VERSION ""

NS_ :

BS_:

BU_: PowertrainControlModule AtmosphericSensor SafetyRestraintSystem2 Aftertreatment_2_GasOutlet Aftertreatment_2_GasIntake DieselParticulateFilterControl Turbocharger SafetyRestraintSystem1 CabDisplay2 Aftertreatment_1_GasOutlet Aftertreatment_1_GasIntake OnBoardDataLogger OffBoardDiagnosticTool2 OffBoardDiagnosticTool1 FileServer ParkingBrakeController SeatController2 FanDriveController SteeringColumnUnit CommunicationUnitRadio CommunicationUnitSatellite CommunicationUnitCellular PropulsionBatteryCharger ChassisController2 ChassisController1 EngineValveControl AuxiliaryHeater2 AuxiliaryHeater1 ClutchUnit RampControl InformationSystem1 SuspensionSystemController2 OilSensor VehicleDynamicStability ExhaustEmissionController TransmissionDisplay2 TransmissionDisplay1 ClimateControl2 WaterPumpController RearAxleSteeringController LightingOperatorControl SeatController1 IgnitionController2 IgnitionController1 TirePressureController CabController2 CabController1 PneumaticSystemController SuspensionSystemController1 HydraulicPumpController EnduranceBrakingSystem RetarderExhaustEngine2 OnBoardDiagnosticUnit HeadwayController RetarderExhaustEngine1 CabDisplay1 ManagementComputer VirtualTerminal OffVehicleGateway PowerTakeOffFront HitchControl AuxiliaryValveControl BodyController TractorTrailerBridge1 StarterSystem ElectricalSystem VehicleSecurity VehicleNavigation AerodynamicControl ElectricalChargingSystem ClimateControl1 TripRecorder InstrumentCluster SuspensionDriveAxle2 SuspensionDriveAxle1 SuspensionSteerAxle SteeringController FuelSystem CruiseControl RetarderDriveline RetarderEngine BrakesDriveAxle2 BrakesDriveAxle1 BrakesSystemController BrakesSteerAxle AxleDrive2 AxleDrive1 AxleSteering PowerTakeOff ShiftConsoleSecondary ShiftConsolePrimary Transmission2 Transmission1 Engine2 Engine1

BO_ 2566741758 DM42: 22 Vector__XXX
 SG_ FlashRedStopLamp : 12|2@1+ (1,0) [0|3] "" Vector__XXX
 SG_ FlashProtectLamp : 8|2@1+ (1,0) [0|3] "" Vector__XXX
 SG_ FlashMalfuncIndicatorLamp : 14|2@1+ (1,0) [0|3] "" Vector__XXX
 SG_ FlashAmberWarningLamp : 10|2@1+ (1,0) [0|3] "" Vector__XXX
 SG_ MalfunctionIndicatorLampStatus : 6|2@1+ (1,0) [0|3] "" Vector__XXX
 SG_ AmberWarningLampStatus : 2|2@1+ (1,0) [0|3] "" Vector__XXX
 SG_ RedStopLampState : 4|2@1+ (1,0) [0|3] "" Vector__XXX
 SG_ ProtectLampStatus : 0|2@1+ (1,0) [0|3] "" Vector__XXX
 SG_ DTC5 : 144|32@1+ (1,0) [0|4294967295] "" Vector__XXX
 SG_ DTC4 : 112|32@1+ (1,0) [0|4294967295] "" Vector__XXX
 SG_ DTC3 : 80|32@1+ (1,0) [0|4294967295] "" Vector__XXX
 SG_ DTC2 : 48|32@1+ (1,0) [0|4294967295] "" Vector__XXX
 SG_ DTC1 : 16|32@1+ (1,0) [0|4294967295] "" Vector__XXX

BO_ 2566742014 DM41: 22 Vector__XXX
 SG_ FlashRedStopLamp : 12|2@1+ (1,0) [0|3] "" Vector__XXX
 SG_ FlashProtectLamp : 8|2@1+ (1,0) [0|3] "" Vector__XXX
 SG_ FlashMalfuncIndicatorLamp : 14|2@1+ (1,0) [0|3] "" Vector__XXX
 SG_ FlashAmberWarningLamp : 10|2@1+ (1,0) [0|3] "" Vector__XXX
 SG_ MalfunctionIndicatorLampStatus : 6|2@1+ (1,0) [0|3] "" Vector__XXX
 SG_ AmberWarningLampStatus : 2|2@1+ (1,0) [0|3] "" Vector__XXX
 SG_ RedStopLampState : 4|2@1+ (1,0) [0|3] "" Vector__XXX
 SG_ ProtectLampStatus : 0|2@1+ (1,0) [0|3] "" Vector__XXX
 SG_ DTC5 : 144|32@1+ (1,0) [0|4294967295] "" Vector__XXX
 SG_ DTC4 : 112|32@1+ (1,0) [0|4294967295] "" Vector__XXX
 SG_ DTC3 : 80|32@1+ (1,0) [0|4294967295] "" Vector__XXX
 SG_ DTC2 : 48|32@1+ (1,0) [0|4294967295] "" Vector__XXX
 SG_ DTC1 : 16|32@1+ (1,0) [0|4294967295] "" Vector__XXX

BO_ 2560622334 DM35: 22 Vector__XXX
 SG_ FlashRedStopLamp : 12|2@1+ (1,0) [0|3] "" Vector__XXX
 SG_ FlashProtectLamp : 8|2@1+ (1,0) [0|3] "" Vector__XXX
 SG_ FlashMalfuncIndicatorLamp : 14|2@1+ (1,0) [0|3] "" Vector__XXX
 SG_ FlashAmberWarningLamp : 10|2@1+ (1,0) [0|3] "" Vector__XXX
 SG_ MalfunctionIndicatorLampStatus : 6|2@1+ (1,0) [0|3] "" Vector__XXX
 SG_ AmberWarningLampStatus : 2|2@1+ (1,0) [0|3] "" Vector__XXX
 SG_ RedStopLampState : 4|2@1+ (1,0) [0|3] "" Vector__XXX
 SG_ ProtectLampStatus : 0|2@1+ (1,0) [0|3] "" Vector__XXX
 SG_ DTC5 : 144|32@1+ (1,0) [0|4294967295] "" Vector__XXX
 SG_ DTC4 : 112|32@1+ (1,0) [0|4294967295] "" Vector__XXX
 SG_ DTC3 : 80|32@1+ (1,0) [0|4294967295] "" Vector__XXX
 SG_ DTC2 : 48|32@1+ (1,0) [0|4294967295] "" Vector__XXX
 SG_ DTC1 : 16|32@1+ (1,0) [0|4294967295] "" Vector__XXX

BO_ 2566744062 ZNVW: 8 Vector__XXX
 SG_ ZeroNetVehicleWeightChange : 0|2@1+ (1,0) [0|3] "" Vector__XXX

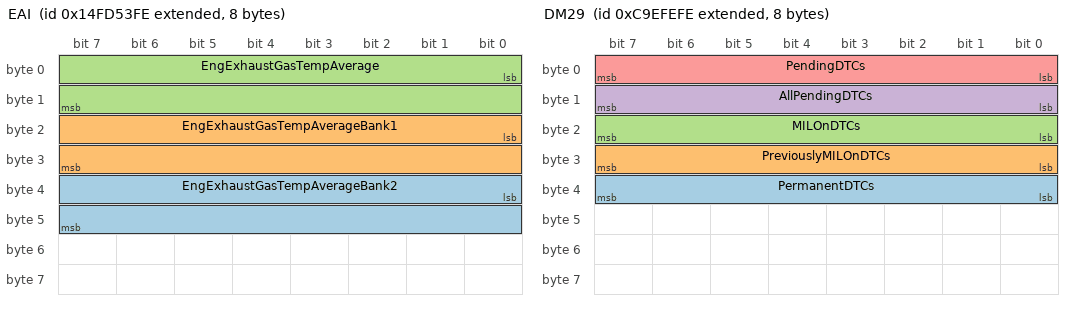
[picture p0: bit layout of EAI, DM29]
BO_ 2499630078 EAI: 8 Vector__XXX
 SG_ EngExhaustGasTempAverageBank2 : 32|16@1+ (0.03125,-273) [-273|1734.96875] "°C" Vector__XXX
 SG_ EngExhaustGasTempAverageBank1 : 16|16@1+ (0.03125,-273) [-273|1734.96875] "°C" Vector__XXX
 SG_ EngExhaustGasTempAverage : 0|16@1+ (0.03125,-273) [-273|1734.96875] "°C" Vector__XXX

BO_ 2359230206 DM29: 8 Vector__XXX
 SG_ PermanentDTCs : 32|8@1+ (1,0) [0|255] "" Vector__XXX
 SG_ PreviouslyMILOnDTCs : 24|8@1+ (1,0) [0|255] "" Vector__XXX
 SG_ MILOnDTCs : 16|8@1+ (1,0) [0|255] "" Vector__XXX
 SG_ AllPendingDTCs : 8|8@1+ (1,0) [0|255] "" Vector__XXX
 SG_ PendingDTCs : 0|8@1+ (1,0) [0|255] "" Vector__XXX

BO_ 2566750462 DM28: 22 Vector__XXX
 SG_ FlashRedStopLamp : 12|2@1+ (1,0) [0|3] "" Vector__XXX
 SG_ FlashProtectLamp : 8|2@1+ (1,0) [0|3] "" Vector__XXX
 SG_ FlashMalfuncIndicatorLamp : 14|2@1+ (1,0) [0|3] "" Vector__XXX
 SG_ FlashAmberWarningLamp : 10|2@1+ (1,0) [0|3] "" Vector__XXX
 SG_ MalfunctionIndicatorLampStatus : 6|2@1+ (1,0) [0|3] "" Vector__XXX
 SG_ AmberWarningLampStatus : 2|2@1+ (1,0) [0|3] "" Vector__XXX
 SG_ RedStopLampState : 4|2@1+ (1,0) [0|3] "" Vector__XXX
 SG_ ProtectLampStatus : 0|2@1+ (1,0) [0|3] "" Vector__XXX
 SG_ DTC5 : 144|32@1+ (1,0) [0|4294967295] "" Vector__XXX
 SG_ DTC4 : 112|32@1+ (1,0) [0|4294967295] "" Vector__XXX
 SG_ DTC3 : 80|32@1+ (1,0) [0|4294967295] "" Vector__XXX
 SG_ DTC2 : 48|32@1+ (1,0) [0|4294967295] "" Vector__XXX
 SG_ DTC1 : 16|32@1+ (1,0) [0|4294967295] "" Vector__XXX

BO_ 2566750974 DM27: 22 Vector__XXX
 SG_ FlashRedStopLamp : 12|2@1+ (1,0) [0|3] "" Vector__XXX
 SG_ FlashProtectLamp : 8|2@1+ (1,0) [0|3] "" Vector__XXX
 SG_ FlashMalfuncIndicatorLamp : 14|2@1+ (1,0) [0|3] "" Vector__XXX
 SG_ FlashAmberWarningLamp : 10|2@1+ (1,0) [0|3] "" Vector__XXX
 SG_ MalfunctionIndicatorLampStatus : 6|2@1+ (1,0) [0|3] "" Vector__XXX
 SG_ AmberWarningLampStatus : 2|2@1+ (1,0) [0|3] "" Vector__XXX
 SG_ RedStopLampState : 4|2@1+ (1,0) [0|3] "" Vector__XXX
 SG_ ProtectLampStatus : 0|2@1+ (1,0) [0|3] "" Vector__XXX
 SG_ DTC5 : 144|32@1+ (1,0) [0|4294967295] "" Vector__XXX
 SG_ DTC4 : 112|32@1+ (1,0) [0|4294967295] "" Vector__XXX
 SG_ DTC3 : 80|32@1+ (1,0) [0|4294967295] "" Vector__XXX
 SG_ DTC2 : 48|32@1+ (1,0) [0|4294967295] "" Vector__XXX
 SG_ DTC1 : 16|32@1+ (1,0) [0|4294967295] "" Vector__XXX

BO_ 2566754558 AETC: 61 Vector__XXX
 SG_ AETCTorqueValue14 : 472|16@1+ (1,0) [0|65535] "Nm" Vector__XXX
 SG_ AETCTorqueValue13 : 440|16@1+ (1,0) [0|65535] "Nm" Vector__XXX
 SG_ AETCTorqueValue12 : 408|16@1+ (1,0) [0|65535] "Nm" Vector__XXX
 SG_ AETCTorqueValue11 : 376|16@1+ (1,0) [0|65535] "Nm" Vector__XXX
 SG_ AETCTorqueValue10 : 344|16@1+ (1,0) [0|65535] "Nm" Vector__XXX
 SG_ AETCTorqueValue09 : 312|16@1+ (1,0) [0|65535] "Nm" Vector__XXX
 SG_ AETCTorqueValue08 : 280|16@1+ (1,0) [0|65535] "Nm" Vector__XXX
 SG_ AETCTorqueValue07 : 248|16@1+ (1,0) [0|65535] "Nm" Vector__XXX
 SG_ AETCTorqueValue06 : 216|16@1+ (1,0) [0|65535] "Nm" Vector__XXX
 SG_ AETCTorqueValue05 : 184|16@1+ (1,0) [0|65535] "Nm" Vector__XXX
 SG_ AETCTorqueValue04 : 152|16@1+ (1,0) [0|65535] "Nm" Vector__XXX
 SG_ AETCTorqueValue03 : 120|16@1+ (1,0) [0|65535] "Nm" Vector__XXX
 SG_ AETCTorqueValue02 : 88|16@1+ (1,0) [0|65535] "Nm" Vector__XXX
 SG_ AETCTorqueValue01 : 56|16@1+ (1,0) [0|65535] "Nm" Vector__XXX
 SG_ AETCSpeedValue14 : 456|16@1+ (0.125,0) [0|8191.875] "rpm" Vector__XXX
 SG_ AETCSpeedValue13 : 424|16@1+ (0.125,0) [0|8191.875] "rpm" Vector__XXX
 SG_ AETCSpeedValue12 : 392|16@1+ (0.125,0) [0|8191.875] "rpm" Vector__XXX
 SG_ AETCSpeedValue11 : 360|16@1+ (0.125,0) [0|8191.875] "rpm" Vector__XXX
 SG_ AETCSpeedValue10 : 328|16@1+ (0.125,0) [0|8191.875] "rpm" Vector__XXX
 SG_ AETCSpeedValue09 : 296|16@1+ (0.125,0) [0|8191.875] "rpm" Vector__XXX
 SG_ AETCSpeedValue08 : 264|16@1+ (0.125,0) [0|8191.875] "rpm" Vector__XXX
 SG_ AETCSpeedValue07 : 232|16@1+ (0.125,0) [0|8191.875] "rpm" Vector__XXX
 SG_ AETCSpeedValue06 : 200|16@1+ (0.125,0) [0|8191.875] "rpm" Vector__XXX
 SG_ AETCSpeedValue05 : 168|16@1+ (0.125,0) [0|8191.875] "rpm" Vector__XXX
 SG_ AETCSpeedValue04 : 136|16@1+ (0.125,0) [0|8191.875] "rpm" Vector__XXX
 SG_ AETCSpeedValue03 : 104|16@1+ (0.125,0) [0|8191.875] "rpm" Vector__XXX
 SG_ AETCSpeedValue02 : 72|16@1+ (0.125,0) [0|8191.875] "rpm" Vector__XXX
 SG_ AETCSpeedValue01 : 40|16@1+ (0.125,0) [0|8191.875] "rpm" Vector__XXX
 SG_ AETCTorqueValue00 : 24|16@1+ (1,0) [0|65535] "Nm" Vector__XXX
 SG_ AETCSpeedValue00 : 8|16@1+ (0.125,0) [0|8191.875] "rpm" Vector__XXX
 SG_ NumberOfAETCDataPoints : 4|4@1+ (1,0) [5|15] "" Vector__XXX
 SG_ AETCDataCollectionStandard : 0|4@1+ (1,0) [0|15] "" Vector__XXX

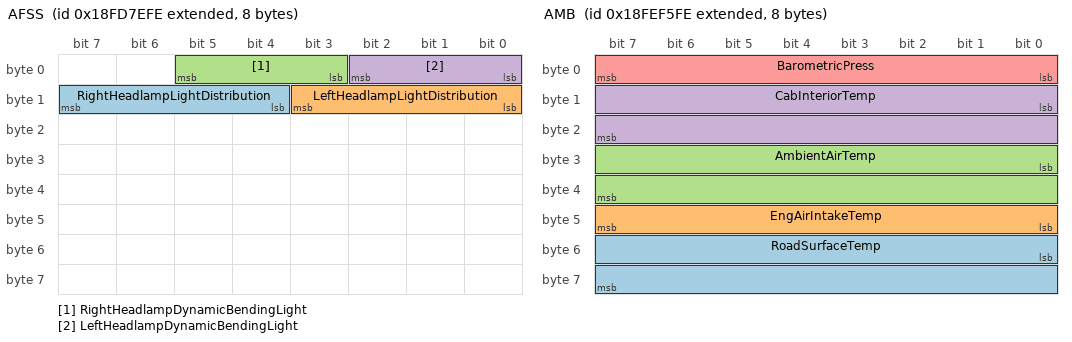
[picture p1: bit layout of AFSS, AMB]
BO_ 2566749950 AFSS: 8 Vector__XXX
 SG_ RightHeadlampLightDistribution : 12|4@1+ (1,0) [0|15] "" Vector__XXX
 SG_ LeftHeadlampLightDistribution : 8|4@1+ (1,0) [0|15] "" Vector__XXX
 SG_ RightHeadlampDynamicBendingLight : 3|3@1+ (1,0) [0|7] "" Vector__XXX
 SG_ LeftHeadlampDynamicBendingLight : 0|3@1+ (1,0) [0|7] "" Vector__XXX

BO_ 2566838782 AUXIO1: 8 Vector__XXX
 SG_ AuxI_OChannel2 : 48|16@1+ (1,0) [0|64255] "" Vector__XXX
 SG_ AuxI_OChannel1 : 32|16@1+ (1,0) [0|64255] "" Vector__XXX
 SG_ AuxI_O13 : 30|2@1+ (1,0) [0|3] "" Vector__XXX
 SG_ AuxI_O14 : 28|2@1+ (1,0) [0|3] "" Vector__XXX
 SG_ AuxI_O15 : 26|2@1+ (1,0) [0|3] "" Vector__XXX
 SG_ AuxI_O16 : 24|2@1+ (1,0) [0|3] "" Vector__XXX
 SG_ AuxI_O09 : 22|2@1+ (1,0) [0|3] "" Vector__XXX
 SG_ AuxI_O10 : 20|2@1+ (1,0) [0|3] "" Vector__XXX
 SG_ AuxI_O11 : 18|2@1+ (1,0) [0|3] "" Vector__XXX
 SG_ AuxI_O12 : 16|2@1+ (1,0) [0|3] "" Vector__XXX
 SG_ AuxI_O05 : 14|2@1+ (1,0) [0|3] "" Vector__XXX
 SG_ AuxI_O06 : 12|2@1+ (1,0) [0|3] "" Vector__XXX
 SG_ AuxI_O07 : 10|2@1+ (1,0) [0|3] "" Vector__XXX
 SG_ AuxI_O08 : 8|2@1+ (1,0) [0|3] "" Vector__XXX
 SG_ AuxI_O01 : 6|2@1+ (1,0) [0|3] "" Vector__XXX
 SG_ AuxI_O02 : 4|2@1+ (1,0) [0|3] "" Vector__XXX
 SG_ AuxI_O03 : 2|2@1+ (1,0) [0|3] "" Vector__XXX
 SG_ AuxI_O04 : 0|2@1+ (1,0) [0|3] "" Vector__XXX

BO_ 2561146622 AUXIO2: 8 Vector__XXX
 SG_ AuxI_O45 : 62|2@1+ (1,0) [0|3] "" Vector__XXX
 SG_ AuxI_O46 : 60|2@1+ (1,0) [0|3] "" Vector__XXX
 SG_ AuxI_O47 : 58|2@1+ (1,0) [0|3] "" Vector__XXX
 SG_ AuxI_O48 : 56|2@1+ (1,0) [0|3] "" Vector__XXX
 SG_ AuxI_O41 : 54|2@1+ (1,0) [0|3] "" Vector__XXX
 SG_ AuxI_O42 : 52|2@1+ (1,0) [0|3] "" Vector__XXX
 SG_ AuxI_O43 : 50|2@1+ (1,0) [0|3] "" Vector__XXX
 SG_ AuxI_O44 : 48|2@1+ (1,0) [0|3] "" Vector__XXX
 SG_ AuxI_O37 : 46|2@1+ (1,0) [0|3] "" Vector__XXX
 SG_ AuxI_O38 : 44|2@1+ (1,0) [0|3] "" Vector__XXX
 SG_ AuxI_O39 : 42|2@1+ (1,0) [0|3] "" Vector__XXX
 SG_ AuxI_O40 : 40|2@1+ (1,0) [0|3] "" Vector__XXX
 SG_ AuxI_O33 : 38|2@1+ (1,0) [0|3] "" Vector__XXX
 SG_ AuxI_O34 : 36|2@1+ (1,0) [0|3] "" Vector__XXX
 SG_ AuxI_O35 : 34|2@1+ (1,0) [0|3] "" Vector__XXX
 SG_ AuxI_O36 : 32|2@1+ (1,0) [0|3] "" Vector__XXX
 SG_ AuxI_O29 : 30|2@1+ (1,0) [0|3] "" Vector__XXX
 SG_ AuxI_O30 : 28|2@1+ (1,0) [0|3] "" Vector__XXX
 SG_ AuxI_O31 : 26|2@1+ (1,0) [0|3] "" Vector__XXX
 SG_ AuxI_O32 : 24|2@1+ (1,0) [0|3] "" Vector__XXX
 SG_ AuxI_O25 : 22|2@1+ (1,0) [0|3] "" Vector__XXX
 SG_ AuxI_O26 : 20|2@1+ (1,0) [0|3] "" Vector__XXX
 SG_ AuxI_O27 : 18|2@1+ (1,0) [0|3] "" Vector__XXX
 SG_ AuxI_O28 : 16|2@1+ (1,0) [0|3] "" Vector__XXX
 SG_ AuxI_O21 : 14|2@1+ (1,0) [0|3] "" Vector__XXX
 SG_ AuxI_O22 : 12|2@1+ (1,0) [0|3] "" Vector__XXX
 SG_ AuxI_O23 : 10|2@1+ (1,0) [0|3] "" Vector__XXX
 SG_ AuxI_O24 : 8|2@1+ (1,0) [0|3] "" Vector__XXX
 SG_ AuxI_O17 : 6|2@1+ (1,0) [0|3] "" Vector__XXX
 SG_ AuxI_O18 : 4|2@1+ (1,0) [0|3] "" Vector__XXX
 SG_ AuxI_O19 : 2|2@1+ (1,0) [0|3] "" Vector__XXX
 SG_ AuxI_O20 : 0|2@1+ (1,0) [0|3] "" Vector__XXX

BO_ 2561081086 AUXIO3: 8 Vector__XXX
 SG_ AuxI_O77 : 62|2@1+ (1,0) [0|3] "" Vector__XXX
 SG_ AuxI_O78 : 60|2@1+ (1,0) [0|3] "" Vector__XXX
 SG_ AuxI_O79 : 58|2@1+ (1,0) [0|3] "" Vector__XXX
 SG_ AuxI_O80 : 56|2@1+ (1,0) [0|3] "" Vector__XXX
 SG_ AuxI_O73 : 54|2@1+ (1,0) [0|3] "" Vector__XXX
 SG_ AuxI_O74 : 52|2@1+ (1,0) [0|3] "" Vector__XXX
 SG_ AuxI_O75 : 50|2@1+ (1,0) [0|3] "" Vector__XXX
 SG_ AuxI_O76 : 48|2@1+ (1,0) [0|3] "" Vector__XXX
 SG_ AuxI_O69 : 46|2@1+ (1,0) [0|3] "" Vector__XXX
 SG_ AuxI_O70 : 44|2@1+ (1,0) [0|3] "" Vector__XXX
 SG_ AuxI_O71 : 42|2@1+ (1,0) [0|3] "" Vector__XXX
 SG_ AuxI_O72 : 40|2@1+ (1,0) [0|3] "" Vector__XXX
 SG_ AuxI_O65 : 38|2@1+ (1,0) [0|3] "" Vector__XXX
 SG_ AuxI_O66 : 36|2@1+ (1,0) [0|3] "" Vector__XXX
 SG_ AuxI_O67 : 34|2@1+ (1,0) [0|3] "" Vector__XXX
 SG_ AuxI_O68 : 32|2@1+ (1,0) [0|3] "" Vector__XXX
 SG_ AuxI_O61 : 30|2@1+ (1,0) [0|3] "" Vector__XXX
 SG_ AuxI_O62 : 28|2@1+ (1,0) [0|3] "" Vector__XXX
 SG_ AuxI_O63 : 26|2@1+ (1,0) [0|3] "" Vector__XXX
 SG_ AuxI_O64 : 24|2@1+ (1,0) [0|3] "" Vector__XXX
 SG_ AuxI_O57 : 22|2@1+ (1,0) [0|3] "" Vector__XXX
 SG_ AuxI_O58 : 20|2@1+ (1,0) [0|3] "" Vector__XXX
 SG_ AuxI_O59 : 18|2@1+ (1,0) [0|3] "" Vector__XXX
 SG_ AuxI_O60 : 16|2@1+ (1,0) [0|3] "" Vector__XXX
 SG_ AuxI_O53 : 14|2@1+ (1,0) [0|3] "" Vector__XXX
 SG_ AuxI_O54 : 12|2@1+ (1,0) [0|3] "" Vector__XXX
 SG_ AuxI_O55 : 10|2@1+ (1,0) [0|3] "" Vector__XXX
 SG_ AuxI_O56 : 8|2@1+ (1,0) [0|3] "" Vector__XXX
 SG_ AuxI_O49 : 6|2@1+ (1,0) [0|3] "" Vector__XXX
 SG_ AuxI_O50 : 4|2@1+ (1,0) [0|3] "" Vector__XXX
 SG_ AuxI_O51 : 2|2@1+ (1,0) [0|3] "" Vector__XXX
 SG_ AuxI_O52 : 0|2@1+ (1,0) [0|3] "" Vector__XXX

BO_ 2561015550 AUXIO4: 8 Vector__XXX
 SG_ AuxI_O109 : 62|2@1+ (1,0) [0|3] "" Vector__XXX
 SG_ AuxI_O110 : 60|2@1+ (1,0) [0|3] "" Vector__XXX
 SG_ AuxI_O111 : 58|2@1+ (1,0) [0|3] "" Vector__XXX
 SG_ AuxI_O112 : 56|2@1+ (1,0) [0|3] "" Vector__XXX
 SG_ AuxI_O105 : 54|2@1+ (1,0) [0|3] "" Vector__XXX
 SG_ AuxI_O106 : 52|2@1+ (1,0) [0|3] "" Vector__XXX
 SG_ AuxI_O107 : 50|2@1+ (1,0) [0|3] "" Vector__XXX
 SG_ AuxI_O108 : 48|2@1+ (1,0) [0|3] "" Vector__XXX
 SG_ AuxI_O101 : 46|2@1+ (1,0) [0|3] "" Vector__XXX
 SG_ AuxI_O102 : 44|2@1+ (1,0) [0|3] "" Vector__XXX
 SG_ AuxI_O103 : 42|2@1+ (1,0) [0|3] "" Vector__XXX
 SG_ AuxI_O104 : 40|2@1+ (1,0) [0|3] "" Vector__XXX
 SG_ AuxI_O97 : 38|2@1+ (1,0) [0|3] "" Vector__XXX
 SG_ AuxI_O98 : 36|2@1+ (1,0) [0|3] "" Vector__XXX
 SG_ AuxI_O99 : 34|2@1+ (1,0) [0|3] "" Vector__XXX
 SG_ AuxI_O100 : 32|2@1+ (1,0) [0|3] "" Vector__XXX
 SG_ AuxI_O93 : 30|2@1+ (1,0) [0|3] "" Vector__XXX
 SG_ AuxI_O94 : 28|2@1+ (1,0) [0|3] "" Vector__XXX
 SG_ AuxI_O95 : 26|2@1+ (1,0) [0|3] "" Vector__XXX
 SG_ AuxI_O96 : 24|2@1+ (1,0) [0|3] "" Vector__XXX
 SG_ AuxI_O89 : 22|2@1+ (1,0) [0|3] "" Vector__XXX
 SG_ AuxI_O90 : 20|2@1+ (1,0) [0|3] "" Vector__XXX
 SG_ AuxI_O91 : 18|2@1+ (1,0) [0|3] "" Vector__XXX
 SG_ AuxI_O92 : 16|2@1+ (1,0) [0|3] "" Vector__XXX
 SG_ AuxI_O85 : 14|2@1+ (1,0) [0|3] "" Vector__XXX
 SG_ AuxI_O86 : 12|2@1+ (1,0) [0|3] "" Vector__XXX
 SG_ AuxI_O87 : 10|2@1+ (1,0) [0|3] "" Vector__XXX
 SG_ AuxI_O88 : 8|2@1+ (1,0) [0|3] "" Vector__XXX
 SG_ AuxI_O81 : 6|2@1+ (1,0) [0|3] "" Vector__XXX
 SG_ AuxI_O82 : 4|2@1+ (1,0) [0|3] "" Vector__XXX
 SG_ AuxI_O83 : 2|2@1+ (1,0) [0|3] "" Vector__XXX
 SG_ AuxI_O84 : 0|2@1+ (1,0) [0|3] "" Vector__XXX

BO_ 2566746622 BSA: 8 Vector__XXX
 SG_ TrailerBrakeStrokeAxle5Right : 57|3@1+ (1,0) [0|7] "" Vector__XXX
 SG_ TrailerBrakeStrokeAxle5Left : 54|3@1+ (1,0) [0|7] "" Vector__XXX
 SG_ TrailerBrakeStrokeAxle4Right : 51|3@1+ (1,0) [0|7] "" Vector__XXX
 SG_ TrailerBrakeStrokeAxle4Left : 48|3@1+ (1,0) [0|7] "" Vector__XXX
 SG_ TrailerBrakeStrokeAxle3Right : 45|3@1+ (1,0) [0|7] "" Vector__XXX
 SG_ TrailerBrakeStrokeAxle3Left : 42|3@1+ (1,0) [0|7] "" Vector__XXX
 SG_ TrailerBrakeStrokeAxle2Right : 39|3@1+ (1,0) [0|7] "" Vector__XXX
 SG_ TrailerBrakeStrokeAxle2Left : 36|3@1+ (1,0) [0|7] "" Vector__XXX
 SG_ TrailerBrakeStrokeAxle1Right : 33|3@1+ (1,0) [0|7] "" Vector__XXX
 SG_ TrailerBrakeStrokeAxle1Left : 30|3@1+ (1,0) [0|7] "" Vector__XXX
 SG_ TractorBrakeStrokeAxle5Right : 27|3@1+ (1,0) [0|7] "" Vector__XXX
 SG_ TractorBrakeStrokeAxle5Left : 24|3@1+ (1,0) [0|7] "" Vector__XXX
 SG_ TractorBrakeStrokeAxle4Right : 21|3@1+ (1,0) [0|7] "" Vector__XXX
 SG_ TractorBrakeStrokeAxle4Left : 18|3@1+ (1,0) [0|7] "" Vector__XXX
 SG_ TractorBrakeStrokeAxle3Right : 15|3@1+ (1,0) [0|7] "" Vector__XXX
 SG_ TractorBrakeStrokeAxle3Left : 12|3@1+ (1,0) [0|7] "" Vector__XXX
 SG_ TractorBrakeStrokeAxle2Right : 9|3@1+ (1,0) [0|7] "" Vector__XXX
 SG_ TractorBrakeStrokeAxle2Left : 6|3@1+ (1,0) [0|7] "" Vector__XXX
 SG_ TractorBrakeStrokeAxle1Right : 3|3@1+ (1,0) [0|7] "" Vector__XXX
 SG_ TractorBrakeStrokeAxle1Left : 0|3@1+ (1,0) [0|7] "" Vector__XXX

BO_ 2566845950 AMB: 8 Vector__XXX
 SG_ RoadSurfaceTemp : 48|16@1+ (0.03125,-273) [-273|1734.96875] "°C" Vector__XXX
 SG_ EngAirIntakeTemp : 40|8@1+ (1,-40) [-40|210] "°C" Vector__XXX
 SG_ AmbientAirTemp : 24|16@1+ (0.03125,-273) [-273|1734.96875] "°C" Vector__XXX
 SG_ CabInteriorTemp : 8|16@1+ (0.03125,-273) [-273|1734.96875] "°C" Vector__XXX
 SG_ BarometricPress : 0|8@1+ (0.5,0) [0|125] "kPa" Vector__XXX

BO_ 2566840062 AIR2: 8 Vector__XXX
 SG_ EngAirStartPress : 0|8@1+ (4,0) [0|1000] "kPa" Vector__XXX

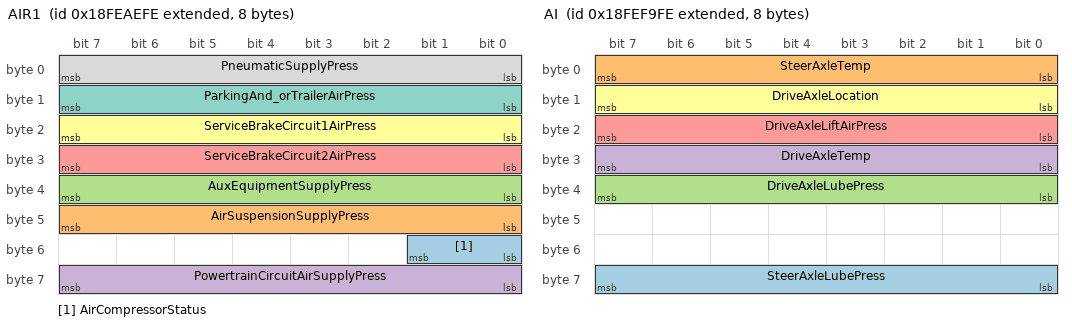
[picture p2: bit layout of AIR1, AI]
BO_ 2566827774 AIR1: 8 Vector__XXX
 SG_ AirCompressorStatus : 48|2@1+ (1,0) [0|3] "" Vector__XXX
 SG_ AirSuspensionSupplyPress : 40|8@1+ (8,0) [0|2000] "kPa" Vector__XXX
 SG_ AuxEquipmentSupplyPress : 32|8@1+ (8,0) [0|2000] "kPa" Vector__XXX
 SG_ PowertrainCircuitAirSupplyPress : 56|8@1+ (8,0) [0|2000] "kPa" Vector__XXX
 SG_ ServiceBrakeCircuit2AirPress : 24|8@1+ (8,0) [0|2000] "kPa" Vector__XXX
 SG_ ServiceBrakeCircuit1AirPress : 16|8@1+ (8,0) [0|2000] "kPa" Vector__XXX
 SG_ ParkingAnd_orTrailerAirPress : 8|8@1+ (8,0) [0|2000] "kPa" Vector__XXX
 SG_ PneumaticSupplyPress : 0|8@1+ (8,0) [0|2000] "kPa" Vector__XXX

BO_ 2566846974 AI: 8 Vector__XXX
 SG_ SteerAxleLubePress : 56|8@1+ (4,0) [0|1000] "kPa" Vector__XXX
 SG_ SteerAxleTemp : 0|8@1+ (1,-40) [-40|210] "°C" Vector__XXX
 SG_ DriveAxleLubePress : 32|8@1+ (4,0) [0|1000] "kPa" Vector__XXX
 SG_ DriveAxleTemp : 24|8@1+ (1,-40) [-40|210] "°C" Vector__XXX
 SG_ DriveAxleLiftAirPress : 16|8@1+ (4,0) [0|1000] "kPa" Vector__XXX
 SG_ DriveAxleLocation : 8|8@1+ (1,0) [0|255] "" Vector__XXX

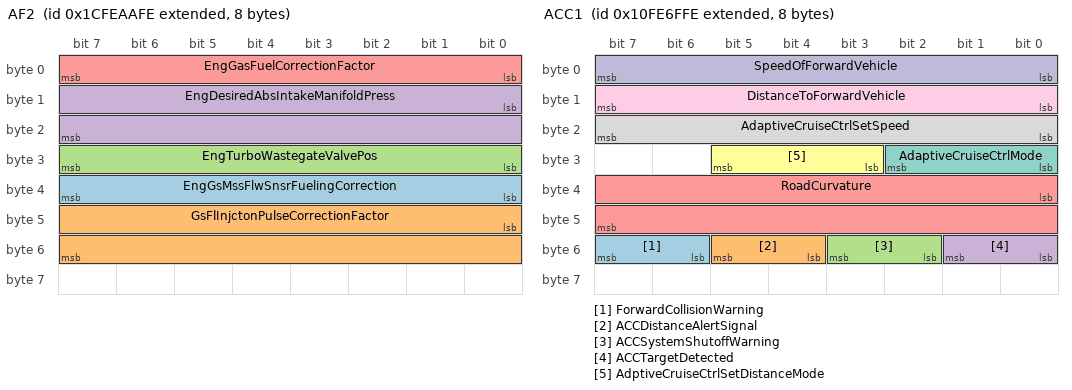
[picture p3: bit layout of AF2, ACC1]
BO_ 2633935614 AF2: 8 Vector__XXX
 SG_ EngGsMssFlwSnsrFuelingCorrection : 32|8@1+ (1,-125) [-125|125] "%" Vector__XXX
 SG_ GsFlInjctonPulseCorrectionFactor : 40|16@1+ (0.0078125,-251) [0|150] "%" Vector__XXX
 SG_ EngTurboWastegateValvePos : 24|8@1+ (0.4,0) [0|100] "%" Vector__XXX
 SG_ EngDesiredAbsIntakeManifoldPress : 8|16@1+ (0.1,0) [0|6425.5] "kPa" Vector__XXX
 SG_ EngGasFuelCorrectionFactor : 0|8@1+ (1,0) [0|250] "%" Vector__XXX

BO_ 2566803966 ACC2: 8 Vector__XXX
 SG_ RequestedACCDistanceMode : 5|3@1+ (1,0) [0|7] "" Vector__XXX
 SG_ ACCUsageDemand : 0|2@1+ (1,0) [0|3] "" Vector__XXX

BO_ 2432593918 ACC1: 8 Vector__XXX
 SG_ ForwardCollisionWarning : 54|2@1+ (1,0) [0|3] "" Vector__XXX
 SG_ ACCDistanceAlertSignal : 52|2@1+ (1,0) [0|3] "" Vector__XXX
 SG_ ACCSystemShutoffWarning : 50|2@1+ (1,0) [0|3] "" Vector__XXX
 SG_ ACCTargetDetected : 48|2@1+ (1,0) [0|3] "" Vector__XXX
 SG_ RoadCurvature : 32|16@1+ (0.0078125,-250) [-250|251.992] "1/km" Vector__XXX
 SG_ AdptiveCruiseCtrlSetDistanceMode : 27|3@1+ (1,0) [0|7] "" Vector__XXX
 SG_ AdaptiveCruiseCtrlMode : 24|3@1+ (1,0) [0|7] "" Vector__XXX
 SG_ AdaptiveCruiseCtrlSetSpeed : 16|8@1+ (1,0) [0|120] "km/h" Vector__XXX
 SG_ DistanceToForwardVehicle : 8|8@1+ (1,0) [0|250] "m" Vector__XXX
 SG_ SpeedOfForwardVehicle : 0|8@1+ (1,0) [0|250] "km/h" Vector__XXX

BO_ 2633935102 ACTL: 8 Vector__XXX
 SG_ ArticulationAngle : 0|8@1+ (1,-125) [-125|125] "deg" Vector__XXX

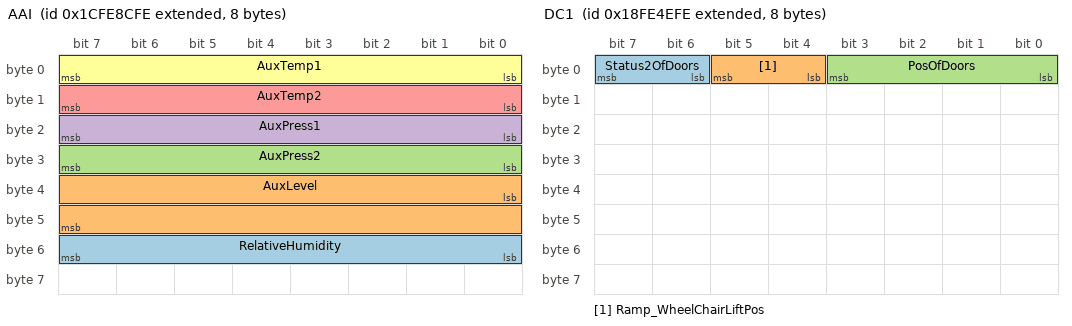
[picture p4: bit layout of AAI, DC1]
BO_ 2633927934 AAI: 8 Vector__XXX
 SG_ RelativeHumidity : 48|8@1+ (0.4,0) [0|100] "%" Vector__XXX
 SG_ AuxLevel : 32|16@1+ (0.1,0) [0|6425.5] "mm" Vector__XXX
 SG_ AuxPress2 : 24|8@1+ (16,0) [0|4000] "kPa" Vector__XXX
 SG_ AuxPress1 : 16|8@1+ (16,0) [0|4000] "kPa" Vector__XXX
 SG_ AuxTemp2 : 8|8@1+ (1,-40) [-40|210] "°C" Vector__XXX
 SG_ AuxTemp1 : 0|8@1+ (1,-40) [-40|210] "°C" Vector__XXX

BO_ 2566847998 A1: 8 Vector__XXX
 SG_ EngBlowerBypassValvePos : 0|8@1+ (0.4,0) [0|100] "%" Vector__XXX
 SG_ EngGasSupplyPress : 8|16@1+ (0.5,0) [0|32127.5] "kPa" Vector__XXX

BO_ 2364079870 ACKM: 8 Vector__XXX
 SG_ AddressBusy m3 : 32|8@1+ (1,0) [0|255] "" Vector__XXX
 SG_ ControlByte M : 0|8@1+ (1,0) [0|255] "" Vector__XXX
 SG_ ParameterGroupNumber : 40|24@1+ (1,0) [0|16777215] "" Vector__XXX
 SG_ GroupFunctionValue : 8|8@1+ (1,0) [0|255] "" Vector__XXX
 SG_ AddressAccessDenied m2 : 32|8@1+ (1,0) [0|255] "" Vector__XXX
 SG_ AddressNegativeAcknowledgement m1 : 32|8@1+ (1,0) [0|255] "" Vector__XXX
 SG_ AddressAcknowledged m0 : 32|8@1+ (1,0) [0|255] "" Vector__XXX

BO_ 2566803198 DC1: 8 Vector__XXX
 SG_ Status2OfDoors : 6|2@1+ (1,0) [0|3] "" Vector__XXX
 SG_ Ramp_WheelChairLiftPos : 4|2@1+ (1,0) [0|3] "" Vector__XXX
 SG_ PosOfDoors : 0|4@1+ (1,0) [0|15] "" Vector__XXX

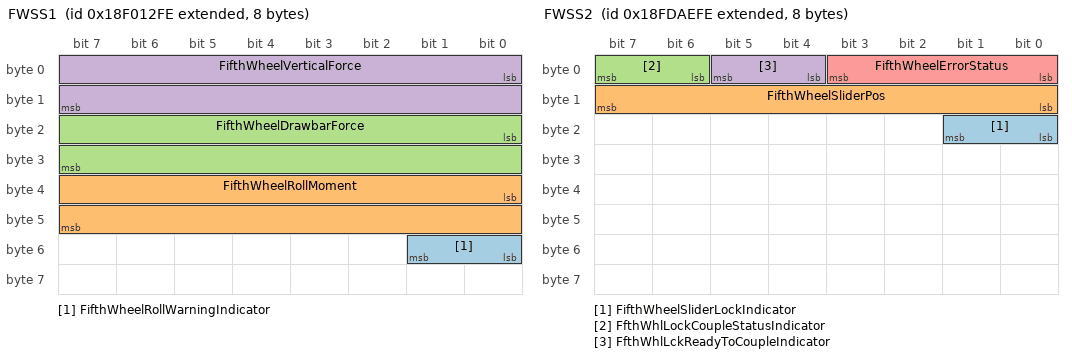
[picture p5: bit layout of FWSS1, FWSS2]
BO_ 2565870334 FWSS1: 8 Vector__XXX
 SG_ FifthWheelRollWarningIndicator : 48|2@1+ (1,0) [0|3] "" Vector__XXX
 SG_ FifthWheelRollMoment : 32|16@1+ (10,-320000) [-320000|322550] "N" Vector__XXX
 SG_ FifthWheelDrawbarForce : 16|16@1+ (10,-320000) [-320000|322550] "N" Vector__XXX
 SG_ FifthWheelVerticalForce : 0|16@1+ (5,0) [0|321275] "N" Vector__XXX

BO_ 2566762238 FWSS2: 8 Vector__XXX
 SG_ FifthWheelSliderLockIndicator : 16|2@1+ (1,0) [0|3] "" Vector__XXX
 SG_ FifthWheelSliderPos : 8|8@1+ (10,0) [0|2500] "mm" Vector__XXX
 SG_ FfthWhlLockCoupleStatusIndicator : 6|2@1+ (1,0) [0|3] "" Vector__XXX
 SG_ FfthWhlLckReadyToCoupleIndicator : 4|2@1+ (1,0) [0|3] "" Vector__XXX
 SG_ FifthWheelErrorStatus : 0|4@1+ (1,0) [0|15] "" Vector__XXX

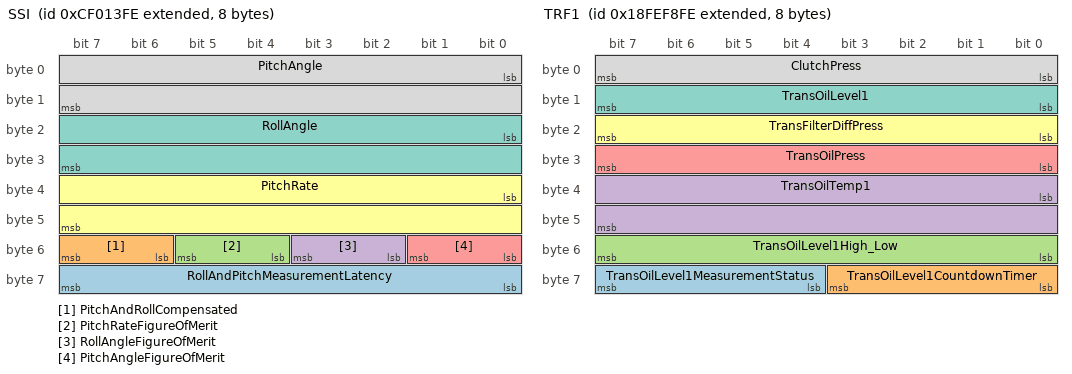
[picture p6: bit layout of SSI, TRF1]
BO_ 2364543998 SSI: 8 Vector__XXX
 SG_ RollAndPitchMeasurementLatency : 56|8@1+ (0.5,0) [0|125] "ms" Vector__XXX
 SG_ PitchAndRollCompensated : 54|2@1+ (1,0) [0|3] "" Vector__XXX
 SG_ PitchRateFigureOfMerit : 52|2@1+ (1,0) [0|3] "" Vector__XXX
 SG_ RollAngleFigureOfMerit : 50|2@1+ (1,0) [0|3] "" Vector__XXX
 SG_ PitchAngleFigureOfMerit : 48|2@1+ (1,0) [0|3] "" Vector__XXX
 SG_ PitchRate : 32|16@1+ (0.002,-64) [-64|64.51] "deg/sec" Vector__XXX
 SG_ RollAngle : 16|16@1+ (0.002,-64) [-64|64.51] "deg" Vector__XXX
 SG_ PitchAngle : 0|16@1+ (0.002,-64) [-64|64.51] "deg" Vector__XXX

BO_ 2566846718 TRF1: 8 Vector__XXX
 SG_ TransOilLevel1MeasurementStatus : 60|4@1+ (1,0) [0|15] "" Vector__XXX
 SG_ TransOilLevel1CountdownTimer : 56|4@1+ (1,0) [0|13] "" Vector__XXX
 SG_ TransOilLevel1High_Low : 48|8@1+ (0.5,-62.5) [-62.5|62.5] "L" Vector__XXX
 SG_ TransOilTemp1 : 32|16@1+ (0.03125,-273) [-273|1734.96875] "°C" Vector__XXX
 SG_ TransOilPress : 24|8@1+ (16,0) [0|4000] "kPa" Vector__XXX
 SG_ TransFilterDiffPress : 16|8@1+ (2,0) [0|500] "kPa" Vector__XXX
 SG_ TransOilLevel1 : 8|8@1+ (0.4,0) [0|100] "%" Vector__XXX
 SG_ ClutchPress : 0|8@1+ (16,0) [0|4000] "kPa" Vector__XXX

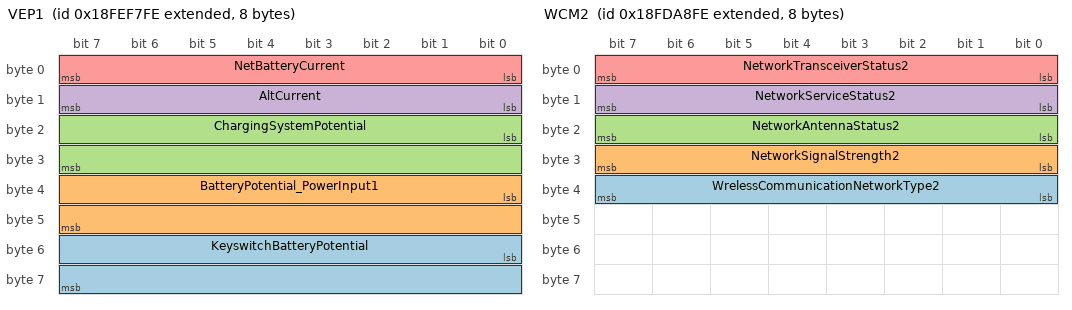
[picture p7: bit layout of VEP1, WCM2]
BO_ 2566846462 VEP1: 8 Vector__XXX
 SG_ KeyswitchBatteryPotential : 48|16@1+ (0.05,0) [0|3212.75] "V" Vector__XXX
 SG_ BatteryPotential_PowerInput1 : 32|16@1+ (0.05,0) [0|3212.75] "V" Vector__XXX
 SG_ ChargingSystemPotential : 16|16@1+ (0.05,0) [0|3212.75] "V" Vector__XXX
 SG_ AltCurrent : 8|8@1+ (1,0) [0|250] "A" Vector__XXX
 SG_ NetBatteryCurrent : 0|8@1+ (1,-125) [-125|125] "A" Vector__XXX

BO_ 2566760702 WCM2: 8 Vector__XXX
 SG_ WrelessCommunicationNetworkType2 : 32|8@1+ (1,0) [0|255] "" Vector__XXX
 SG_ NetworkSignalStrength2 : 24|8@1+ (0.4,0) [0|100] "%" Vector__XXX
 SG_ NetworkAntennaStatus2 : 16|8@1+ (1,0) [0|255] "" Vector__XXX
 SG_ NetworkServiceStatus2 : 8|8@1+ (1,0) [0|255] "" Vector__XXX
 SG_ NetworkTransceiverStatus2 : 0|8@1+ (1,0) [0|255] "" Vector__XXX

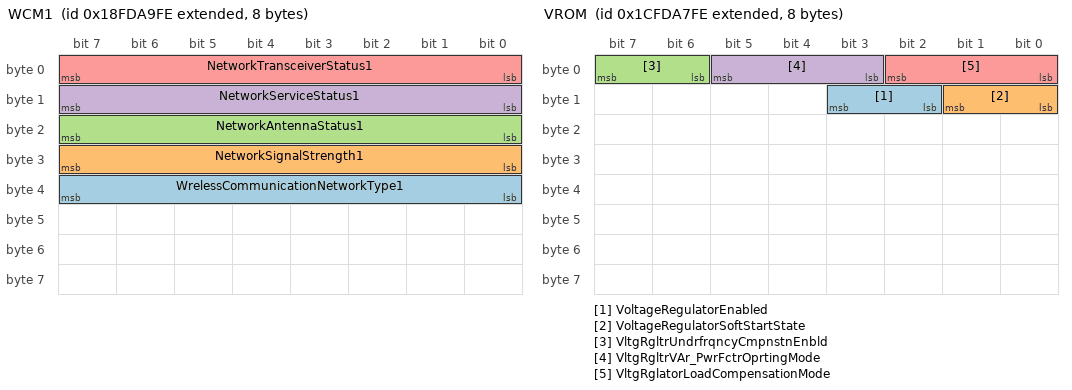
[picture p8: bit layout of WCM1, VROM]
BO_ 2566760958 WCM1: 8 Vector__XXX
 SG_ WrelessCommunicationNetworkType1 : 32|8@1+ (1,0) [0|255] "" Vector__XXX
 SG_ NetworkSignalStrength1 : 24|8@1+ (0.4,0) [0|100] "%" Vector__XXX
 SG_ NetworkAntennaStatus1 : 16|8@1+ (1,0) [0|255] "" Vector__XXX
 SG_ NetworkServiceStatus1 : 8|8@1+ (1,0) [0|255] "" Vector__XXX
 SG_ NetworkTransceiverStatus1 : 0|8@1+ (1,0) [0|255] "" Vector__XXX

BO_ 2633869310 VROM: 8 Vector__XXX
 SG_ VoltageRegulatorEnabled : 10|2@1+ (1,0) [0|3] "" Vector__XXX
 SG_ VoltageRegulatorSoftStartState : 8|2@1+ (1,0) [0|3] "" Vector__XXX
 SG_ VltgRgltrUndrfrqncyCmpnstnEnbld : 6|2@1+ (1,0) [0|3] "" Vector__XXX
 SG_ VltgRgltrVAr_PwrFctrOprtingMode : 3|3@1+ (1,0) [0|7] "" Vector__XXX
 SG_ VltgRglatorLoadCompensationMode : 0|3@1+ (1,0) [0|7] "" Vector__XXX

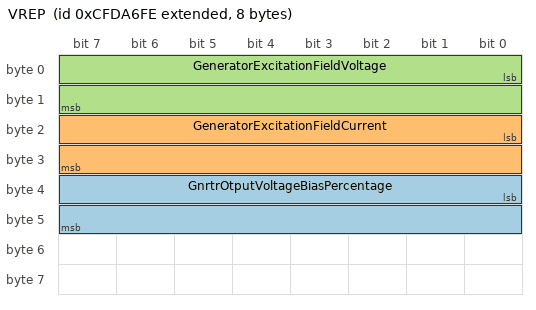
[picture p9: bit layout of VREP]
BO_ 2365433598 VREP: 8 Vector__XXX
 SG_ GnrtrOtputVoltageBiasPercentage : 32|16@1+ (0.1,-100) [-100|100] "%" Vector__XXX
 SG_ GeneratorExcitationFieldCurrent : 16|16@1+ (0.05,0) [0|3212.75] "A" Vector__XXX
 SG_ GeneratorExcitationFieldVoltage : 0|16@1+ (0.05,-1606) [-1606|1606.75] "V" Vector__XXX

CM_ BO_ 3221225472 "This is a message for not used signals, created by Vector CANdb++ DBC OLE DB Provider.";
CM_ SG_ 3221225472 NumberOfMembersInWorkingSet "The number of members in a particular Working Set.";
CM_ SG_ 3221225472 NncntnuslyMonitoredSystemsStatus "Identifies the non-continuously monitored systems status. Each bit identifies whether a particular test is complete for a given controller.
";
CM_ SG_ 3221225472 NncntnslyMonitoredSystemsSupport "Identifies the non-continuously monitored systems support.
";
CM_ SG_ 3221225472 CntnslyMntrdSystmsSupport_Status "Identifies the continuously monitored system support and status.
";
CM_ SG_ 3221225472 AETCTorqueValue "Engine torque value of the data points in PGN 64912 – Advertised Engine Torque Curve (AETC).";
CM_ SG_ 3221225472 TrailerWeight "Total mass of freight-carrying vehicle designed to be pulled by truck, including the weight of the contents.";
CM_ SG_ 3221225472 ReferenceTirePressSetting "Reference value of the tire pressure setting as basis for the tire pressure monitoring ...";
CM_ SG_ 3221225472 ReferenceTirePress "Reference value of the tire pressure as basis for the tire pressure monitoring ...";
CM_ SG_ 3221225472 TirePressThresholdDetection "Signal indicating the pressure level of the tire.  The levels defined represent different pressure conditions of the tire: 000 Extreme over pressure - The tire pressure is at a level where the safety of the vehicle may be jeopardised.";
CM_ SG_ 3221225472 TireAirLeakageRate "The pressure loss rate of a tire.";
CM_ SG_ 3221225472 CTIWheelEndElectricalFault "Indicates the status of electrical fault on CTI wheel interface.";
CM_ SG_ 3221225472 CTITireStatus "Indicates the status of the tire.";
CM_ SG_ 3221225472 CTIWheelSensorStatus "Indicates whether the wheel is being monitored by the CTI controller.";
CM_ SG_ 3221225472 TireTemp "Temperature at the surface of the tire sidewall.";
CM_ SG_ 3221225472 TirePress "Pressure at which air is contained in cavity formed by tire and rim.";
CM_ SG_ 3221225472 EngTurningGearEngaged "Status signal which indicates that the turning gear is engaged.  The turning gear is used to turn the flywheel/crankshaft, ...";
CM_ SG_ 3221225472 AETCSpeedValue "Engine speed value of the data points in PGN 64912 – Advertised Engine Torque Curve (AETC).";
CM_ BO_ 2566741758 "Confirmed and Active DTCs that are classified as class A severity.";
CM_ SG_ 2566741758 FlashRedStopLamp "This parameter provides the capability to flash the RSL";
CM_ SG_ 2566741758 FlashProtectLamp "This parameter provides the capability to flash the engine protect lamp";
CM_ SG_ 2566741758 FlashMalfuncIndicatorLamp "This parameter provides the capability to flash the MIL";
CM_ SG_ 2566741758 FlashAmberWarningLamp "This parameter provides the capability to flash the AWL";
CM_ SG_ 2566741758 MalfunctionIndicatorLampStatus "A lamp used to relay only emissions-related trouble code information. This lamp is only illuminated when there is an emission-related trouble code active.";
CM_ SG_ 2566741758 AmberWarningLampStatus "This lamp is used to relay trouble code information that is reporting a problem with the vehicle system but the vehicle need not be immediately stopped.";
CM_ SG_ 2566741758 RedStopLampState "This lamp is used to relay trouble code information that is of a severe enough condition that it warrants stopping the vehicle.";
CM_ SG_ 2566741758 ProtectLampStatus "This lamp is used to relay trouble code information that is reporting a problem with a vehicle system that is most probably not electronic subsystem related. For instance, engine coolant temperature is exceeding its prescribed temperature range.";
CM_ SG_ 2566741758 DTC5 "Diagnostic Trouble Code";
CM_ SG_ 2566741758 DTC4 "Diagnostic Trouble Code";
CM_ SG_ 2566741758 DTC3 "Diagnostic Trouble Code";
CM_ SG_ 2566741758 DTC2 "Diagnostic Trouble Code";
CM_ SG_ 2566741758 DTC1 "Diagnostic Trouble Code";
CM_ BO_ 2566742014 "Pending DTCs that are classified as class A severity.";
CM_ SG_ 2566742014 FlashRedStopLamp "This parameter provides the capability to flash the RSL";
CM_ SG_ 2566742014 FlashProtectLamp "This parameter provides the capability to flash the engine protect lamp";
CM_ SG_ 2566742014 FlashMalfuncIndicatorLamp "This parameter provides the capability to flash the MIL";
CM_ SG_ 2566742014 FlashAmberWarningLamp "This parameter provides the capability to flash the AWL";
CM_ SG_ 2566742014 MalfunctionIndicatorLampStatus "A lamp used to relay only emissions-related trouble code information. This lamp is only illuminated when there is an emission-related trouble code active.";
CM_ SG_ 2566742014 AmberWarningLampStatus "This lamp is used to relay trouble code information that is reporting a problem with the vehicle system but the vehicle need not be immediately stopped.";
CM_ SG_ 2566742014 RedStopLampState "This lamp is used to relay trouble code information that is of a severe enough condition that it warrants stopping the vehicle.";
CM_ SG_ 2566742014 ProtectLampStatus "This lamp is used to relay trouble code information that is reporting a problem with a vehicle system that is most probably not electronic subsystem related. For instance, engine coolant temperature is exceeding its prescribed temperature range.";
CM_ SG_ 2566742014 DTC5 "Diagnostic Trouble Code";
CM_ SG_ 2566742014 DTC4 "Diagnostic Trouble Code";
CM_ SG_ 2566742014 DTC3 "Diagnostic Trouble Code";
CM_ SG_ 2566742014 DTC2 "Diagnostic Trouble Code";
CM_ SG_ 2566742014 DTC1 "Diagnostic Trouble Code";
CM_ BO_ 2560622334 "The purpose of this DM is to enable the external test equipment to obtain the instantaneous status of diagnostic results";
CM_ SG_ 2560622334 FlashRedStopLamp "This parameter provides the capability to flash the RSL";
CM_ SG_ 2560622334 FlashProtectLamp "This parameter provides the capability to flash the engine protect lamp";
CM_ SG_ 2560622334 FlashMalfuncIndicatorLamp "This parameter provides the capability to flash the MIL";
CM_ SG_ 2560622334 FlashAmberWarningLamp "This parameter provides the capability to flash the AWL";
CM_ SG_ 2560622334 MalfunctionIndicatorLampStatus "A lamp used to relay only emissions-related trouble code information. This lamp is only illuminated when there is an emission-related trouble code active.";
CM_ SG_ 2560622334 AmberWarningLampStatus "This lamp is used to relay trouble code information that is reporting a problem with the vehicle system but the vehicle need not be immediately stopped.";
CM_ SG_ 2560622334 RedStopLampState "This lamp is used to relay trouble code information that is of a severe enough condition that it warrants stopping the vehicle.";
CM_ SG_ 2560622334 ProtectLampStatus "This lamp is used to relay trouble code information that is reporting a problem with a vehicle system that is most probably not electronic subsystem related. For instance, engine coolant temperature is exceeding its prescribed temperature range.";
CM_ SG_ 2560622334 DTC5 "Diagnostic Trouble Code";
CM_ SG_ 2560622334 DTC4 "Diagnostic Trouble Code";
CM_ SG_ 2560622334 DTC3 "Diagnostic Trouble Code";
CM_ SG_ 2560622334 DTC2 "Diagnostic Trouble Code";
CM_ SG_ 2560622334 DTC1 "Diagnostic Trouble Code";
CM_ BO_ 2566744062 "Zero Net Vehicle Weight Change";
CM_ SG_ 2566744062 ZeroNetVehicleWeightChange "Zero Net Vehicle Weight Change command.  A controller receiving this command will record the current Gross Combination Weight as the new Zero, and future requests for Net Vehicle Weight Change will be answered with the difference between the (then) ...";
CM_ BO_ 2499630078 "Reports averaged engine information";
CM_ SG_ 2499630078 EngExhaustGasTempAverageBank2 "The calculated average temperature based upon all of the Bank 2 (right bank) engine exhaust port temperatures.  This is the average temperature based upon the exhaust port temperature measurements of each of the engine cylinders on the right bank ...";
CM_ SG_ 2499630078 EngExhaustGasTempAverageBank1 "The calculated average temperature based upon all of the Bank 1 (left bank) engine exhaust port temperatures.  This is the average temperature based upon the exhaust port temperature measurements of each of the engine cylinders on the left bank ...";
CM_ SG_ 2499630078 EngExhaustGasTempAverage "The calculated average temperature based upon all of the engine exhaust port temperatures.  This is the average temperature based upon the exhaust port temperature measurements at each of the engine cylinders.
Notes:
Use SPN 173 - Engine Exhaust ...";
CM_ BO_ 2359230206 "The purpose of this DM is to identify the number of DTCs in each category. The categories are pending, all pending, MIL-on, previously MIL-on, and permanent DTCs.";
CM_ BO_ 2566750462 "The purpose of this DM is to provide the list of permanent DTCs that are currently present. Permanent DTCs are defined as a confirmed or active MIL-on fault code that is currently commanding the MIL on and is stored in non-volatile memory.";
CM_ SG_ 2566750462 FlashRedStopLamp "This parameter provides the capability to flash the RSL";
CM_ SG_ 2566750462 FlashProtectLamp "This parameter provides the capability to flash the engine protect lamp";
CM_ SG_ 2566750462 FlashMalfuncIndicatorLamp "This parameter provides the capability to flash the MIL";
CM_ SG_ 2566750462 FlashAmberWarningLamp "This parameter provides the capability to flash the AWL";
CM_ SG_ 2566750462 MalfunctionIndicatorLampStatus "A lamp used to relay only emissions-related trouble code information. This lamp is only illuminated when there is an emission-related trouble code active.";
CM_ SG_ 2566750462 AmberWarningLampStatus "This lamp is used to relay trouble code information that is reporting a problem with the vehicle system but the vehicle need not be immediately stopped.";
CM_ SG_ 2566750462 RedStopLampState "This lamp is used to relay trouble code information that is of a severe enough condition that it warrants stopping the vehicle.";
CM_ SG_ 2566750462 ProtectLampStatus "This lamp is used to relay trouble code information that is reporting a problem with a vehicle system that is most probably not electronic subsystem related. For instance, engine coolant temperature is exceeding its prescribed temperature range.";
CM_ SG_ 2566750462 DTC5 "Diagnostic Trouble Code";
CM_ SG_ 2566750462 DTC4 "Diagnostic Trouble Code";
CM_ SG_ 2566750462 DTC3 "Diagnostic Trouble Code";
CM_ SG_ 2566750462 DTC2 "Diagnostic Trouble Code";
CM_ SG_ 2566750462 DTC1 "Diagnostic Trouble Code";
CM_ BO_ 2566750974 "To transmit “pending” diagnostic trouble codes detected during current or last completed driving cycle for components/systems that are tested or continuously monitored during normal driving conditions.";
CM_ SG_ 2566750974 FlashRedStopLamp "This parameter provides the capability to flash the RSL";
CM_ SG_ 2566750974 FlashProtectLamp "This parameter provides the capability to flash the engine protect lamp";
CM_ SG_ 2566750974 FlashMalfuncIndicatorLamp "This parameter provides the capability to flash the MIL";
CM_ SG_ 2566750974 FlashAmberWarningLamp "This parameter provides the capability to flash the AWL";
CM_ SG_ 2566750974 MalfunctionIndicatorLampStatus "A lamp used to relay only emissions-related trouble code information. This lamp is only illuminated when there is an emission-related trouble code active.";
CM_ SG_ 2566750974 AmberWarningLampStatus "This lamp is used to relay trouble code information that is reporting a problem with the vehicle system but the vehicle need not be immediately stopped.";
CM_ SG_ 2566750974 RedStopLampState "This lamp is used to relay trouble code information that is of a severe enough condition that it warrants stopping the vehicle.";
CM_ SG_ 2566750974 ProtectLampStatus "This lamp is used to relay trouble code information that is reporting a problem with a vehicle system that is most probably not electronic subsystem related. For instance, engine coolant temperature is exceeding its prescribed temperature range.";
CM_ SG_ 2566750974 DTC5 "Diagnostic Trouble Code";
CM_ SG_ 2566750974 DTC4 "Diagnostic Trouble Code";
CM_ SG_ 2566750974 DTC3 "Diagnostic Trouble Code";
CM_ SG_ 2566750974 DTC2 "Diagnostic Trouble Code";
CM_ SG_ 2566750974 DTC1 "Diagnostic Trouble Code";
CM_ BO_ 2566754558 "This message conveys the advertised torque curve for the engine, as typically seen on specification sheets available from most engine manufacturers.  The collection conditions for the data conveyed are indicated by SPN 3558 – AETC Data Collection ...";
CM_ SG_ 2566754558 AETCTorqueValue14 "Engine torque value of the data points in PGN 64912 – Advertised Engine Torque Curve (AETC).";
CM_ SG_ 2566754558 AETCTorqueValue13 "Engine torque value of the data points in PGN 64912 – Advertised Engine Torque Curve (AETC).";
CM_ SG_ 2566754558 AETCTorqueValue12 "Engine torque value of the data points in PGN 64912 – Advertised Engine Torque Curve (AETC).";
CM_ SG_ 2566754558 AETCTorqueValue11 "Engine torque value of the data points in PGN 64912 – Advertised Engine Torque Curve (AETC).";
CM_ SG_ 2566754558 AETCTorqueValue10 "Engine torque value of the data points in PGN 64912 – Advertised Engine Torque Curve (AETC).";
CM_ SG_ 2566754558 AETCTorqueValue09 "Engine torque value of the data points in PGN 64912 – Advertised Engine Torque Curve (AETC).";
CM_ SG_ 2566754558 AETCTorqueValue08 "Engine torque value of the data points in PGN 64912 – Advertised Engine Torque Curve (AETC).";
CM_ SG_ 2566754558 AETCTorqueValue07 "Engine torque value of the data points in PGN 64912 – Advertised Engine Torque Curve (AETC).";
CM_ SG_ 2566754558 AETCTorqueValue06 "Engine torque value of the data points in PGN 64912 – Advertised Engine Torque Curve (AETC).";
CM_ SG_ 2566754558 AETCTorqueValue05 "Engine torque value of the data points in PGN 64912 – Advertised Engine Torque Curve (AETC).";
CM_ SG_ 2566754558 AETCTorqueValue04 "Engine torque value of the data points in PGN 64912 – Advertised Engine Torque Curve (AETC).";
CM_ SG_ 2566754558 AETCTorqueValue03 "Engine torque value of the data points in PGN 64912 – Advertised Engine Torque Curve (AETC).";
CM_ SG_ 2566754558 AETCTorqueValue02 "Engine torque value of the data points in PGN 64912 – Advertised Engine Torque Curve (AETC).";
CM_ SG_ 2566754558 AETCTorqueValue01 "Engine torque value of the data points in PGN 64912 – Advertised Engine Torque Curve (AETC).";
CM_ SG_ 2566754558 AETCSpeedValue14 "Engine speed value of the data points in PGN 64912 – Advertised Engine Torque Curve (AETC).";
CM_ SG_ 2566754558 AETCSpeedValue13 "Engine speed value of the data points in PGN 64912 – Advertised Engine Torque Curve (AETC).";
CM_ SG_ 2566754558 AETCSpeedValue12 "Engine speed value of the data points in PGN 64912 – Advertised Engine Torque Curve (AETC).";
CM_ SG_ 2566754558 AETCSpeedValue11 "Engine speed value of the data points in PGN 64912 – Advertised Engine Torque Curve (AETC).";
CM_ SG_ 2566754558 AETCSpeedValue10 "Engine speed value of the data points in PGN 64912 – Advertised Engine Torque Curve (AETC).";
CM_ SG_ 2566754558 AETCSpeedValue09 "Engine speed value of the data points in PGN 64912 – Advertised Engine Torque Curve (AETC).";
CM_ SG_ 2566754558 AETCSpeedValue08 "Engine speed value of the data points in PGN 64912 – Advertised Engine Torque Curve (AETC).";
CM_ SG_ 2566754558 AETCSpeedValue07 "Engine speed value of the data points in PGN 64912 – Advertised Engine Torque Curve (AETC).";
CM_ SG_ 2566754558 AETCSpeedValue06 "Engine speed value of the data points in PGN 64912 – Advertised Engine Torque Curve (AETC).";
CM_ SG_ 2566754558 AETCSpeedValue05 "Engine speed value of the data points in PGN 64912 – Advertised Engine Torque Curve (AETC).";
CM_ SG_ 2566754558 AETCSpeedValue04 "Engine speed value of the data points in PGN 64912 – Advertised Engine Torque Curve (AETC).";
CM_ SG_ 2566754558 AETCSpeedValue03 "Engine speed value of the data points in PGN 64912 – Advertised Engine Torque Curve (AETC).";
CM_ SG_ 2566754558 AETCSpeedValue02 "Engine speed value of the data points in PGN 64912 – Advertised Engine Torque Curve (AETC).";
CM_ SG_ 2566754558 AETCSpeedValue01 "Engine speed value of the data points in PGN 64912 – Advertised Engine Torque Curve (AETC).";
CM_ SG_ 2566754558 AETCTorqueValue00 "Engine torque value of the data points in PGN 64912 – Advertised Engine Torque Curve (AETC).";
CM_ SG_ 2566754558 AETCSpeedValue00 "Engine speed value of the data points in PGN 64912 – Advertised Engine Torque Curve (AETC).";
CM_ SG_ 2566754558 NumberOfAETCDataPoints "Indicates the number of speed / torque data points contained in the Advertised Engine Torque Curve broadcast (AETC).  A minimum of 5 points is required, with a maximum of 15 points available as needed to accurately convey the curve.";
CM_ SG_ 2566754558 AETCDataCollectionStandard "Indicates the standardized method by which torque data was obtained for the Advertised Engine Torque Curve (AETC).  For example, in North America, heavy duty diesel engine specifications are typically based on SAE J1995.  Other applicable SAE, ISO, ...";
CM_ BO_ 2566749950 "This message reports information about the current operation mode of the Adaptive Front-Lighting System (AFS). The Message may include information about dynamic bending light and light distribution. The message provides feedback to the light ...";
CM_ SG_ 2566749950 RightHeadlampLightDistribution "This parameter indicates what kind of light distribution is set by the AFS system for the right headlamp.
0000   Light distribution town - The basic light distribution for town light is generated with a symmetrical cut-off line (Class V)
0001 ...";
CM_ SG_ 2566749950 LeftHeadlampLightDistribution "This parameter indicates what kind of light distribution is set by the AFS system for the left headlamp.
0000   Light distribution town - The basic light distribution for town light is generated with a symmetrical cut-off line (Class V)
0001 ...";
CM_ SG_ 2566749950 RightHeadlampDynamicBendingLight "This parameter indicates whether the dynamic bending light of the left headlamp is working properly.
000   Dynamic bending light deactivated.  There is no problem but for some reasons (e.g. daylight present) the bending light is deactivated.
001 ...";
CM_ SG_ 2566749950 LeftHeadlampDynamicBendingLight "This parameter indicates whether the dynamic bending light of the left headlamp is working properly.
000   Dynamic bending light deactivated.  There is no problem but for some reasons (e.g. daylight present) the bending light is deactivated.
001 ...";
CM_ BO_ 2566838782 "Notes:
Implementers are encouraged to use specific functional SPNs whenever possible.
AUXIO PGNs are intended for two categories of use in which fixed mapping to functions is not possible:
1)  Generic I/O devices
2)  Applications lacking defined ...";
CM_ SG_ 2566838782 AuxI_OChannel2 "Auxiliary channel of data (16 bit) read by the ECU.  This data is in A/D counts and is manufacturer specific.  It may be configured uniquely per application.";
CM_ SG_ 2566838782 AuxI_OChannel1 "Auxiliary channel of data (16 bit) read by the ECU.  This data is in A/D counts and is manufacturer specific.  It may be configured uniquely per application.";
CM_ SG_ 2566838782 AuxI_O13 "Identifies the current status of auxiliary input/output functions that are configured uniquely per application.

00 - Auxiliary channel off
01 - Auxiliary channel on
10 - Error
11 - Not available";
CM_ SG_ 2566838782 AuxI_O14 "Identifies the current status of auxiliary input/output functions that are configured uniquely per application.

00 - Auxiliary channel off
01 - Auxiliary channel on
10 - Error
11 - Not available";
CM_ SG_ 2566838782 AuxI_O15 "Identifies the current status of auxiliary input/output functions that are configured uniquely per application.

00 - Auxiliary channel off
01 - Auxiliary channel on
10 - Error
11 - Not available";
CM_ SG_ 2566838782 AuxI_O16 "Identifies the current status of auxiliary input/output functions that are configured uniquely per application.

00 - Auxiliary channel off
01 - Auxiliary channel on
10 - Error
11 - Not available";
CM_ SG_ 2566838782 AuxI_O09 "Identifies the current status of auxiliary input/output functions that are configured uniquely per application.

00 - Auxiliary channel off
01 - Auxiliary channel on
10 - Error
11 - Not available";
CM_ SG_ 2566838782 AuxI_O10 "Identifies the current status of auxiliary input/output functions that are configured uniquely per application.

00 - Auxiliary channel off
01 - Auxiliary channel on
10 - Error
11 - Not available";
CM_ SG_ 2566838782 AuxI_O11 "Identifies the current status of auxiliary input/output functions that are configured uniquely per application.

00 - Auxiliary channel off
01 - Auxiliary channel on
10 - Error
11 - Not available";
CM_ SG_ 2566838782 AuxI_O12 "Identifies the current status of auxiliary input/output functions that are configured uniquely per application.

00 - Auxiliary channel off
01 - Auxiliary channel on
10 - Error
11 - Not available";
CM_ SG_ 2566838782 AuxI_O05 "Identifies the current status of auxiliary input/output functions that are configured uniquely per application.

00 - Auxiliary channel off
01 - Auxiliary channel on
10 - Error
11 - Not available";
CM_ SG_ 2566838782 AuxI_O06 "Identifies the current status of auxiliary input/output functions that are configured uniquely per application.

00 - Auxiliary channel off
01 - Auxiliary channel on
10 - Error
11 - Not available";
CM_ SG_ 2566838782 AuxI_O07 "Identifies the current status of auxiliary input/output functions that are configured uniquely per application.

00 - Auxiliary channel off
01 - Auxiliary channel on
10 - Error
11 - Not available";
CM_ SG_ 2566838782 AuxI_O08 "Identifies the current status of auxiliary input/output functions that are configured uniquely per application.

00 - Auxiliary channel off
01 - Auxiliary channel on
10 - Error
11 - Not available";
CM_ SG_ 2566838782 AuxI_O01 "Identifies the current status of auxiliary input/output functions that are configured uniquely per application.

00 - Auxiliary channel off
01 - Auxiliary channel on
10 - Error
11 - Not available";
CM_ SG_ 2566838782 AuxI_O02 "Identifies the current status of auxiliary input/output functions that are configured uniquely per application.

00 - Auxiliary channel off
01 - Auxiliary channel on
10 - Error
11 - Not available";
CM_ SG_ 2566838782 AuxI_O03 "Identifies the current status of auxiliary input/output functions that are configured uniquely per application.

00 - Auxiliary channel off
01 - Auxiliary channel on
10 - Error
11 - Not available";
CM_ SG_ 2566838782 AuxI_O04 "Identifies the current status of auxiliary input/output functions that are configured uniquely per application.

00 - Auxiliary channel off
01 - Auxiliary channel on
10 - Error
11 - Not available";
CM_ BO_ 2561146622 "Notes:
Implementers are encouraged to use specific functional SPNs whenever possible.
AUXIO PGNs are intended for two categories of use in which fixed mapping to functions is not possible:
1)  Generic I/O devices
2)  Applications lacking defined ...";
CM_ SG_ 2561146622 AuxI_O45 "Identifies the current status of auxiliary input/output functions that are configured uniquely per application.
00 - Auxiliary channel off
01 - Auxiliary channel on
10 - Error Indicator or Not Used , depending on application
11 - Not Available ...";
CM_ SG_ 2561146622 AuxI_O46 "Identifies the current status of auxiliary input/output functions that are configured uniquely per application.
00 - Auxiliary channel off
01 - Auxiliary channel on
10 - Error Indicator or Not Used , depending on application
11 - Not Available ...";
CM_ SG_ 2561146622 AuxI_O47 "Identifies the current status of auxiliary input/output functions that are configured uniquely per application.
00 - Auxiliary channel off
01 - Auxiliary channel on
10 - Error Indicator or Not Used , depending on application
11 - Not Available ...";
CM_ SG_ 2561146622 AuxI_O48 "Identifies the current status of auxiliary input/output functions that are configured uniquely per application.
00 - Auxiliary channel off
01 - Auxiliary channel on
10 - Error Indicator or Not Used , depending on application
11 - Not Available ...";
CM_ SG_ 2561146622 AuxI_O41 "Identifies the current status of auxiliary input/output functions that are configured uniquely per application.
00 - Auxiliary channel off
01 - Auxiliary channel on
10 - Error Indicator or Not Used , depending on application
11 - Not Available ...";
CM_ SG_ 2561146622 AuxI_O42 "Identifies the current status of auxiliary input/output functions that are configured uniquely per application.
00 - Auxiliary channel off
01 - Auxiliary channel on
10 - Error Indicator or Not Used , depending on application
11 - Not Available ...";
CM_ SG_ 2561146622 AuxI_O43 "Identifies the current status of auxiliary input/output functions that are configured uniquely per application.
00 - Auxiliary channel off
01 - Auxiliary channel on
10 - Error Indicator or Not Used , depending on application
11 - Not Available ...";
CM_ SG_ 2561146622 AuxI_O44 "Identifies the current status of auxiliary input/output functions that are configured uniquely per application.
00 - Auxiliary channel off
01 - Auxiliary channel on
10 - Error Indicator or Not Used , depending on application
11 - Not Available ...";
CM_ SG_ 2561146622 AuxI_O37 "Identifies the current status of auxiliary input/output functions that are configured uniquely per application.
00 - Auxiliary channel off
01 - Auxiliary channel on
10 - Error Indicator or Not Used , depending on application
11 - Not Available ...";
CM_ SG_ 2561146622 AuxI_O38 "Identifies the current status of auxiliary input/output functions that are configured uniquely per application.
00 - Auxiliary channel off
01 - Auxiliary channel on
10 - Error Indicator or Not Used , depending on application
11 - Not Available ...";
CM_ SG_ 2561146622 AuxI_O39 "Identifies the current status of auxiliary input/output functions that are configured uniquely per application.
00 - Auxiliary channel off
01 - Auxiliary channel on
10 - Error Indicator or Not Used , depending on application
11 - Not Available ...";
CM_ SG_ 2561146622 AuxI_O40 "Identifies the current status of auxiliary input/output functions that are configured uniquely per application.
00 - Auxiliary channel off
01 - Auxiliary channel on
10 - Error Indicator or Not Used , depending on application
11 - Not Available ...";
CM_ SG_ 2561146622 AuxI_O33 "Identifies the current status of auxiliary input/output functions that are configured uniquely per application.
00 - Auxiliary channel off
01 - Auxiliary channel on
10 - Error Indicator or Not Used , depending on application
11 - Not Available ...";
CM_ SG_ 2561146622 AuxI_O34 "Identifies the current status of auxiliary input/output functions that are configured uniquely per application.
00 - Auxiliary channel off
01 - Auxiliary channel on
10 - Error Indicator or Not Used , depending on application
11 - Not Available ...";
CM_ SG_ 2561146622 AuxI_O35 "Identifies the current status of auxiliary input/output functions that are configured uniquely per application.
00 - Auxiliary channel off
01 - Auxiliary channel on
10 - Error Indicator or Not Used , depending on application
11 - Not Available ...";
CM_ SG_ 2561146622 AuxI_O36 "Identifies the current status of auxiliary input/output functions that are configured uniquely per application.
00 - Auxiliary channel off
01 - Auxiliary channel on
10 - Error Indicator or Not Used , depending on application
11 - Not Available ...";
CM_ SG_ 2561146622 AuxI_O29 "Identifies the current status of auxiliary input/output functions that are configured uniquely per application.
00 - Auxiliary channel off
01 - Auxiliary channel on
10 - Error Indicator or Not Used , depending on application
11 - Not Available ...";
CM_ SG_ 2561146622 AuxI_O30 "Identifies the current status of auxiliary input/output functions that are configured uniquely per application.
00 - Auxiliary channel off
01 - Auxiliary channel on
10 - Error Indicator or Not Used , depending on application
11 - Not Available ...";
CM_ SG_ 2561146622 AuxI_O31 "Identifies the current status of auxiliary input/output functions that are configured uniquely per application.
00 - Auxiliary channel off
01 - Auxiliary channel on
10 - Error Indicator or Not Used , depending on application
11 - Not Available ...";
CM_ SG_ 2561146622 AuxI_O32 "Identifies the current status of auxiliary input/output functions that are configured uniquely per application.
00 - Auxiliary channel off
01 - Auxiliary channel on
10 - Error Indicator or Not Used , depending on application
11 - Not Available ...";
CM_ SG_ 2561146622 AuxI_O25 "Identifies the current status of auxiliary input/output functions that are configured uniquely per application.
00 - Auxiliary channel off
01 - Auxiliary channel on
10 - Error Indicator or Not Used , depending on application
11 - Not Available ...";
CM_ SG_ 2561146622 AuxI_O26 "Identifies the current status of auxiliary input/output functions that are configured uniquely per application.
00 - Auxiliary channel off
01 - Auxiliary channel on
10 - Error Indicator or Not Used , depending on application
11 - Not Available ...";
CM_ SG_ 2561146622 AuxI_O27 "Identifies the current status of auxiliary input/output functions that are configured uniquely per application.
00 - Auxiliary channel off
01 - Auxiliary channel on
10 - Error Indicator or Not Used , depending on application
11 - Not Available ...";
CM_ SG_ 2561146622 AuxI_O28 "Identifies the current status of auxiliary input/output functions that are configured uniquely per application.
00 - Auxiliary channel off
01 - Auxiliary channel on
10 - Error Indicator or Not Used , depending on application
11 - Not Available ...";
CM_ SG_ 2561146622 AuxI_O21 "Identifies the current status of auxiliary input/output functions that are configured uniquely per application.
00 - Auxiliary channel off
01 - Auxiliary channel on
10 - Error Indicator or Not Used , depending on application
11 - Not Available ...";
CM_ SG_ 2561146622 AuxI_O22 "Identifies the current status of auxiliary input/output functions that are configured uniquely per application.
00 - Auxiliary channel off
01 - Auxiliary channel on
10 - Error Indicator or Not Used , depending on application
11 - Not Available ...";
CM_ SG_ 2561146622 AuxI_O23 "Identifies the current status of auxiliary input/output functions that are configured uniquely per application.
00 - Auxiliary channel off
01 - Auxiliary channel on
10 - Error Indicator or Not Used , depending on application
11 - Not Available ...";
CM_ SG_ 2561146622 AuxI_O24 "Identifies the current status of auxiliary input/output functions that are configured uniquely per application.
00 - Auxiliary channel off
01 - Auxiliary channel on
10 - Error Indicator or Not Used , depending on application
11 - Not Available ...";
CM_ SG_ 2561146622 AuxI_O17 "Identifies the current status of auxiliary input/output functions that are configured uniquely per application.
00 - Auxiliary channel off
01 - Auxiliary channel on
10 - Error Indicator or Not Used , depending on application
11 - Not Available ...";
CM_ SG_ 2561146622 AuxI_O18 "Identifies the current status of auxiliary input/output functions that are configured uniquely per application.
00 - Auxiliary channel off
01 - Auxiliary channel on
10 - Error Indicator or Not Used , depending on application
11 - Not Available ...";
CM_ SG_ 2561146622 AuxI_O19 "Identifies the current status of auxiliary input/output functions that are configured uniquely per application.
00 - Auxiliary channel off
01 - Auxiliary channel on
10 - Error Indicator or Not Used , depending on application
11 - Not Available ...";
CM_ SG_ 2561146622 AuxI_O20 "Identifies the current status of auxiliary input/output functions that are configured uniquely per application.
00 - Auxiliary channel off
01 - Auxiliary channel on
10 - Error Indicator or Not Used , depending on application
11 - Not Available ...";
CM_ BO_ 2561081086 "Notes:
Implementers are encouraged to use specific functional SPNs whenever possible.
AUXIO PGNs are intended for two categories of use in which fixed mapping to functions is not possible:
1)  Generic I/O devices
2)  Applications lacking defined ...";
CM_ SG_ 2561081086 AuxI_O77 "Identifies the current status of auxiliary input/output functions that are configured uniquely per application.
00 - Auxiliary channel off
01 - Auxiliary channel on
10 - Error Indicator or Not Used , depending on application
11 - Not Available ...";
CM_ SG_ 2561081086 AuxI_O78 "Identifies the current status of auxiliary input/output functions that are configured uniquely per application.
00 - Auxiliary channel off
01 - Auxiliary channel on
10 - Error Indicator or Not Used , depending on application
11 - Not Available ...";
CM_ SG_ 2561081086 AuxI_O79 "Identifies the current status of auxiliary input/output functions that are configured uniquely per application.
00 - Auxiliary channel off
01 - Auxiliary channel on
10 - Error Indicator or Not Used , depending on application
11 - Not Available ...";
CM_ SG_ 2561081086 AuxI_O80 "Identifies the current status of auxiliary input/output functions that are configured uniquely per application.
00 - Auxiliary channel off
01 - Auxiliary channel on
10 - Error Indicator or Not Used , depending on application
11 - Not Available ...";
CM_ SG_ 2561081086 AuxI_O73 "Identifies the current status of auxiliary input/output functions that are configured uniquely per application.
00 - Auxiliary channel off
01 - Auxiliary channel on
10 - Error Indicator or Not Used , depending on application
11 - Not Available ...";
CM_ SG_ 2561081086 AuxI_O74 "Identifies the current status of auxiliary input/output functions that are configured uniquely per application.
00 - Auxiliary channel off
01 - Auxiliary channel on
10 - Error Indicator or Not Used , depending on application
11 - Not Available ...";
CM_ SG_ 2561081086 AuxI_O75 "Identifies the current status of auxiliary input/output functions that are configured uniquely per application.
00 - Auxiliary channel off
01 - Auxiliary channel on
10 - Error Indicator or Not Used , depending on application
11 - Not Available ...";
CM_ SG_ 2561081086 AuxI_O76 "Identifies the current status of auxiliary input/output functions that are configured uniquely per application.
00 - Auxiliary channel off
01 - Auxiliary channel on
10 - Error Indicator or Not Used , depending on application
11 - Not Available ...";
CM_ SG_ 2561081086 AuxI_O69 "Identifies the current status of auxiliary input/output functions that are configured uniquely per application.
00 - Auxiliary channel off
01 - Auxiliary channel on
10 - Error Indicator or Not Used , depending on application
11 - Not Available ...";
CM_ SG_ 2561081086 AuxI_O70 "Identifies the current status of auxiliary input/output functions that are configured uniquely per application.
00 - Auxiliary channel off
01 - Auxiliary channel on
10 - Error Indicator or Not Used , depending on application
11 - Not Available ...";
CM_ SG_ 2561081086 AuxI_O71 "Identifies the current status of auxiliary input/output functions that are configured uniquely per application.
00 - Auxiliary channel off
01 - Auxiliary channel on
10 - Error Indicator or Not Used , depending on application
11 - Not Available ...";
CM_ SG_ 2561081086 AuxI_O72 "Identifies the current status of auxiliary input/output functions that are configured uniquely per application.
00 - Auxiliary channel off
01 - Auxiliary channel on
10 - Error Indicator or Not Used , depending on application
11 - Not Available ...";
CM_ SG_ 2561081086 AuxI_O65 "Identifies the current status of auxiliary input/output functions that are configured uniquely per application.
00 - Auxiliary channel off
01 - Auxiliary channel on
10 - Error Indicator or Not Used , depending on application
11 - Not Available ...";
CM_ SG_ 2561081086 AuxI_O66 "Identifies the current status of auxiliary input/output functions that are configured uniquely per application.
00 - Auxiliary channel off
01 - Auxiliary channel on
10 - Error Indicator or Not Used , depending on application
11 - Not Available ...";
CM_ SG_ 2561081086 AuxI_O67 "Identifies the current status of auxiliary input/output functions that are configured uniquely per application.
00 - Auxiliary channel off
01 - Auxiliary channel on
10 - Error Indicator or Not Used , depending on application
11 - Not Available ...";
CM_ SG_ 2561081086 AuxI_O68 "Identifies the current status of auxiliary input/output functions that are configured uniquely per application.
00 - Auxiliary channel off
01 - Auxiliary channel on
10 - Error Indicator or Not Used , depending on application
11 - Not Available ...";
CM_ SG_ 2561081086 AuxI_O61 "Identifies the current status of auxiliary input/output functions that are configured uniquely per application.
00 - Auxiliary channel off
01 - Auxiliary channel on
10 - Error Indicator or Not Used , depending on application
11 - Not Available ...";
CM_ SG_ 2561081086 AuxI_O62 "Identifies the current status of auxiliary input/output functions that are configured uniquely per application.
00 - Auxiliary channel off
01 - Auxiliary channel on
10 - Error Indicator or Not Used , depending on application
11 - Not Available ...";
CM_ SG_ 2561081086 AuxI_O63 "Identifies the current status of auxiliary input/output functions that are configured uniquely per application.
00 - Auxiliary channel off
01 - Auxiliary channel on
10 - Error Indicator or Not Used , depending on application
11 - Not Available ...";
CM_ SG_ 2561081086 AuxI_O64 "Identifies the current status of auxiliary input/output functions that are configured uniquely per application.
00 - Auxiliary channel off
01 - Auxiliary channel on
10 - Error Indicator or Not Used , depending on application
11 - Not Available ...";
CM_ SG_ 2561081086 AuxI_O57 "Identifies the current status of auxiliary input/output functions that are configured uniquely per application.
00 - Auxiliary channel off
01 - Auxiliary channel on
10 - Error Indicator or Not Used , depending on application
11 - Not Available ...";
CM_ SG_ 2561081086 AuxI_O58 "Identifies the current status of auxiliary input/output functions that are configured uniquely per application.
00 - Auxiliary channel off
01 - Auxiliary channel on
10 - Error Indicator or Not Used , depending on application
11 - Not Available ...";
CM_ SG_ 2561081086 AuxI_O59 "Identifies the current status of auxiliary input/output functions that are configured uniquely per application.
00 - Auxiliary channel off
01 - Auxiliary channel on
10 - Error Indicator or Not Used , depending on application
11 - Not Available ...";
CM_ SG_ 2561081086 AuxI_O60 "Identifies the current status of auxiliary input/output functions that are configured uniquely per application.
00 - Auxiliary channel off
01 - Auxiliary channel on
10 - Error Indicator or Not Used , depending on application
11 - Not Available ...";
CM_ SG_ 2561081086 AuxI_O53 "Identifies the current status of auxiliary input/output functions that are configured uniquely per application.
00 - Auxiliary channel off
01 - Auxiliary channel on
10 - Error Indicator or Not Used , depending on application
11 - Not Available ...";
CM_ SG_ 2561081086 AuxI_O54 "Identifies the current status of auxiliary input/output functions that are configured uniquely per application.
00 - Auxiliary channel off
01 - Auxiliary channel on
10 - Error Indicator or Not Used , depending on application
11 - Not Available ...";
CM_ SG_ 2561081086 AuxI_O55 "Identifies the current status of auxiliary input/output functions that are configured uniquely per application.
00 - Auxiliary channel off
01 - Auxiliary channel on
10 - Error Indicator or Not Used , depending on application
11 - Not Available ...";
CM_ SG_ 2561081086 AuxI_O56 "Identifies the current status of auxiliary input/output functions that are configured uniquely per application.
00 - Auxiliary channel off
01 - Auxiliary channel on
10 - Error Indicator or Not Used , depending on application
11 - Not Available ...";
CM_ SG_ 2561081086 AuxI_O49 "Identifies the current status of auxiliary input/output functions that are configured uniquely per application.
00 - Auxiliary channel off
01 - Auxiliary channel on
10 - Error Indicator or Not Used , depending on application
11 - Not Available ...";
CM_ SG_ 2561081086 AuxI_O50 "Identifies the current status of auxiliary input/output functions that are configured uniquely per application.
00 - Auxiliary channel off
01 - Auxiliary channel on
10 - Error Indicator or Not Used , depending on application
11 - Not Available ...";
CM_ SG_ 2561081086 AuxI_O51 "Identifies the current status of auxiliary input/output functions that are configured uniquely per application.
00 - Auxiliary channel off
01 - Auxiliary channel on
10 - Error Indicator or Not Used , depending on application
11 - Not Available ...";
CM_ SG_ 2561081086 AuxI_O52 "Identifies the current status of auxiliary input/output functions that are configured uniquely per application.
00 - Auxiliary channel off
01 - Auxiliary channel on
10 - Error Indicator or Not Used , depending on application
11 - Not Available ...";
CM_ BO_ 2561015550 "Notes:
Implementers are encouraged to use specific functional SPNs whenever possible.
AUXIO PGNs are intended for two categories of use in which fixed mapping to functions is not possible:
1)  Generic I/O devices
2)  Applications lacking defined ...";
CM_ SG_ 2561015550 AuxI_O109 "Identifies the current status of auxiliary input/output functions that are configured uniquely per application.
00 - Auxiliary channel off
01 - Auxiliary channel on
10 - Error Indicator or Not Used , depending on application
11 - Not Available ...";
CM_ SG_ 2561015550 AuxI_O110 "Identifies the current status of auxiliary input/output functions that are configured uniquely per application.
00 - Auxiliary channel off
01 - Auxiliary channel on
10 - Error Indicator or Not Used , depending on application
11 - Not Available ...";
CM_ SG_ 2561015550 AuxI_O111 "Identifies the current status of auxiliary input/output functions that are configured uniquely per application.
00 - Auxiliary channel off
01 - Auxiliary channel on
10 - Error Indicator or Not Used , depending on application
11 - Not Available ...";
CM_ SG_ 2561015550 AuxI_O112 "Identifies the current status of auxiliary input/output functions that are configured uniquely per application.
00 - Auxiliary channel off
01 - Auxiliary channel on
10 - Error Indicator or Not Used , depending on application
11 - Not Available ...";
CM_ SG_ 2561015550 AuxI_O105 "Identifies the current status of auxiliary input/output functions that are configured uniquely per application.
00 - Auxiliary channel off
01 - Auxiliary channel on
10 - Error Indicator or Not Used , depending on application
11 - Not Available ...";
CM_ SG_ 2561015550 AuxI_O106 "Identifies the current status of auxiliary input/output functions that are configured uniquely per application.
00 - Auxiliary channel off
01 - Auxiliary channel on
10 - Error Indicator or Not Used , depending on application
11 - Not Available ...";
CM_ SG_ 2561015550 AuxI_O107 "Identifies the current status of auxiliary input/output functions that are configured uniquely per application.
00 - Auxiliary channel off
01 - Auxiliary channel on
10 - Error Indicator or Not Used , depending on application
11 - Not Available ...";
CM_ SG_ 2561015550 AuxI_O108 "Identifies the current status of auxiliary input/output functions that are configured uniquely per application.
00 - Auxiliary channel off
01 - Auxiliary channel on
10 - Error Indicator or Not Used , depending on application
11 - Not Available ...";
CM_ SG_ 2561015550 AuxI_O101 "Identifies the current status of auxiliary input/output functions that are configured uniquely per application.
00 - Auxiliary channel off
01 - Auxiliary channel on
10 - Error Indicator or Not Used , depending on application
11 - Not Available ...";
CM_ SG_ 2561015550 AuxI_O102 "Identifies the current status of auxiliary input/output functions that are configured uniquely per application.
00 - Auxiliary channel off
01 - Auxiliary channel on
10 - Error Indicator or Not Used , depending on application
11 - Not Available ...";
CM_ SG_ 2561015550 AuxI_O103 "Identifies the current status of auxiliary input/output functions that are configured uniquely per application.
00 - Auxiliary channel off
01 - Auxiliary channel on
10 - Error Indicator or Not Used , depending on application
11 - Not Available ...";
CM_ SG_ 2561015550 AuxI_O104 "Identifies the current status of auxiliary input/output functions that are configured uniquely per application.
00 - Auxiliary channel off
01 - Auxiliary channel on
10 - Error Indicator or Not Used , depending on application
11 - Not Available ...";
CM_ SG_ 2561015550 AuxI_O97 "Identifies the current status of auxiliary input/output functions that are configured uniquely per application.
00 - Auxiliary channel off
01 - Auxiliary channel on
10 - Error Indicator or Not Used , depending on application
11 - Not Available ...";
CM_ SG_ 2561015550 AuxI_O98 "Identifies the current status of auxiliary input/output functions that are configured uniquely per application.
00 - Auxiliary channel off
01 - Auxiliary channel on
10 - Error Indicator or Not Used , depending on application
11 - Not Available ...";
CM_ SG_ 2561015550 AuxI_O99 "Identifies the current status of auxiliary input/output functions that are configured uniquely per application.
00 - Auxiliary channel off
01 - Auxiliary channel on
10 - Error Indicator or Not Used , depending on application
11 - Not Available ...";
CM_ SG_ 2561015550 AuxI_O100 "Identifies the current status of auxiliary input/output functions that are configured uniquely per application.
00 - Auxiliary channel off
01 - Auxiliary channel on
10 - Error Indicator or Not Used , depending on application
11 - Not Available ...";
CM_ SG_ 2561015550 AuxI_O93 "Identifies the current status of auxiliary input/output functions that are configured uniquely per application.
00 - Auxiliary channel off
01 - Auxiliary channel on
10 - Error Indicator or Not Used , depending on application
11 - Not Available ...";
CM_ SG_ 2561015550 AuxI_O94 "Identifies the current status of auxiliary input/output functions that are configured uniquely per application.
00 - Auxiliary channel off
01 - Auxiliary channel on
10 - Error Indicator or Not Used , depending on application
11 - Not Available ...";
CM_ SG_ 2561015550 AuxI_O95 "Identifies the current status of auxiliary input/output functions that are configured uniquely per application.
00 - Auxiliary channel off
01 - Auxiliary channel on
10 - Error Indicator or Not Used , depending on application
11 - Not Available ...";
CM_ SG_ 2561015550 AuxI_O96 "Identifies the current status of auxiliary input/output functions that are configured uniquely per application.
00 - Auxiliary channel off
01 - Auxiliary channel on
10 - Error Indicator or Not Used , depending on application
11 - Not Available ...";
CM_ SG_ 2561015550 AuxI_O89 "Identifies the current status of auxiliary input/output functions that are configured uniquely per application.
00 - Auxiliary channel off
01 - Auxiliary channel on
10 - Error Indicator or Not Used , depending on application
11 - Not Available ...";
CM_ SG_ 2561015550 AuxI_O90 "Identifies the current status of auxiliary input/output functions that are configured uniquely per application.
00 - Auxiliary channel off
01 - Auxiliary channel on
10 - Error Indicator or Not Used , depending on application
11 - Not Available ...";
CM_ SG_ 2561015550 AuxI_O91 "Identifies the current status of auxiliary input/output functions that are configured uniquely per application.
00 - Auxiliary channel off
01 - Auxiliary channel on
10 - Error Indicator or Not Used , depending on application
11 - Not Available ...";
CM_ SG_ 2561015550 AuxI_O92 "Identifies the current status of auxiliary input/output functions that are configured uniquely per application.
00 - Auxiliary channel off
01 - Auxiliary channel on
10 - Error Indicator or Not Used , depending on application
11 - Not Available ...";
CM_ SG_ 2561015550 AuxI_O85 "Identifies the current status of auxiliary input/output functions that are configured uniquely per application.
00 - Auxiliary channel off
01 - Auxiliary channel on
10 - Error Indicator or Not Used , depending on application
11 - Not Available ...";
CM_ SG_ 2561015550 AuxI_O86 "Identifies the current status of auxiliary input/output functions that are configured uniquely per application.
00 - Auxiliary channel off
01 - Auxiliary channel on
10 - Error Indicator or Not Used , depending on application
11 - Not Available ...";
CM_ SG_ 2561015550 AuxI_O87 "Identifies the current status of auxiliary input/output functions that are configured uniquely per application.
00 - Auxiliary channel off
01 - Auxiliary channel on
10 - Error Indicator or Not Used , depending on application
11 - Not Available ...";
CM_ SG_ 2561015550 AuxI_O88 "Identifies the current status of auxiliary input/output functions that are configured uniquely per application.
00 - Auxiliary channel off
01 - Auxiliary channel on
10 - Error Indicator or Not Used , depending on application
11 - Not Available ...";
CM_ SG_ 2561015550 AuxI_O81 "Identifies the current status of auxiliary input/output functions that are configured uniquely per application.
00 - Auxiliary channel off
01 - Auxiliary channel on
10 - Error Indicator or Not Used , depending on application
11 - Not Available ...";
CM_ SG_ 2561015550 AuxI_O82 "Identifies the current status of auxiliary input/output functions that are configured uniquely per application.
00 - Auxiliary channel off
01 - Auxiliary channel on
10 - Error Indicator or Not Used , depending on application
11 - Not Available ...";
CM_ SG_ 2561015550 AuxI_O83 "Identifies the current status of auxiliary input/output functions that are configured uniquely per application.
00 - Auxiliary channel off
01 - Auxiliary channel on
10 - Error Indicator or Not Used , depending on application
11 - Not Available ...";
CM_ SG_ 2561015550 AuxI_O84 "Identifies the current status of auxiliary input/output functions that are configured uniquely per application.
00 - Auxiliary channel off
01 - Auxiliary channel on
10 - Error Indicator or Not Used , depending on application
11 - Not Available ...";
CM_ BO_ 2566746622 "The Brake Stroke Alert (BSA) message will provide the brake actuator stroke status for up to 20 wheel ends.";
CM_ SG_ 2566746622 TrailerBrakeStrokeAxle5Right "Brake stroke status for right brake actuator on trailer axle 5.

000 - OK (Normal operation)
001 - Non-functioning
010 - Overstroke
011 - Dragging brake
100 - Reserved
101 - Reserved
110 - Sensor error
111 - Not available";
CM_ SG_ 2566746622 TrailerBrakeStrokeAxle5Left "Brake stroke status for left brake actuator on trailer axle 5.

000 - OK (Normal operation)
001 - Non-functioning
010 - Overstroke
011 - Dragging brake
100 - Reserved
101 - Reserved
110 - Sensor error
111 - Not available";
CM_ SG_ 2566746622 TrailerBrakeStrokeAxle4Right "Brake stroke status for right brake actuator on trailer axle 4.

000 - OK (Normal operation)
001 - Non-functioning
010 - Overstroke
011 - Dragging brake
100 - Reserved
101 - Reserved
110 - Sensor error
111 - Not available";
CM_ SG_ 2566746622 TrailerBrakeStrokeAxle4Left "Brake stroke status for left brake actuator on trailer axle 4.

000 - OK (Normal operation)
001 - Non-functioning
010 - Overstroke
011 - Dragging brake
100 - Reserved
101 - Reserved
110 - Sensor error
111 - Not available";
CM_ SG_ 2566746622 TrailerBrakeStrokeAxle3Right "Brake stroke status for right brake actuator on trailer axle 3.

000 - OK (Normal operation)
001 - Non-functioning
010 - Overstroke
011 - Dragging brake
100 - Reserved
101 - Reserved
110 - Sensor error
111 - Not available";
CM_ SG_ 2566746622 TrailerBrakeStrokeAxle3Left "Brake stroke status for left brake actuator on trailer axle 3.

000 - OK (Normal operation)
001 - Non-functioning
010 - Overstroke
011 - Dragging brake
100 - Reserved
101 - Reserved
110 - Sensor error
111 - Not available";
CM_ SG_ 2566746622 TrailerBrakeStrokeAxle2Right "Brake stroke status for right brake actuator on trailer axle 2.

000 - OK (Normal operation)
001 - Non-functioning
010 - Overstroke
011 - Dragging brake
100 - Reserved
101 - Reserved
110 - Sensor error
111 - Not available";
CM_ SG_ 2566746622 TrailerBrakeStrokeAxle2Left "Brake stroke status for left brake actuator on trailer axle 2.

000 - OK (Normal operation)
001 - Non-functioning
010 - Overstroke
011 - Dragging brake
100 - Reserved
101 - Reserved
110 - Sensor error
111 - Not available";
CM_ SG_ 2566746622 TrailerBrakeStrokeAxle1Right "Brake stroke status for right brake actuator on trailer axle 1.

000 - OK (Normal operation)
001 - Non-functioning
010 - Overstroke
011 - Dragging brake
100 - Reserved
101 - Reserved
110 - Sensor error
111 - Not available";
CM_ SG_ 2566746622 TrailerBrakeStrokeAxle1Left "Brake stroke status for left brake actuator on trailerr axle 1.

000 - OK (Normal operation)
001 - Non-functioning
010 - Overstroke
011 - Dragging brake
100 - Reserved
101 - Reserved
110 - Sensor error
111 - Not available";
CM_ SG_ 2566746622 TractorBrakeStrokeAxle5Right "Brake stroke status for right brake actuator on tractor axle 5.

000 - OK (Normal operation)
001 - Non-functioning
010 - Overstroke
011 - Dragging brake
100 - Reserved
101 - Reserved
110 - Sensor error
111 - Not available";
CM_ SG_ 2566746622 TractorBrakeStrokeAxle5Left "Brake stroke status for left brake actuator on tractor axle 5.

000 - OK (Normal operation)
001 - Non-functioning
010 - Overstroke
011 - Dragging brake
100 - Reserved
101 - Reserved
110 - Sensor error
111 - Not available";
CM_ SG_ 2566746622 TractorBrakeStrokeAxle4Right "Brake stroke status for right brake actuator on tractor axle 4.

000 - OK (Normal operation)
001 - Non-functioning
010 - Overstroke
011 - Dragging brake
100 - Reserved
101 - Reserved
110 - Sensor error
111 - Not available";
CM_ SG_ 2566746622 TractorBrakeStrokeAxle4Left "Brake stroke status for left brake actuator on tractor axle 4.

000 - OK (Normal operation)
001 - Non-functioning
010 - Overstroke
011 - Dragging brake
100 - Reserved
101 - Reserved
110 - Sensor error
111 - Not available";
CM_ SG_ 2566746622 TractorBrakeStrokeAxle3Right "Brake stroke status for right brake actuator on tractor axle 3.

000 - OK (Normal operation)
001 - Non-functioning
010 - Overstroke
011 - Dragging brake
100 - Reserved
101 - Reserved
110 - Sensor error
111 - Not available";
CM_ SG_ 2566746622 TractorBrakeStrokeAxle3Left "Brake stroke status for left brake actuator on tractor axle 3.

000 - OK (Normal operation)
001 - Non-functioning
010 - Overstroke
011 - Dragging brake
100 - Reserved
101 - Reserved
110 - Sensor error
111 - Not available";
CM_ SG_ 2566746622 TractorBrakeStrokeAxle2Right "Brake stroke status for right brake actuator on tractor axle 2.

000 - OK (Normal operation)
001 - Non-functioning
010 - Overstroke
011 - Dragging brake
100 - Reserved
101 - Reserved
110 - Sensor error
111 - Not available";
CM_ SG_ 2566746622 TractorBrakeStrokeAxle2Left "Brake stroke status for left brake actuator on tractor axle 2. 

000 - OK (Normal operation)
001 - Non-functioning
010 - Overstroke
011 - Dragging brake
100 - Reserved
101 - Reserved
110 - Sensor error
111 - Not available";
CM_ SG_ 2566746622 TractorBrakeStrokeAxle1Right "Brake stroke status for right brake actuator on tractor axle 1. 

000 - OK (Normal operation)
001 - Non-functioning
010 - Overstroke
011 - Dragging brake
100 - Reserved
101 - Reserved
110 - Sensor error
111 - Not available";
CM_ SG_ 2566746622 TractorBrakeStrokeAxle1Left "Brake stroke status for left brake actuator on tractor axle 1. 

000 - OK (Normal operation)  
001 - Non-functioning
010 - Overstroke 
011 - Dragging brake
100 - Reserved
101 - Reserved
110 - Sensor error
111 - Not available";
CM_ SG_ 2566845950 RoadSurfaceTemp "Indicated temperature of road surface over which vehicle is operating.";
CM_ SG_ 2566845950 EngAirIntakeTemp "Temperature of air entering vehicle air induction system.";
CM_ SG_ 2566845950 AmbientAirTemp "Temperature of air surrounding vehicle.";
CM_ SG_ 2566845950 CabInteriorTemp "Temperature of air inside the part of the vehicle that encloses the driver and vehicle operating controls.

Note: See also SPN 1691.  SPN 1662 is an additional diagnostic SPN associated with cab temperature.";
CM_ SG_ 2566845950 BarometricPress "Absolute air pressure of the atmosphere.";
CM_ SG_ 2566840062 EngAirStartPress "Gage pressure of air in an engine starting system that utilizes compressed air to provide the force required to rotate the crankshaft.";
CM_ BO_ 2566827774 "Air Supply Pressure";
CM_ SG_ 2566827774 AirCompressorStatus "Indicates whether the air compressor is actively compressing air.  

00     Compressor not active
01     Compressor active
10     Error indicator
11     Not available";
CM_ SG_ 2566827774 AirSuspensionSupplyPress "The pneumatic pressure in the circuit for the electronically controlled air suspension system.";
CM_ SG_ 2566827774 AuxEquipmentSupplyPress "The pneumatic pressure in the auxiliary circuit.";
CM_ SG_ 2566827774 PowertrainCircuitAirSupplyPress "Supply pressure to carry the pressure information for the powertrain circuit. This circuit typically would feed powertrain components such as throttles, gearbox actuators and aftertreatment actuators for EGR and SCR systems.";
CM_ SG_ 2566827774 ServiceBrakeCircuit2AirPress "The pneumatic pressure in the secondary service brake circuit or reservoir, supplying the front axle.";
CM_ SG_ 2566827774 ServiceBrakeCircuit1AirPress "The pneumatic pressure in the primary service brake circuit or reservoir, supplying the rear axle.";
CM_ SG_ 2566827774 ParkingAnd_orTrailerAirPress "The pneumatic pressure in the circuit or reservoir for the parking brake and/or the trailer supply.";
CM_ SG_ 2566827774 PneumaticSupplyPress "The pneumatic pressure in the main reservoir, sometimes referred to as the wet tank.";
CM_ BO_ 2566846974 "Axle information message
NOTE–Message must be repeated as necessary to transmit all available information.   This method of location identification requires individual SPNs to be assigned to report failures specific to each individual component ...";
CM_ SG_ 2566846974 SteerAxleLubePress "The steering axle lubricant pressure.";
CM_ SG_ 2566846974 SteerAxleTemp "Temperature of lubricant in steering axle.";
CM_ SG_ 2566846974 DriveAxleLubePress "The drive axle lubricant pressure with location determined by Drive Axle Location (SPN 930).";
CM_ SG_ 2566846974 DriveAxleTemp "Temperature of axle lubricant in drive axle.";
CM_ SG_ 2566846974 DriveAxleLiftAirPress "Gage pressure of air in system that utilizes compressed air to provide force between axle and frame.";
CM_ SG_ 2566846974 DriveAxleLocation "To identify to which of several similar devices (such as tires or fuel tanks) the information applies.
The low order 4 bits represent a position number, counting left to right when facing in the direction of normal vehicle travel (forward).
The ...";
CM_ SG_ 2633935614 EngGsMssFlwSnsrFuelingCorrection "The amount of fuel the Gas Mass Flow Sensor is sensing should be added or subtracted compared to the maximum amount of fuel the control system allows the sensor to add or subtract.";
CM_ SG_ 2633935614 GsFlInjctonPulseCorrectionFactor "A correction to the gaseous fuel injection pulse (expressed in msec) represented as a percentage.  100% means no correction, higher values indicate increased pulse time, lower values indicate decreased pulse time.";
CM_ SG_ 2633935614 EngTurboWastegateValvePos "The position of the turbocharger wastegate valve (not the electronic wastegate control valve).";
CM_ SG_ 2633935614 EngDesiredAbsIntakeManifoldPress "The desired absolute intake manifold pressure (turbo boost limit) of the engine.";
CM_ SG_ 2633935614 EngGasFuelCorrectionFactor "A correction to a predefined gaseous fuel energy (expressed in energy per unit volume) represented as a percentage.  The actual fuel energy used to control the engine is the product of the gaseous fuel correction factor and the energy of the gas.";
CM_ BO_ 2566803966 "The operator requested characteristics for the ACC systems operation.";
CM_ SG_ 2566803966 RequestedACCDistanceMode "The Requested Distance Control Mode to the ACC system from the operators interface.
The ACC Set Distance Mode (SPN 1589) indicates the selected Distance Control Mode for the ACC system. This parameter is the driver requested setting for this.
000 ...";
CM_ SG_ 2566803966 ACCUsageDemand "This parameter indicates the drivers demand to activate or deactivate ACC keeping distance control.

00 driver demand for not using ACC distance keeping control
01 driver demand for using ACC distance keeping control
10 reserved
11 don't care";
CM_ BO_ 2432593918 "NOTE—The ACC1 message is required whenever the engine is running and ACC is powered on and not
faulted. The timeout for ACC1 message will be between 2.5 times to 5 times the update rate.
The ACC1 message is intended primarily for engines and ...";
CM_ SG_ 2432593918 ForwardCollisionWarning "This parameter indicates if a collision is imminent and strong driver reaction either by braking hard or by an avoidance maneuver are imperative to prevent a collision.
00 No warning
01 Collision is imminent
10 Error indicator
11 not available
 ...";
CM_ SG_ 2432593918 ACCDistanceAlertSignal "Signal to indicate to the operator that the ACC system is not able to maintain the distance to the target. Example: Target stopping rapidly. This signal may be used to activate warning sounds or indicators.
00 ACC DAS Not Active
01 ACC DAS Active
 ...";
CM_ SG_ 2432593918 ACCSystemShutoffWarning "Signal to warn the driver of system deactivation due to non-driver actions. Example: Attempting to control vehicle speed below or above limits of ACC. This signal may be used to activate warning sounds or indicators.
00 ACC SSOW Not Active
01 ACC ...";
CM_ SG_ 2432593918 ACCTargetDetected "Signal to indicate to the driver that the ACC system has detected a target. 

00 No targets detected
01 Target detected
10 Reserved
11 Take no action";
CM_ SG_ 2432593918 RoadCurvature "Estimated value of the current road curvature for use by the adaptive cruise control system.  Positive values are used for left curves.  Curvature is the inverse of the radius and is zero for straight roads.";
CM_ SG_ 2432593918 AdptiveCruiseCtrlSetDistanceMode "Selected distance mode for adaptive cruise control.
000 ACC Distance mode #1 (largest distance)
001 ACC Distance mode #2
010 ACC Distance mode #3
011 ACC Distance mode #4
100 ACC Distance mode #5 (shortest distance)
101 Conventional cruise ...";
CM_ SG_ 2432593918 AdaptiveCruiseCtrlMode "This parameter is used to indicate the current state, or mode, of operation by the Adaptive Cruise Control (ACC) device. The states characterize independent system states (e.g., it is not possible to express distance control active and overtake mode ...";
CM_ SG_ 2432593918 AdaptiveCruiseCtrlSetSpeed "Value of the desired (chosen) velocity of the adaptive cruise control system.";
CM_ SG_ 2432593918 DistanceToForwardVehicle "Distance to the preceding vehicle situated within 250 m in the same lane and moving in the same direction.";
CM_ SG_ 2432593918 SpeedOfForwardVehicle "Absolute velocity of the preceding vehicle situated within 250 m in the same lane and moving in the same direction.";
CM_ SG_ 2633935102 ArticulationAngle "Angle of deflection of an articulated transit vehicle (rotation angle about the vehicles z-axis). A right turn (clockwise) is indicated with a positive angle and a left turn is indicated with a negative angle.  This parameter is defined according to ...";
CM_ BO_ 2633927934 "Auxiliary Analog Information";
CM_ SG_ 2633927934 RelativeHumidity "Measures humidity of combustion air prior to entry into turbocharger";
CM_ SG_ 2633927934 AuxLevel "Level measured by a sensor.";
CM_ SG_ 2633927934 AuxPress2 "Pressure measured by auxiliary pressure sensor #2.  Not to be used in place of existing SPNs.";
CM_ SG_ 2633927934 AuxPress1 "Pressure measured by auxiliary pressure sensor #1.  Not to be used in place of existing SPNs.";
CM_ SG_ 2633927934 AuxTemp2 "Temperature measured by auxiliary temperature sensor #2.  Not to be used in place of existing SPNs.";
CM_ SG_ 2633927934 AuxTemp1 "Temperature measured by auxiliary temperature sensor #1.  Not to be used in place of existing SPNs.";
CM_ SG_ 2566847998 EngBlowerBypassValvePos "Relative position of the blower bypass valve.";
CM_ SG_ 2566847998 EngGasSupplyPress "Gage pressure of gas supply to fuel metering device.";
CM_ BO_ 2364079870 "The Acknowledgment PG is used to provide a handshake mechanism between transmitting and receiving devices.";
CM_ SG_ 2364079870 ControlByte "Indicates the acknowledgement response.";
CM_ SG_ 2364079870 ParameterGroupNumber "PGN which is requested by the Request message";
CM_ SG_ 2364079870 GroupFunctionValue "Group Function of PGN being acknowledged. This field identifies for a device the specific group function of a PGN being acknowledged or declined.  This field is not used if the PGN being acknowledged or declined is not a group function PGN.";
CM_ BO_ 2566803198 "Used for door information.";
CM_ SG_ 2566803198 Status2OfDoors "Composite indication of all bus door statuses. Enabled means the bus doors are able to be automatically opened or closed.

00   all bus doors are disabled
01   at least 1 bus door enabled 
10   error
11   not available";
CM_ SG_ 2566803198 Ramp_WheelChairLiftPos "Signal which indicates the actual position of the ramp / wheel chair lift.

00 Inside bus
01 Outside bus
10 Error
11 Not available";
CM_ SG_ 2566803198 PosOfDoors "Signal which indicates the actual position of the doors.

0000 At least 1 door is open
0001 Closing last door
0010 All doors closed
0011-1101 Not defined
1110 Error
1111 Not available";
CM_ BO_ 2565870334 "Fifth wheel smart system information. Parameters used to determine the status of the tractor to trailer coupling system integrity.";
CM_ SG_ 2565870334 FifthWheelRollWarningIndicator "Indicates to the vehicle operator that the roll moment has exceeded a preset limit. 

00 Limit not exceeded
01 Limit exceeded
10 error
11 Not Available";
CM_ SG_ 2565870334 FifthWheelRollMoment "Fifth wheel roll moment force - If the moment is positive, the trailer is rolling clockwise relative to the normal vehicle forward motion.";
CM_ SG_ 2565870334 FifthWheelDrawbarForce "Fifth wheel drawbar force, with the trailer held stationary a positive force is generated by the vehicle pulling forward.";
CM_ SG_ 2565870334 FifthWheelVerticalForce "The amount of load being applied to the fifth wheel by the trailer. Zero load is indicated without a trailer.";
CM_ BO_ 2566762238 "Fifth wheel smart system information #2. Message to convey operator parameters associated with the tractor to trailer coupling control and error state.";
CM_ SG_ 2566762238 FifthWheelSliderLockIndicator "Indicates to vehicle operator that the fifth wheel slider is in position and locked. 

00 Not Locked
01 Locked
10 Error
11 Not Available";
CM_ SG_ 2566762238 FifthWheelSliderPos "Slider position measurement. Zero equals fully back position, that is, the farthest to the rear of the vehicle.";
CM_ SG_ 2566762238 FfthWhlLockCoupleStatusIndicator "Indicates results of coupling operation to the vehicle operator. For incomplete couples further information can be obtained from the fifth wheel error status SPN.
00   Incomplete or bad couple, truck should not be moved
01   Successful couple ...";
CM_ SG_ 2566762238 FfthWhlLckReadyToCoupleIndicator "Indicates to the vehicle operator that the fifth wheel lock is open and ready to couple.

00   Lock not open, not ready to couple
01   Lock open, ready to couple
10   Error
11   Not Available";
CM_ SG_ 2566762238 FifthWheelErrorStatus "Fifth wheel error state which conveys information when coupling status is incomplete or bad.
0000    0 - Improper Couple
0001    1 - Locks Closed / No Kingpin at Startup
0010    2 - Kingpin / Locks Open at Startup
0011    3 - Not Used
0100    4 ...";
CM_ BO_ 2364543998 "The Slope Sensor Information message shall provide a measurement of the vehicles pitch angle, a measurement of the vehicles roll angle, and a measurement of the vehicles pitch rate.  The vehicle dynamics measurements in this message shall be ...";
CM_ SG_ 2364543998 RollAndPitchMeasurementLatency "The estimated measurement latency of the measurement.  NOTE: This is only the sensor latency and does not include any additional latencies that might exist because of the CAN Bus or overall system implementation.
Latency is the time from sensor ...";
CM_ SG_ 2364543998 PitchAndRollCompensated "Compensated mode for the pitch and roll measurements.  Compensation is the use of multiple sensors together to enhance the output of pitch and roll measurements.
Bit 8 Bit 7
0        0   Compensation Off
0        1   Compensation On
1        0 ...";
CM_ SG_ 2364543998 PitchRateFigureOfMerit "Figure of merit for the pitch rate measurement.
Bit 6 Bit 5
0        0  Pitch rate fully functional.  Data is within sensor specification.
0        1  Pitch rate degraded.  Data is suspect due to environmental conditions.
1        0  Error
1 ...";
CM_ SG_ 2364543998 RollAngleFigureOfMerit "Figure of merit for roll angle measurement.
Bit 4 Bit 3
0        0  Roll angle fully functional.  Data is within sensor specification.
0        1  Roll angle degraded.  Data is suspect due to environmental conditions.
1        0  Error
1 ...";
CM_ SG_ 2364543998 PitchAngleFigureOfMerit "Figure of merit for pitch angle measurement.
Bit 2  Bit 1
0           0  Pitch angle fully functional.  Data is within sensor specification.
0           1  Pitch angle degraded.  Data is suspect due to environmental conditions.
1           0 ...";
CM_ SG_ 2364543998 PitchRate "Pitch rate is the rate-of-change of the pitch angle over time, where the pitch angle vector is in the direction of travel of the vehicle. The pitch rate for increasing ascent over time is reported with a positive value. This parameter is defined ...";
CM_ SG_ 2364543998 RollAngle "The angle between the vehicle y-axis and the ground plane (i.e. rotation about the X-axis).  The roll angle for a roll to the right is reported with a positive value. Roll angle is the same for both Z-Down and Z-Up axis systems, since both systems ...";
CM_ SG_ 2364543998 PitchAngle "The angle between the vehicle x-axis and the ground plane (i.e. rotation about the vehicle Y-axis).  The pitch angle for an angle of ascent is reported with a positive value. This parameter is defined according to a Z-Down axis system and the sign ...";
CM_ SG_ 2566846718 TransOilLevel1MeasurementStatus "Measurement status for the first instance of a transmission oil level indicator.  Indicates if conditions are acceptable to obtain a valid transmission oil level measurement as conveyed in SPN 124 Transmission Oil Level or SPN 3027 Transmission Oil ...";
CM_ SG_ 2566846718 TransOilLevel1CountdownTimer "Countdown timer for the first instance of a transmission oil level indicator.  Once all vehicle conditions (such as vehicle stopped, etc) are met, some transmissions may require a ‘settling time’ to allow the fluid level to normalize.  This ...";
CM_ SG_ 2566846718 TransOilLevel1High_Low "First instance of a transmission oil level indicator. Conveys the amount of current volume of transmission sump oil compared to recommended volume. Positive values indicate overfill. Zero means the transmission fluild is filled to the recommended ...";
CM_ SG_ 2566846718 TransOilTemp1 "First instance of transmission lubricant temperature.";
CM_ SG_ 2566846718 TransOilPress "Gage pressure of lubrication fluid in transmission, measured after pump.";
CM_ SG_ 2566846718 TransFilterDiffPress "Change in transmission fluid pressure, measured after the filter, due to accumulation of solid or semisolid material on or in the filter.";
CM_ SG_ 2566846718 TransOilLevel1 "First instance of a transmission oil level indicator. Conveys the ratio of volume of transmission sump oil to recommended volume.";
CM_ SG_ 2566846718 ClutchPress "Gage pressure of oil within a wet clutch.";
CM_ SG_ 2566846462 KeyswitchBatteryPotential "Battery potential measured at the input of the electronic control unit supplied through a keyswitch or similar switching device.";
CM_ SG_ 2566846462 BatteryPotential_PowerInput1 "This parameter measures the first source of battery potential as measured at the input of the ECM/actuator etc. coming from one or more batteries, irrespective of the distance between the component and the battery.  This SPN is also used when ECM's ...";
CM_ SG_ 2566846462 ChargingSystemPotential "Electrical potential measured at the charging system output.  The charging system may be any device charging the batteries.  This includes alternators, generators, solid state charger and other charging devices.";
CM_ SG_ 2566846462 AltCurrent "Measure of electrical current flow from the alternator.  Alternator Current (High Range/Resolution) parameter SPN 1795 has a higher range and resolution of the same parameter.";
CM_ SG_ 2566846462 NetBatteryCurrent "Net flow of electrical current into/out of the battery or batteries.";
CM_ BO_ 2566760702 "Message for reporting status information regarding the second instance of a wireless communications network on a device or system.

See PGN 64937 for the first wireless network.";
CM_ SG_ 2566760702 WrelessCommunicationNetworkType2 "Type of Wireless Communication Network

0 = Cellular network #1
1 = Cellular network #2
2 = Wireless LAN #1
3 = Wireless LAN #2
4 = Satellite network
5-250 = Reserved for Future Assignment
251-253 = Reserved
254 = Error
255 = Not Available";
CM_ SG_ 2566760702 NetworkSignalStrength2 "Indicates the signal strength for the wireless communications network type.";
CM_ SG_ 2566760702 NetworkAntennaStatus2 "Indicates the status of the antenna for the wireless communications network type

0 = Off
1 = On
2-250 = Reserved for Future Assignment
251-253 = Reserved
254 = Error
255 = Not Available";
CM_ SG_ 2566760702 NetworkServiceStatus2 "Indicates the status of the Service for the wireless communications network type
0 = Local Service
1 = Roaming Service
2 = Service not available
3 = Not Authorized to Operate on Service
4-250 = Reserved for Future Assignment
251-253 = Reserved
 ...";
CM_ SG_ 2566760702 NetworkTransceiverStatus2 "Indicates the status of the transceiver for the wireless communications network type

0 = Off
1 = On
2 = Not Authorized to Operate on Network
3-250 = Reserved for Future Assignment
251-253 = Reserved
254 = Error
255 = Not Available";
CM_ BO_ 2566760958 "Message for reporting status information regarding the first instance of a wireless communications network on a device or system.";
CM_ SG_ 2566760958 WrelessCommunicationNetworkType1 "Type of Wireless Communication Network

0 = Cellular network #1
1 = Cellular network #2
2 = Wireless LAN #1
3 = Wireless LAN #2
4 = Satellite network
5-250 = Reserved for Future Assignment
251-253 = Reserved
254 = Error
255 = Not Available";
CM_ SG_ 2566760958 NetworkSignalStrength1 "Indicates the signal strength for the wireless communications network type.";
CM_ SG_ 2566760958 NetworkAntennaStatus1 "Indicates the status of the antenna for the wireless communications network type

0 = Off
1 = On
2-250 = Reserved for Future Assignment
251-253 = Reserved
254 = Error
255 = Not Available";
CM_ SG_ 2566760958 NetworkServiceStatus1 "Indicates the status of the Service for the wireless communications network type
0 = Local Service
1 = Roaming Service
2 = Service not available
3 = Not Authorized to Operate on Service
4-250 = Reserved for Future Assignment
251-253 = Reserved
 ...";
CM_ SG_ 2566760958 NetworkTransceiverStatus1 "Indicates the status of the transceiver for the wireless communications network type

0 = Off
1 = On
2 = Not Authorized to Operate on Network
3-250 = Reserved for Future Assignment
251-253 = Reserved
254 = Error
255 = Not Available";
CM_ BO_ 2633869310 "Contains operating modes for the following voltage regulator functions:  Unit Mode, Soft Start Mode, Under Frequency Mode, Operating Mode, Load Compensation Mode.";
CM_ SG_ 2633869310 VoltageRegulatorEnabled "State signal indicating the Voltage Regulator is enabled.  This parameter indicates whether the regulator is regulating or not regulating generator output voltage.
00 - Not regulating voltage - unit disabled
01 - Regulating voltage
10 - Reserved
 ...";
CM_ SG_ 2633869310 VoltageRegulatorSoftStartState "State signal indicating the mode of the Voltage regulator soft start function.  Soft start controls the generator voltage overshoot by controlling the rate of rise of the generator output voltage at generator start up.
00 - Soft start is inactive
 ...";
CM_ SG_ 2633869310 VltgRgltrUndrfrqncyCmpnstnEnbld "State signal indicating the operating mode for underfrequency compensation.
00 - Underfrequency compensation disabled
01 - Underfrequency compensation enabled
10 - Reserved
11 - Not available
Note:
Underfrequency compensation is when the ...";
CM_ SG_ 2633869310 VltgRgltrVAr_PwrFctrOprtingMode "State signal indicating the operating mode for the Voltage regulator VAr/Power Factor
000 - VAr/Power Factor regulation disabled
001 - Power factor regulation enabled
010 - VAr regulation enabled
011 - Reserved
100 - Reserved
101 - Reserved
 ...";
CM_ SG_ 2633869310 VltgRglatorLoadCompensationMode "State signal indicating the voltage regulator load compensation mode.  Load compensation is when the voltage is adjusted based on the magnitude of load current
000 - load compensation disabled
001 - Voltage droop compensation enabled
010 - IR ...";
CM_ BO_ 2365433598 "Contains voltage regulator parameters that pertain to the generation excitation";
CM_ SG_ 2365433598 GnrtrOtputVoltageBiasPercentage "Measured signal that represents the voltage bias percentage of the generator ouptput voltage being requested by external to the voltage regulator.
Generator output voltage bias percentage is the amount of voltage in percent the generator output ...";
CM_ SG_ 2365433598 GeneratorExcitationFieldCurrent "Measured signal that represents the generator excitation field current.";
CM_ SG_ 2365433598 GeneratorExcitationFieldVoltage "Measured signal that represents the generator excitation field voltage.  Generator excitation field voltage is indicative of the amount of excitation current being supplied by the voltage regulator to the generator field.";
BA_DEF_ SG_  "SigType" ENUM  "Default","Range","RangeSigned","ASCII","Discrete","Control","ReferencePGN","DTC","StringDelimiter","StringLength","StringLengthControl","MessageCounter","MessageChecksum";
BA_DEF_ SG_  "GenSigStartValue" INT 0 10000;
BA_DEF_ SG_  "GenSigSendType" ENUM  "Cyclic","OnWrite","OnWriteWithRepetition","OnChange","OnChangeWithRepetition","IfActive","IfActiveWithRepetition","NoSigSendType";
BA_DEF_ SG_  "GenSigILSupport" ENUM  "No","Yes";
BA_DEF_ SG_  "GenSigEVName" STRING ;
BA_DEF_ SG_  "SPN" INT 0 524287;
BA_DEF_ BO_  "GenMsgStartDelayTime" INT 0 100000;
BA_DEF_ BO_  "GenMsgILSupport" ENUM  "No","Yes";
BA_DEF_ BO_  "GenMsgRequestable" INT 0 1;
BA_DEF_ BO_  "GenMsgSendType" ENUM  "cyclic","NotUsed","NotUsed","NotUsed","NotUsed","NotUsed","NotUsed","IfActive","noMsgSendType";
BA_DEF_ BO_  "VFrameFormat" ENUM  "StandardCAN","ExtendedCAN","reserved","J1939PG";
BA_DEF_ BO_  "GenMsgCycleTime" INT 0 3600000;
BA_DEF_ SG_  "SystemSignalLongSymbol" STRING ;
BA_DEF_DEF_  "SigType" "Default";
BA_DEF_DEF_  "GenSigStartValue" 0;
BA_DEF_DEF_  "GenSigSendType" "NoSigSendType";
BA_DEF_DEF_  "GenSigILSupport" "Yes";
BA_DEF_DEF_  "GenSigEVName" "Env@Nodename_@Signame";
BA_DEF_DEF_  "SPN" 0;
BA_DEF_DEF_  "GenMsgStartDelayTime" 0;
BA_DEF_DEF_  "GenMsgILSupport" "Yes";
BA_DEF_DEF_  "GenMsgRequestable" 1;
BA_DEF_DEF_  "GenMsgSendType" "noMsgSendType";
BA_DEF_DEF_  "VFrameFormat" "J1939PG";
BA_DEF_DEF_  "GenMsgCycleTime" 0;
BA_DEF_DEF_  "SystemSignalLongSymbol" "";
BA_ "GenMsgSendType" BO_ 2499630078 0;
BA_ "GenMsgCycleTime" BO_ 2499630078 500;
BA_ "GenMsgSendType" BO_ 2566838782 0;
BA_ "GenMsgCycleTime" BO_ 2566838782 100;
BA_ "GenMsgSendType" BO_ 2561146622 0;
BA_ "GenMsgCycleTime" BO_ 2561146622 100;
BA_ "GenMsgSendType" BO_ 2561081086 0;
BA_ "GenMsgCycleTime" BO_ 2561081086 100;
BA_ "GenMsgSendType" BO_ 2561015550 0;
BA_ "GenMsgCycleTime" BO_ 2561015550 100;
BA_ "GenMsgSendType" BO_ 2566746622 0;
BA_ "GenMsgCycleTime" BO_ 2566746622 1000;
BA_ "GenMsgSendType" BO_ 2566845950 0;
BA_ "GenMsgCycleTime" BO_ 2566845950 1000;
BA_ "GenMsgSendType" BO_ 2566827774 0;
BA_ "GenMsgCycleTime" BO_ 2566827774 1000;
BA_ "GenMsgSendType" BO_ 2566846974 0;
BA_ "GenMsgCycleTime" BO_ 2566846974 1000;
BA_ "GenMsgSendType" BO_ 2566803966 0;
BA_ "GenMsgCycleTime" BO_ 2566803966 250;
BA_ "GenMsgSendType" BO_ 2432593918 0;
BA_ "GenMsgCycleTime" BO_ 2432593918 100;
BA_ "GenMsgSendType" BO_ 2566847998 0;
BA_ "GenMsgCycleTime" BO_ 2566847998 500;
BA_ "GenMsgSendType" BO_ 2566803198 0;
BA_ "GenMsgCycleTime" BO_ 2566803198 100;
BA_ "GenMsgSendType" BO_ 2565870334 0;
BA_ "GenMsgCycleTime" BO_ 2565870334 50;
BA_ "GenMsgSendType" BO_ 2364543998 0;
BA_ "GenMsgCycleTime" BO_ 2364543998 10;
BA_ "GenMsgSendType" BO_ 2566846718 0;
BA_ "GenMsgCycleTime" BO_ 2566846718 1000;
BA_ "GenMsgSendType" BO_ 2566846462 0;
BA_ "GenMsgCycleTime" BO_ 2566846462 1000;
BA_ "GenMsgSendType" BO_ 2633869310 0;
BA_ "GenMsgCycleTime" BO_ 2633869310 1000;
BA_ "GenMsgSendType" BO_ 2365433598 0;
BA_ "GenMsgCycleTime" BO_ 2365433598 100;
BA_ "SigType" SG_ 3221225472 NumberOfMembersInWorkingSet 3;
BA_ "SPN" SG_ 3221225472 NumberOfMembersInWorkingSet 2409;
BA_ "SPN" SG_ 3221225472 NncntnuslyMonitoredSystemsStatus 1223;
BA_ "SPN" SG_ 3221225472 NncntnslyMonitoredSystemsSupport 1222;
BA_ "SPN" SG_ 3221225472 CntnslyMntrdSystmsSupport_Status 1221;
BA_ "SigType" SG_ 3221225472 AETCTorqueValue 1;
BA_ "SPN" SG_ 3221225472 AETCTorqueValue 3561;
BA_ "SigType" SG_ 3221225472 TrailerWeight 1;
BA_ "SPN" SG_ 3221225472 TrailerWeight 180;
BA_ "SPN" SG_ 3221225472 ReferenceTirePressSetting 3193;
BA_ "SPN" SG_ 3221225472 ReferenceTirePress 3191;
BA_ "SPN" SG_ 3221225472 TirePressThresholdDetection 2587;
BA_ "SigType" SG_ 3221225472 TireAirLeakageRate 1;
BA_ "SPN" SG_ 3221225472 TireAirLeakageRate 2586;
BA_ "SigType" SG_ 3221225472 CTIWheelEndElectricalFault 4;
BA_ "SPN" SG_ 3221225472 CTIWheelEndElectricalFault 1697;
BA_ "SigType" SG_ 3221225472 CTITireStatus 4;
BA_ "SPN" SG_ 3221225472 CTITireStatus 1698;
BA_ "SigType" SG_ 3221225472 CTIWheelSensorStatus 4;
BA_ "SPN" SG_ 3221225472 CTIWheelSensorStatus 1699;
BA_ "SigType" SG_ 3221225472 TireTemp 1;
BA_ "SPN" SG_ 3221225472 TireTemp 242;
BA_ "SigType" SG_ 3221225472 TirePress 1;
BA_ "SPN" SG_ 3221225472 TirePress 241;
BA_ "SigType" SG_ 3221225472 EngTurningGearEngaged 4;
BA_ "SPN" SG_ 3221225472 EngTurningGearEngaged 1206;
BA_ "SigType" SG_ 3221225472 AETCSpeedValue 1;
BA_ "SPN" SG_ 3221225472 AETCSpeedValue 3560;
BA_ "SPN" SG_ 3221225472 ManufacturerSpecificInformation 3328;
BA_ "SigType" SG_ 2566741758 FlashRedStopLamp 5;
BA_ "SPN" SG_ 2566741758 FlashRedStopLamp 3039;
BA_ "SigType" SG_ 2566741758 FlashProtectLamp 5;
BA_ "SPN" SG_ 2566741758 FlashProtectLamp 3041;
BA_ "SigType" SG_ 2566741758 FlashMalfuncIndicatorLamp 5;
BA_ "SPN" SG_ 2566741758 FlashMalfuncIndicatorLamp 3038;
BA_ "SigType" SG_ 2566741758 FlashAmberWarningLamp 5;
BA_ "SPN" SG_ 2566741758 FlashAmberWarningLamp 3040;
BA_ "SigType" SG_ 2566741758 MalfunctionIndicatorLampStatus 5;
BA_ "SPN" SG_ 2566741758 MalfunctionIndicatorLampStatus 1213;
BA_ "SigType" SG_ 2566741758 AmberWarningLampStatus 5;
BA_ "SPN" SG_ 2566741758 AmberWarningLampStatus 624;
BA_ "SigType" SG_ 2566741758 RedStopLampState 4;
BA_ "SPN" SG_ 2566741758 RedStopLampState 623;
BA_ "SigType" SG_ 2566741758 ProtectLampStatus 5;
BA_ "SPN" SG_ 2566741758 ProtectLampStatus 987;
BA_ "SigType" SG_ 2566741758 DTC5 7;
BA_ "SigType" SG_ 2566741758 DTC4 7;
BA_ "SigType" SG_ 2566741758 DTC3 7;
BA_ "SigType" SG_ 2566741758 DTC2 7;
BA_ "SigType" SG_ 2566741758 DTC1 7;
BA_ "SigType" SG_ 2566742014 FlashRedStopLamp 5;
BA_ "SPN" SG_ 2566742014 FlashRedStopLamp 3039;
BA_ "SigType" SG_ 2566742014 FlashProtectLamp 5;
BA_ "SPN" SG_ 2566742014 FlashProtectLamp 3041;
BA_ "SigType" SG_ 2566742014 FlashMalfuncIndicatorLamp 5;
BA_ "SPN" SG_ 2566742014 FlashMalfuncIndicatorLamp 3038;
BA_ "SigType" SG_ 2566742014 FlashAmberWarningLamp 5;
BA_ "SPN" SG_ 2566742014 FlashAmberWarningLamp 3040;
BA_ "SigType" SG_ 2566742014 MalfunctionIndicatorLampStatus 5;
BA_ "SPN" SG_ 2566742014 MalfunctionIndicatorLampStatus 1213;
BA_ "SigType" SG_ 2566742014 AmberWarningLampStatus 5;
BA_ "SPN" SG_ 2566742014 AmberWarningLampStatus 624;
BA_ "SigType" SG_ 2566742014 RedStopLampState 4;
BA_ "SPN" SG_ 2566742014 RedStopLampState 623;
BA_ "SigType" SG_ 2566742014 ProtectLampStatus 5;
BA_ "SPN" SG_ 2566742014 ProtectLampStatus 987;
BA_ "SigType" SG_ 2566742014 DTC5 7;
BA_ "SigType" SG_ 2566742014 DTC4 7;
BA_ "SigType" SG_ 2566742014 DTC3 7;
BA_ "SigType" SG_ 2566742014 DTC2 7;
BA_ "SigType" SG_ 2566742014 DTC1 7;
BA_ "SigType" SG_ 2560622334 FlashRedStopLamp 5;
BA_ "SPN" SG_ 2560622334 FlashRedStopLamp 3039;
BA_ "SigType" SG_ 2560622334 FlashProtectLamp 5;
BA_ "SPN" SG_ 2560622334 FlashProtectLamp 3041;
BA_ "SigType" SG_ 2560622334 FlashMalfuncIndicatorLamp 5;
BA_ "SPN" SG_ 2560622334 FlashMalfuncIndicatorLamp 3038;
BA_ "SigType" SG_ 2560622334 FlashAmberWarningLamp 5;
BA_ "SPN" SG_ 2560622334 FlashAmberWarningLamp 3040;
BA_ "SigType" SG_ 2560622334 MalfunctionIndicatorLampStatus 5;
BA_ "SPN" SG_ 2560622334 MalfunctionIndicatorLampStatus 1213;
BA_ "SigType" SG_ 2560622334 AmberWarningLampStatus 5;
BA_ "SPN" SG_ 2560622334 AmberWarningLampStatus 624;
BA_ "SigType" SG_ 2560622334 RedStopLampState 4;
BA_ "SPN" SG_ 2560622334 RedStopLampState 623;
BA_ "SigType" SG_ 2560622334 ProtectLampStatus 5;
BA_ "SPN" SG_ 2560622334 ProtectLampStatus 987;
BA_ "SigType" SG_ 2560622334 DTC5 7;
BA_ "SigType" SG_ 2560622334 DTC4 7;
BA_ "SigType" SG_ 2560622334 DTC3 7;
BA_ "SigType" SG_ 2560622334 DTC2 7;
BA_ "SigType" SG_ 2560622334 DTC1 7;
BA_ "SigType" SG_ 2566744062 ZeroNetVehicleWeightChange 5;
BA_ "SPN" SG_ 2566744062 ZeroNetVehicleWeightChange 4075;
BA_ "SigType" SG_ 2499630078 EngExhaustGasTempAverageBank2 1;
BA_ "SPN" SG_ 2499630078 EngExhaustGasTempAverageBank2 4152;
BA_ "SigType" SG_ 2499630078 EngExhaustGasTempAverageBank1 1;
BA_ "SPN" SG_ 2499630078 EngExhaustGasTempAverageBank1 4153;
BA_ "SigType" SG_ 2499630078 EngExhaustGasTempAverage 1;
BA_ "SPN" SG_ 2499630078 EngExhaustGasTempAverage 4151;
BA_ "SigType" SG_ 2359230206 PermanentDTCs 1;
BA_ "SPN" SG_ 2359230206 PermanentDTCs 4108;
BA_ "SigType" SG_ 2359230206 PreviouslyMILOnDTCs 1;
BA_ "SPN" SG_ 2359230206 PreviouslyMILOnDTCs 4107;
BA_ "SigType" SG_ 2359230206 MILOnDTCs 1;
BA_ "SPN" SG_ 2359230206 MILOnDTCs 4106;
BA_ "SigType" SG_ 2359230206 AllPendingDTCs 1;
BA_ "SPN" SG_ 2359230206 AllPendingDTCs 4105;
BA_ "SigType" SG_ 2359230206 PendingDTCs 1;
BA_ "SPN" SG_ 2359230206 PendingDTCs 4104;
BA_ "SigType" SG_ 2566750462 FlashRedStopLamp 5;
BA_ "SPN" SG_ 2566750462 FlashRedStopLamp 3039;
BA_ "SigType" SG_ 2566750462 FlashProtectLamp 5;
BA_ "SPN" SG_ 2566750462 FlashProtectLamp 3041;
BA_ "SigType" SG_ 2566750462 FlashMalfuncIndicatorLamp 5;
BA_ "SPN" SG_ 2566750462 FlashMalfuncIndicatorLamp 3038;
BA_ "SigType" SG_ 2566750462 FlashAmberWarningLamp 5;
BA_ "SPN" SG_ 2566750462 FlashAmberWarningLamp 3040;
BA_ "SigType" SG_ 2566750462 MalfunctionIndicatorLampStatus 5;
BA_ "SPN" SG_ 2566750462 MalfunctionIndicatorLampStatus 1213;
BA_ "SigType" SG_ 2566750462 AmberWarningLampStatus 5;
BA_ "SPN" SG_ 2566750462 AmberWarningLampStatus 624;
BA_ "SigType" SG_ 2566750462 RedStopLampState 4;
BA_ "SPN" SG_ 2566750462 RedStopLampState 623;
BA_ "SigType" SG_ 2566750462 ProtectLampStatus 5;
BA_ "SPN" SG_ 2566750462 ProtectLampStatus 987;
BA_ "SigType" SG_ 2566750462 DTC5 7;
BA_ "SigType" SG_ 2566750462 DTC4 7;
BA_ "SigType" SG_ 2566750462 DTC3 7;
BA_ "SigType" SG_ 2566750462 DTC2 7;
BA_ "SigType" SG_ 2566750462 DTC1 7;
BA_ "SigType" SG_ 2566750974 FlashRedStopLamp 5;
BA_ "SPN" SG_ 2566750974 FlashRedStopLamp 3039;
BA_ "SigType" SG_ 2566750974 FlashProtectLamp 5;
BA_ "SPN" SG_ 2566750974 FlashProtectLamp 3041;
BA_ "SigType" SG_ 2566750974 FlashMalfuncIndicatorLamp 5;
BA_ "SPN" SG_ 2566750974 FlashMalfuncIndicatorLamp 3038;
BA_ "SigType" SG_ 2566750974 FlashAmberWarningLamp 5;
BA_ "SPN" SG_ 2566750974 FlashAmberWarningLamp 3040;
BA_ "SigType" SG_ 2566750974 MalfunctionIndicatorLampStatus 5;
BA_ "SPN" SG_ 2566750974 MalfunctionIndicatorLampStatus 1213;
BA_ "SigType" SG_ 2566750974 AmberWarningLampStatus 5;
BA_ "SPN" SG_ 2566750974 AmberWarningLampStatus 624;
BA_ "SigType" SG_ 2566750974 RedStopLampState 4;
BA_ "SPN" SG_ 2566750974 RedStopLampState 623;
BA_ "SigType" SG_ 2566750974 ProtectLampStatus 5;
BA_ "SPN" SG_ 2566750974 ProtectLampStatus 987;
BA_ "SigType" SG_ 2566750974 DTC5 7;
BA_ "SigType" SG_ 2566750974 DTC4 7;
BA_ "SigType" SG_ 2566750974 DTC3 7;
BA_ "SigType" SG_ 2566750974 DTC2 7;
BA_ "SigType" SG_ 2566750974 DTC1 7;
BA_ "SigType" SG_ 2566754558 AETCTorqueValue14 1;
BA_ "SigType" SG_ 2566754558 AETCTorqueValue13 1;
BA_ "SigType" SG_ 2566754558 AETCTorqueValue12 1;
BA_ "SigType" SG_ 2566754558 AETCTorqueValue11 1;
BA_ "SigType" SG_ 2566754558 AETCTorqueValue10 1;
BA_ "SigType" SG_ 2566754558 AETCTorqueValue09 1;
BA_ "SigType" SG_ 2566754558 AETCTorqueValue08 1;
BA_ "SigType" SG_ 2566754558 AETCTorqueValue07 1;
BA_ "SigType" SG_ 2566754558 AETCTorqueValue06 1;
BA_ "SigType" SG_ 2566754558 AETCTorqueValue05 1;
BA_ "SigType" SG_ 2566754558 AETCTorqueValue04 1;
BA_ "SigType" SG_ 2566754558 AETCTorqueValue03 1;
BA_ "SigType" SG_ 2566754558 AETCTorqueValue02 1;
BA_ "SigType" SG_ 2566754558 AETCTorqueValue01 1;
BA_ "SigType" SG_ 2566754558 AETCSpeedValue14 1;
BA_ "SigType" SG_ 2566754558 AETCSpeedValue13 1;
BA_ "SigType" SG_ 2566754558 AETCSpeedValue12 1;
BA_ "SigType" SG_ 2566754558 AETCSpeedValue11 1;
BA_ "SigType" SG_ 2566754558 AETCSpeedValue10 1;
BA_ "SigType" SG_ 2566754558 AETCSpeedValue09 1;
BA_ "SigType" SG_ 2566754558 AETCSpeedValue08 1;
BA_ "SigType" SG_ 2566754558 AETCSpeedValue07 1;
BA_ "SigType" SG_ 2566754558 AETCSpeedValue06 1;
BA_ "SigType" SG_ 2566754558 AETCSpeedValue05 1;
BA_ "SigType" SG_ 2566754558 AETCSpeedValue04 1;
BA_ "SigType" SG_ 2566754558 AETCSpeedValue03 1;
BA_ "SigType" SG_ 2566754558 AETCSpeedValue02 1;
BA_ "SigType" SG_ 2566754558 AETCSpeedValue01 1;
BA_ "SigType" SG_ 2566754558 AETCTorqueValue00 1;
BA_ "SigType" SG_ 2566754558 AETCSpeedValue00 1;
BA_ "GenSigStartValue" SG_ 2566754558 NumberOfAETCDataPoints 5;
BA_ "SPN" SG_ 2566754558 NumberOfAETCDataPoints 3559;
BA_ "SPN" SG_ 2566754558 AETCDataCollectionStandard 3558;
BA_ "SPN" SG_ 2566749950 RightHeadlampLightDistribution 3694;
BA_ "SPN" SG_ 2566749950 LeftHeadlampLightDistribution 3693;
BA_ "SPN" SG_ 2566749950 RightHeadlampDynamicBendingLight 3692;
BA_ "SPN" SG_ 2566749950 LeftHeadlampDynamicBendingLight 3691;
BA_ "SigType" SG_ 2566838782 AuxI_OChannel2 1;
BA_ "SPN" SG_ 2566838782 AuxI_OChannel2 1084;
BA_ "SigType" SG_ 2566838782 AuxI_OChannel1 1;
BA_ "SPN" SG_ 2566838782 AuxI_OChannel1 1083;
BA_ "SigType" SG_ 2566838782 AuxI_O13 4;
BA_ "SPN" SG_ 2566838782 AuxI_O13 713;
BA_ "SigType" SG_ 2566838782 AuxI_O14 4;
BA_ "SPN" SG_ 2566838782 AuxI_O14 714;
BA_ "SigType" SG_ 2566838782 AuxI_O15 4;
BA_ "SPN" SG_ 2566838782 AuxI_O15 715;
BA_ "SigType" SG_ 2566838782 AuxI_O16 4;
BA_ "SPN" SG_ 2566838782 AuxI_O16 716;
BA_ "SigType" SG_ 2566838782 AuxI_O09 4;
BA_ "SPN" SG_ 2566838782 AuxI_O09 709;
BA_ "SigType" SG_ 2566838782 AuxI_O10 4;
BA_ "SPN" SG_ 2566838782 AuxI_O10 710;
BA_ "SigType" SG_ 2566838782 AuxI_O11 4;
BA_ "SPN" SG_ 2566838782 AuxI_O11 711;
BA_ "SigType" SG_ 2566838782 AuxI_O12 4;
BA_ "SPN" SG_ 2566838782 AuxI_O12 712;
BA_ "SigType" SG_ 2566838782 AuxI_O05 4;
BA_ "SPN" SG_ 2566838782 AuxI_O05 705;
BA_ "SigType" SG_ 2566838782 AuxI_O06 4;
BA_ "SPN" SG_ 2566838782 AuxI_O06 706;
BA_ "SigType" SG_ 2566838782 AuxI_O07 4;
BA_ "SPN" SG_ 2566838782 AuxI_O07 707;
BA_ "SigType" SG_ 2566838782 AuxI_O08 4;
BA_ "SPN" SG_ 2566838782 AuxI_O08 708;
BA_ "SigType" SG_ 2566838782 AuxI_O01 4;
BA_ "SPN" SG_ 2566838782 AuxI_O01 701;
BA_ "SigType" SG_ 2566838782 AuxI_O02 4;
BA_ "SPN" SG_ 2566838782 AuxI_O02 702;
BA_ "SigType" SG_ 2566838782 AuxI_O03 4;
BA_ "SPN" SG_ 2566838782 AuxI_O03 703;
BA_ "SigType" SG_ 2566838782 AuxI_O04 4;
BA_ "SPN" SG_ 2566838782 AuxI_O04 704;
BA_ "SigType" SG_ 2561146622 AuxI_O45 4;
BA_ "SPN" SG_ 2561146622 AuxI_O45 3868;
BA_ "SigType" SG_ 2561146622 AuxI_O46 4;
BA_ "SPN" SG_ 2561146622 AuxI_O46 3869;
BA_ "SigType" SG_ 2561146622 AuxI_O47 4;
BA_ "SPN" SG_ 2561146622 AuxI_O47 3870;
BA_ "SigType" SG_ 2561146622 AuxI_O48 4;
BA_ "SPN" SG_ 2561146622 AuxI_O48 3871;
BA_ "SigType" SG_ 2561146622 AuxI_O41 4;
BA_ "SPN" SG_ 2561146622 AuxI_O41 3864;
BA_ "SigType" SG_ 2561146622 AuxI_O42 4;
BA_ "SPN" SG_ 2561146622 AuxI_O42 3865;
BA_ "SigType" SG_ 2561146622 AuxI_O43 4;
BA_ "SPN" SG_ 2561146622 AuxI_O43 3866;
BA_ "SigType" SG_ 2561146622 AuxI_O44 4;
BA_ "SPN" SG_ 2561146622 AuxI_O44 3867;
BA_ "SigType" SG_ 2561146622 AuxI_O37 4;
BA_ "SPN" SG_ 2561146622 AuxI_O37 3860;
BA_ "SigType" SG_ 2561146622 AuxI_O38 4;
BA_ "SPN" SG_ 2561146622 AuxI_O38 3861;
BA_ "SigType" SG_ 2561146622 AuxI_O39 4;
BA_ "SPN" SG_ 2561146622 AuxI_O39 3862;
BA_ "SigType" SG_ 2561146622 AuxI_O40 4;
BA_ "SPN" SG_ 2561146622 AuxI_O40 3863;
BA_ "SigType" SG_ 2561146622 AuxI_O33 4;
BA_ "SPN" SG_ 2561146622 AuxI_O33 3856;
BA_ "SigType" SG_ 2561146622 AuxI_O34 4;
BA_ "SPN" SG_ 2561146622 AuxI_O34 3857;
BA_ "SigType" SG_ 2561146622 AuxI_O35 4;
BA_ "SPN" SG_ 2561146622 AuxI_O35 3858;
BA_ "SigType" SG_ 2561146622 AuxI_O36 4;
BA_ "SPN" SG_ 2561146622 AuxI_O36 3859;
BA_ "SigType" SG_ 2561146622 AuxI_O29 4;
BA_ "SPN" SG_ 2561146622 AuxI_O29 3852;
BA_ "SigType" SG_ 2561146622 AuxI_O30 4;
BA_ "SPN" SG_ 2561146622 AuxI_O30 3853;
BA_ "SigType" SG_ 2561146622 AuxI_O31 4;
BA_ "SPN" SG_ 2561146622 AuxI_O31 3854;
BA_ "SigType" SG_ 2561146622 AuxI_O32 4;
BA_ "SPN" SG_ 2561146622 AuxI_O32 3855;
BA_ "SigType" SG_ 2561146622 AuxI_O25 4;
BA_ "SPN" SG_ 2561146622 AuxI_O25 3848;
BA_ "SigType" SG_ 2561146622 AuxI_O26 4;
BA_ "SPN" SG_ 2561146622 AuxI_O26 3849;
BA_ "SigType" SG_ 2561146622 AuxI_O27 4;
BA_ "SPN" SG_ 2561146622 AuxI_O27 3850;
BA_ "SigType" SG_ 2561146622 AuxI_O28 4;
BA_ "SPN" SG_ 2561146622 AuxI_O28 3851;
BA_ "SigType" SG_ 2561146622 AuxI_O21 4;
BA_ "SPN" SG_ 2561146622 AuxI_O21 3844;
BA_ "SigType" SG_ 2561146622 AuxI_O22 4;
BA_ "SPN" SG_ 2561146622 AuxI_O22 3845;
BA_ "SigType" SG_ 2561146622 AuxI_O23 4;
BA_ "SPN" SG_ 2561146622 AuxI_O23 3846;
BA_ "SigType" SG_ 2561146622 AuxI_O24 4;
BA_ "SPN" SG_ 2561146622 AuxI_O24 3847;
BA_ "SigType" SG_ 2561146622 AuxI_O17 4;
BA_ "SPN" SG_ 2561146622 AuxI_O17 3840;
BA_ "SigType" SG_ 2561146622 AuxI_O18 4;
BA_ "SPN" SG_ 2561146622 AuxI_O18 3841;
BA_ "SigType" SG_ 2561146622 AuxI_O19 4;
BA_ "SPN" SG_ 2561146622 AuxI_O19 3842;
BA_ "SigType" SG_ 2561146622 AuxI_O20 4;
BA_ "SPN" SG_ 2561146622 AuxI_O20 3843;
BA_ "SigType" SG_ 2561081086 AuxI_O77 4;
BA_ "SPN" SG_ 2561081086 AuxI_O77 3900;
BA_ "SigType" SG_ 2561081086 AuxI_O78 4;
BA_ "SPN" SG_ 2561081086 AuxI_O78 3901;
BA_ "SigType" SG_ 2561081086 AuxI_O79 4;
BA_ "SPN" SG_ 2561081086 AuxI_O79 3902;
BA_ "SigType" SG_ 2561081086 AuxI_O80 4;
BA_ "SPN" SG_ 2561081086 AuxI_O80 3903;
BA_ "SigType" SG_ 2561081086 AuxI_O73 4;
BA_ "SPN" SG_ 2561081086 AuxI_O73 3896;
BA_ "SigType" SG_ 2561081086 AuxI_O74 4;
BA_ "SPN" SG_ 2561081086 AuxI_O74 3897;
BA_ "SigType" SG_ 2561081086 AuxI_O75 4;
BA_ "SPN" SG_ 2561081086 AuxI_O75 3898;
BA_ "SigType" SG_ 2561081086 AuxI_O76 4;
BA_ "SPN" SG_ 2561081086 AuxI_O76 3899;
BA_ "SigType" SG_ 2561081086 AuxI_O69 4;
BA_ "SPN" SG_ 2561081086 AuxI_O69 3892;
BA_ "SigType" SG_ 2561081086 AuxI_O70 4;
BA_ "SPN" SG_ 2561081086 AuxI_O70 3893;
BA_ "SigType" SG_ 2561081086 AuxI_O71 4;
BA_ "SPN" SG_ 2561081086 AuxI_O71 3894;
BA_ "SigType" SG_ 2561081086 AuxI_O72 4;
BA_ "SPN" SG_ 2561081086 AuxI_O72 3895;
BA_ "SigType" SG_ 2561081086 AuxI_O65 4;
BA_ "SPN" SG_ 2561081086 AuxI_O65 3888;
BA_ "SigType" SG_ 2561081086 AuxI_O66 4;
BA_ "SPN" SG_ 2561081086 AuxI_O66 3889;
BA_ "SigType" SG_ 2561081086 AuxI_O67 4;
BA_ "SPN" SG_ 2561081086 AuxI_O67 3890;
BA_ "SigType" SG_ 2561081086 AuxI_O68 4;
BA_ "SPN" SG_ 2561081086 AuxI_O68 3891;
BA_ "SigType" SG_ 2561081086 AuxI_O61 4;
BA_ "SPN" SG_ 2561081086 AuxI_O61 3884;
BA_ "SigType" SG_ 2561081086 AuxI_O62 4;
BA_ "SPN" SG_ 2561081086 AuxI_O62 3885;
BA_ "SigType" SG_ 2561081086 AuxI_O63 4;
BA_ "SPN" SG_ 2561081086 AuxI_O63 3886;
BA_ "SigType" SG_ 2561081086 AuxI_O64 4;
BA_ "SPN" SG_ 2561081086 AuxI_O64 3887;
BA_ "SigType" SG_ 2561081086 AuxI_O57 4;
BA_ "SPN" SG_ 2561081086 AuxI_O57 3880;
BA_ "SigType" SG_ 2561081086 AuxI_O58 4;
BA_ "SPN" SG_ 2561081086 AuxI_O58 3881;
BA_ "SigType" SG_ 2561081086 AuxI_O59 4;
BA_ "SPN" SG_ 2561081086 AuxI_O59 3882;
BA_ "SigType" SG_ 2561081086 AuxI_O60 4;
BA_ "SPN" SG_ 2561081086 AuxI_O60 3883;
BA_ "SigType" SG_ 2561081086 AuxI_O53 4;
BA_ "SPN" SG_ 2561081086 AuxI_O53 3876;
BA_ "SigType" SG_ 2561081086 AuxI_O54 4;
BA_ "SPN" SG_ 2561081086 AuxI_O54 3877;
BA_ "SigType" SG_ 2561081086 AuxI_O55 4;
BA_ "SPN" SG_ 2561081086 AuxI_O55 3878;
BA_ "SigType" SG_ 2561081086 AuxI_O56 4;
BA_ "SPN" SG_ 2561081086 AuxI_O56 3879;
BA_ "SigType" SG_ 2561081086 AuxI_O49 4;
BA_ "SPN" SG_ 2561081086 AuxI_O49 3872;
BA_ "SigType" SG_ 2561081086 AuxI_O50 4;
BA_ "SPN" SG_ 2561081086 AuxI_O50 3873;
BA_ "SigType" SG_ 2561081086 AuxI_O51 4;
BA_ "SPN" SG_ 2561081086 AuxI_O51 3874;
BA_ "SigType" SG_ 2561081086 AuxI_O52 4;
BA_ "SPN" SG_ 2561081086 AuxI_O52 3875;
BA_ "SigType" SG_ 2561015550 AuxI_O109 4;
BA_ "SPN" SG_ 2561015550 AuxI_O109 3932;
BA_ "SigType" SG_ 2561015550 AuxI_O110 4;
BA_ "SPN" SG_ 2561015550 AuxI_O110 3933;
BA_ "SigType" SG_ 2561015550 AuxI_O111 4;
BA_ "SPN" SG_ 2561015550 AuxI_O111 3934;
BA_ "SigType" SG_ 2561015550 AuxI_O112 4;
BA_ "SPN" SG_ 2561015550 AuxI_O112 3935;
BA_ "SigType" SG_ 2561015550 AuxI_O105 4;
BA_ "SPN" SG_ 2561015550 AuxI_O105 3928;
BA_ "SigType" SG_ 2561015550 AuxI_O106 4;
BA_ "SPN" SG_ 2561015550 AuxI_O106 3929;
BA_ "SigType" SG_ 2561015550 AuxI_O107 4;
BA_ "SPN" SG_ 2561015550 AuxI_O107 3930;
BA_ "SigType" SG_ 2561015550 AuxI_O108 4;
BA_ "SPN" SG_ 2561015550 AuxI_O108 3931;
BA_ "SigType" SG_ 2561015550 AuxI_O101 4;
BA_ "SPN" SG_ 2561015550 AuxI_O101 3924;
BA_ "SigType" SG_ 2561015550 AuxI_O102 4;
BA_ "SPN" SG_ 2561015550 AuxI_O102 3925;
BA_ "SigType" SG_ 2561015550 AuxI_O103 4;
BA_ "SPN" SG_ 2561015550 AuxI_O103 3926;
BA_ "SigType" SG_ 2561015550 AuxI_O104 4;
BA_ "SPN" SG_ 2561015550 AuxI_O104 3927;
BA_ "SigType" SG_ 2561015550 AuxI_O97 4;
BA_ "SPN" SG_ 2561015550 AuxI_O97 3920;
BA_ "SigType" SG_ 2561015550 AuxI_O98 4;
BA_ "SPN" SG_ 2561015550 AuxI_O98 3921;
BA_ "SigType" SG_ 2561015550 AuxI_O99 4;
BA_ "SPN" SG_ 2561015550 AuxI_O99 3922;
BA_ "SigType" SG_ 2561015550 AuxI_O100 4;
BA_ "SPN" SG_ 2561015550 AuxI_O100 3923;
BA_ "SigType" SG_ 2561015550 AuxI_O93 4;
BA_ "SPN" SG_ 2561015550 AuxI_O93 3916;
BA_ "SigType" SG_ 2561015550 AuxI_O94 4;
BA_ "SPN" SG_ 2561015550 AuxI_O94 3917;
BA_ "SigType" SG_ 2561015550 AuxI_O95 4;
BA_ "SPN" SG_ 2561015550 AuxI_O95 3918;
BA_ "SigType" SG_ 2561015550 AuxI_O96 4;
BA_ "SPN" SG_ 2561015550 AuxI_O96 3919;
BA_ "SigType" SG_ 2561015550 AuxI_O89 4;
BA_ "SPN" SG_ 2561015550 AuxI_O89 3912;
BA_ "SigType" SG_ 2561015550 AuxI_O90 4;
BA_ "SPN" SG_ 2561015550 AuxI_O90 3913;
BA_ "SigType" SG_ 2561015550 AuxI_O91 4;
BA_ "SPN" SG_ 2561015550 AuxI_O91 3914;
BA_ "SigType" SG_ 2561015550 AuxI_O92 4;
BA_ "SPN" SG_ 2561015550 AuxI_O92 3915;
BA_ "SigType" SG_ 2561015550 AuxI_O85 4;
BA_ "SPN" SG_ 2561015550 AuxI_O85 3908;
BA_ "SigType" SG_ 2561015550 AuxI_O86 4;
BA_ "SPN" SG_ 2561015550 AuxI_O86 3909;
BA_ "SigType" SG_ 2561015550 AuxI_O87 4;
BA_ "SPN" SG_ 2561015550 AuxI_O87 3910;
BA_ "SigType" SG_ 2561015550 AuxI_O88 4;
BA_ "SPN" SG_ 2561015550 AuxI_O88 3911;
BA_ "SigType" SG_ 2561015550 AuxI_O81 4;
BA_ "SPN" SG_ 2561015550 AuxI_O81 3904;
BA_ "SigType" SG_ 2561015550 AuxI_O82 4;
BA_ "SPN" SG_ 2561015550 AuxI_O82 3905;
BA_ "SigType" SG_ 2561015550 AuxI_O83 4;
BA_ "SPN" SG_ 2561015550 AuxI_O83 3906;
BA_ "SigType" SG_ 2561015550 AuxI_O84 4;
BA_ "SPN" SG_ 2561015550 AuxI_O84 3907;
BA_ "SPN" SG_ 2566746622 TrailerBrakeStrokeAxle5Right 3804;
BA_ "SPN" SG_ 2566746622 TrailerBrakeStrokeAxle5Left 3803;
BA_ "SPN" SG_ 2566746622 TrailerBrakeStrokeAxle4Right 3802;
BA_ "SPN" SG_ 2566746622 TrailerBrakeStrokeAxle4Left 3801;
BA_ "SPN" SG_ 2566746622 TrailerBrakeStrokeAxle3Right 3800;
BA_ "SPN" SG_ 2566746622 TrailerBrakeStrokeAxle3Left 3799;
BA_ "SPN" SG_ 2566746622 TrailerBrakeStrokeAxle2Right 3798;
BA_ "SPN" SG_ 2566746622 TrailerBrakeStrokeAxle2Left 3797;
BA_ "SPN" SG_ 2566746622 TrailerBrakeStrokeAxle1Right 3796;
BA_ "SPN" SG_ 2566746622 TrailerBrakeStrokeAxle1Left 3795;
BA_ "SPN" SG_ 2566746622 TractorBrakeStrokeAxle5Right 3794;
BA_ "SPN" SG_ 2566746622 TractorBrakeStrokeAxle5Left 3793;
BA_ "SPN" SG_ 2566746622 TractorBrakeStrokeAxle4Right 3792;
BA_ "SPN" SG_ 2566746622 TractorBrakeStrokeAxle4Left 3791;
BA_ "SPN" SG_ 2566746622 TractorBrakeStrokeAxle3Right 3790;
BA_ "SPN" SG_ 2566746622 TractorBrakeStrokeAxle3Left 3789;
BA_ "SPN" SG_ 2566746622 TractorBrakeStrokeAxle2Right 3788;
BA_ "SPN" SG_ 2566746622 TractorBrakeStrokeAxle2Left 3787;
BA_ "SPN" SG_ 2566746622 TractorBrakeStrokeAxle1Right 3786;
BA_ "SPN" SG_ 2566746622 TractorBrakeStrokeAxle1Left 3785;
BA_ "SigType" SG_ 2566845950 RoadSurfaceTemp 1;
BA_ "SPN" SG_ 2566845950 RoadSurfaceTemp 79;
BA_ "SigType" SG_ 2566845950 EngAirIntakeTemp 1;
BA_ "SPN" SG_ 2566845950 EngAirIntakeTemp 172;
BA_ "SigType" SG_ 2566845950 AmbientAirTemp 1;
BA_ "SPN" SG_ 2566845950 AmbientAirTemp 171;
BA_ "SigType" SG_ 2566845950 CabInteriorTemp 1;
BA_ "SPN" SG_ 2566845950 CabInteriorTemp 170;
BA_ "SigType" SG_ 2566845950 BarometricPress 1;
BA_ "SPN" SG_ 2566845950 BarometricPress 108;
BA_ "SigType" SG_ 2566840062 EngAirStartPress 1;
BA_ "SPN" SG_ 2566840062 EngAirStartPress 82;
BA_ "SigType" SG_ 2566827774 AirCompressorStatus 4;
BA_ "SPN" SG_ 2566827774 AirCompressorStatus 1351;
BA_ "SigType" SG_ 2566827774 AirSuspensionSupplyPress 1;
BA_ "SPN" SG_ 2566827774 AirSuspensionSupplyPress 1090;
BA_ "SigType" SG_ 2566827774 AuxEquipmentSupplyPress 1;
BA_ "SPN" SG_ 2566827774 AuxEquipmentSupplyPress 1089;
BA_ "SigType" SG_ 2566827774 PowertrainCircuitAirSupplyPress 1;
BA_ "SPN" SG_ 2566827774 PowertrainCircuitAirSupplyPress 6305;
BA_ "SigType" SG_ 2566827774 ServiceBrakeCircuit2AirPress 1;
BA_ "SPN" SG_ 2566827774 ServiceBrakeCircuit2AirPress 1088;
BA_ "SigType" SG_ 2566827774 ServiceBrakeCircuit1AirPress 1;
BA_ "SPN" SG_ 2566827774 ServiceBrakeCircuit1AirPress 1087;
BA_ "SigType" SG_ 2566827774 ParkingAnd_orTrailerAirPress 1;
BA_ "SPN" SG_ 2566827774 ParkingAnd_orTrailerAirPress 1086;
BA_ "SigType" SG_ 2566827774 PneumaticSupplyPress 1;
BA_ "SPN" SG_ 2566827774 PneumaticSupplyPress 46;
BA_ "SigType" SG_ 2566846974 SteerAxleLubePress 1;
BA_ "SPN" SG_ 2566846974 SteerAxleLubePress 2614;
BA_ "SigType" SG_ 2566846974 SteerAxleTemp 1;
BA_ "SPN" SG_ 2566846974 SteerAxleTemp 75;
BA_ "SigType" SG_ 2566846974 DriveAxleLubePress 1;
BA_ "SPN" SG_ 2566846974 DriveAxleLubePress 2613;
BA_ "SigType" SG_ 2566846974 DriveAxleTemp 1;
BA_ "SPN" SG_ 2566846974 DriveAxleTemp 578;
BA_ "SigType" SG_ 2566846974 DriveAxleLiftAirPress 1;
BA_ "SPN" SG_ 2566846974 DriveAxleLiftAirPress 579;
BA_ "SPN" SG_ 2566846974 DriveAxleLocation 930;
BA_ "SigType" SG_ 2633935614 EngGsMssFlwSnsrFuelingCorrection 1;
BA_ "SPN" SG_ 2633935614 EngGsMssFlwSnsrFuelingCorrection 1694;
BA_ "SigType" SG_ 2633935614 GsFlInjctonPulseCorrectionFactor 1;
BA_ "GenSigStartValue" SG_ 2633935614 GsFlInjctonPulseCorrectionFactor 32128;
BA_ "SPN" SG_ 2633935614 GsFlInjctonPulseCorrectionFactor 6649;
BA_ "SigType" SG_ 2633935614 EngTurboWastegateValvePos 1;
BA_ "SPN" SG_ 2633935614 EngTurboWastegateValvePos 1693;
BA_ "SigType" SG_ 2633935614 EngDesiredAbsIntakeManifoldPress 1;
BA_ "SPN" SG_ 2633935614 EngDesiredAbsIntakeManifoldPress 1692;
BA_ "SigType" SG_ 2633935614 EngGasFuelCorrectionFactor 1;
BA_ "SPN" SG_ 2633935614 EngGasFuelCorrectionFactor 1116;
BA_ "SPN" SG_ 2566803966 RequestedACCDistanceMode 1799;
BA_ "SigType" SG_ 2566803966 ACCUsageDemand 5;
BA_ "SPN" SG_ 2566803966 ACCUsageDemand 5023;
BA_ "SigType" SG_ 2432593918 ForwardCollisionWarning 5;
BA_ "SPN" SG_ 2432593918 ForwardCollisionWarning 5022;
BA_ "SigType" SG_ 2432593918 ACCDistanceAlertSignal 5;
BA_ "SPN" SG_ 2432593918 ACCDistanceAlertSignal 1796;
BA_ "SigType" SG_ 2432593918 ACCSystemShutoffWarning 5;
BA_ "SPN" SG_ 2432593918 ACCSystemShutoffWarning 1797;
BA_ "SigType" SG_ 2432593918 ACCTargetDetected 5;
BA_ "SPN" SG_ 2432593918 ACCTargetDetected 1798;
BA_ "SigType" SG_ 2432593918 RoadCurvature 1;
BA_ "SPN" SG_ 2432593918 RoadCurvature 1591;
BA_ "SPN" SG_ 2432593918 AdptiveCruiseCtrlSetDistanceMode 1589;
BA_ "SPN" SG_ 2432593918 AdaptiveCruiseCtrlMode 1590;
BA_ "SigType" SG_ 2432593918 AdaptiveCruiseCtrlSetSpeed 1;
BA_ "SPN" SG_ 2432593918 AdaptiveCruiseCtrlSetSpeed 1588;
BA_ "SigType" SG_ 2432593918 DistanceToForwardVehicle 1;
BA_ "SPN" SG_ 2432593918 DistanceToForwardVehicle 1587;
BA_ "SigType" SG_ 2432593918 SpeedOfForwardVehicle 1;
BA_ "SPN" SG_ 2432593918 SpeedOfForwardVehicle 1586;
BA_ "SigType" SG_ 2633935102 ArticulationAngle 1;
BA_ "SPN" SG_ 2633935102 ArticulationAngle 1120;
BA_ "SigType" SG_ 2633927934 RelativeHumidity 1;
BA_ "SPN" SG_ 2633927934 RelativeHumidity 354;
BA_ "SigType" SG_ 2633927934 AuxLevel 1;
BA_ "SPN" SG_ 2633927934 AuxLevel 3087;
BA_ "SigType" SG_ 2633927934 AuxPress2 1;
BA_ "SPN" SG_ 2633927934 AuxPress2 1388;
BA_ "SigType" SG_ 2633927934 AuxPress1 1;
BA_ "SPN" SG_ 2633927934 AuxPress1 1387;
BA_ "SigType" SG_ 2633927934 AuxTemp2 1;
BA_ "SPN" SG_ 2633927934 AuxTemp2 442;
BA_ "SigType" SG_ 2633927934 AuxTemp1 1;
BA_ "SPN" SG_ 2633927934 AuxTemp1 441;
BA_ "SigType" SG_ 2566847998 EngBlowerBypassValvePos 1;
BA_ "SPN" SG_ 2566847998 EngBlowerBypassValvePos 72;
BA_ "SigType" SG_ 2566847998 EngGasSupplyPress 1;
BA_ "SPN" SG_ 2566847998 EngGasSupplyPress 159;
BA_ "SPN" SG_ 2364079870 AddressBusy 3293;
BA_ "SigType" SG_ 2364079870 ControlByte 6;
BA_ "SPN" SG_ 2364079870 ControlByte 2541;
BA_ "SigType" SG_ 2364079870 ParameterGroupNumber 6;
BA_ "SPN" SG_ 2364079870 ParameterGroupNumber 2547;
BA_ "SigType" SG_ 2364079870 GroupFunctionValue 1;
BA_ "SPN" SG_ 2364079870 AddressAccessDenied 3292;
BA_ "SPN" SG_ 2364079870 AddressNegativeAcknowledgement 3291;
BA_ "SPN" SG_ 2364079870 AddressAcknowledged 3290;
BA_ "SigType" SG_ 2566803198 Status2OfDoors 4;
BA_ "SPN" SG_ 2566803198 Status2OfDoors 3411;
BA_ "SigType" SG_ 2566803198 Ramp_WheelChairLiftPos 4;
BA_ "SPN" SG_ 2566803198 Ramp_WheelChairLiftPos 1820;
BA_ "SPN" SG_ 2566803198 PosOfDoors 1821;
BA_ "SigType" SG_ 2565870334 FifthWheelRollWarningIndicator 5;
BA_ "SPN" SG_ 2565870334 FifthWheelRollWarningIndicator 3317;
BA_ "SigType" SG_ 2565870334 FifthWheelRollMoment 1;
BA_ "SPN" SG_ 2565870334 FifthWheelRollMoment 3310;
BA_ "SigType" SG_ 2565870334 FifthWheelDrawbarForce 1;
BA_ "SPN" SG_ 2565870334 FifthWheelDrawbarForce 3309;
BA_ "SigType" SG_ 2565870334 FifthWheelVerticalForce 1;
BA_ "SPN" SG_ 2565870334 FifthWheelVerticalForce 3308;
BA_ "SigType" SG_ 2566762238 FifthWheelSliderLockIndicator 4;
BA_ "SPN" SG_ 2566762238 FifthWheelSliderLockIndicator 3316;
BA_ "SigType" SG_ 2566762238 FifthWheelSliderPos 1;
BA_ "SPN" SG_ 2566762238 FifthWheelSliderPos 3311;
BA_ "SigType" SG_ 2566762238 FfthWhlLockCoupleStatusIndicator 5;
BA_ "SPN" SG_ 2566762238 FfthWhlLockCoupleStatusIndicator 3313;
BA_ "SigType" SG_ 2566762238 FfthWhlLckReadyToCoupleIndicator 5;
BA_ "SPN" SG_ 2566762238 FfthWhlLckReadyToCoupleIndicator 3312;
BA_ "SPN" SG_ 2566762238 FifthWheelErrorStatus 3307;
BA_ "SigType" SG_ 2364543998 RollAndPitchMeasurementLatency 1;
BA_ "SPN" SG_ 2364543998 RollAndPitchMeasurementLatency 3327;
BA_ "SigType" SG_ 2364543998 PitchAndRollCompensated 5;
BA_ "SPN" SG_ 2364543998 PitchAndRollCompensated 3326;
BA_ "SigType" SG_ 2364543998 PitchRateFigureOfMerit 5;
BA_ "SPN" SG_ 2364543998 PitchRateFigureOfMerit 3325;
BA_ "SigType" SG_ 2364543998 RollAngleFigureOfMerit 5;
BA_ "SPN" SG_ 2364543998 RollAngleFigureOfMerit 3324;
BA_ "SigType" SG_ 2364543998 PitchAngleFigureOfMerit 5;
BA_ "SPN" SG_ 2364543998 PitchAngleFigureOfMerit 3323;
BA_ "SigType" SG_ 2364543998 PitchRate 1;
BA_ "SPN" SG_ 2364543998 PitchRate 3322;
BA_ "SigType" SG_ 2364543998 RollAngle 1;
BA_ "SPN" SG_ 2364543998 RollAngle 3319;
BA_ "SigType" SG_ 2364543998 PitchAngle 1;
BA_ "SPN" SG_ 2364543998 PitchAngle 3318;
BA_ "SPN" SG_ 2566846718 TransOilLevel1MeasurementStatus 3026;
BA_ "SPN" SG_ 2566846718 TransOilLevel1CountdownTimer 3028;
BA_ "SigType" SG_ 2566846718 TransOilLevel1High_Low 1;
BA_ "SPN" SG_ 2566846718 TransOilLevel1High_Low 3027;
BA_ "SigType" SG_ 2566846718 TransOilTemp1 1;
BA_ "SPN" SG_ 2566846718 TransOilTemp1 177;
BA_ "SigType" SG_ 2566846718 TransOilPress 1;
BA_ "SPN" SG_ 2566846718 TransOilPress 127;
BA_ "SigType" SG_ 2566846718 TransFilterDiffPress 1;
BA_ "SPN" SG_ 2566846718 TransFilterDiffPress 126;
BA_ "SigType" SG_ 2566846718 TransOilLevel1 1;
BA_ "SPN" SG_ 2566846718 TransOilLevel1 124;
BA_ "SigType" SG_ 2566846718 ClutchPress 1;
BA_ "SPN" SG_ 2566846718 ClutchPress 123;
BA_ "SigType" SG_ 2566846462 KeyswitchBatteryPotential 1;
BA_ "SPN" SG_ 2566846462 KeyswitchBatteryPotential 158;
BA_ "SigType" SG_ 2566846462 BatteryPotential_PowerInput1 1;
BA_ "SPN" SG_ 2566846462 BatteryPotential_PowerInput1 168;
BA_ "SigType" SG_ 2566846462 ChargingSystemPotential 1;
BA_ "SPN" SG_ 2566846462 ChargingSystemPotential 167;
BA_ "SigType" SG_ 2566846462 AltCurrent 1;
BA_ "SPN" SG_ 2566846462 AltCurrent 115;
BA_ "SigType" SG_ 2566846462 NetBatteryCurrent 1;
BA_ "SPN" SG_ 2566846462 NetBatteryCurrent 114;
BA_ "SPN" SG_ 2566760702 WrelessCommunicationNetworkType2 3446;
BA_ "SigType" SG_ 2566760702 NetworkSignalStrength2 1;
BA_ "SPN" SG_ 2566760702 NetworkSignalStrength2 3445;
BA_ "SPN" SG_ 2566760702 NetworkAntennaStatus2 3444;
BA_ "SPN" SG_ 2566760702 NetworkServiceStatus2 3443;
BA_ "SPN" SG_ 2566760702 NetworkTransceiverStatus2 3442;
BA_ "SPN" SG_ 2566760958 WrelessCommunicationNetworkType1 3372;
BA_ "SigType" SG_ 2566760958 NetworkSignalStrength1 1;
BA_ "SPN" SG_ 2566760958 NetworkSignalStrength1 3371;
BA_ "SPN" SG_ 2566760958 NetworkAntennaStatus1 3370;
BA_ "SPN" SG_ 2566760958 NetworkServiceStatus1 3369;
BA_ "SPN" SG_ 2566760958 NetworkTransceiverStatus1 3368;
BA_ "SigType" SG_ 2633869310 VoltageRegulatorEnabled 5;
BA_ "SPN" SG_ 2633869310 VoltageRegulatorEnabled 3379;
BA_ "SigType" SG_ 2633869310 VoltageRegulatorSoftStartState 5;
BA_ "SPN" SG_ 2633869310 VoltageRegulatorSoftStartState 3378;
BA_ "SigType" SG_ 2633869310 VltgRgltrUndrfrqncyCmpnstnEnbld 5;
BA_ "SPN" SG_ 2633869310 VltgRgltrUndrfrqncyCmpnstnEnbld 3377;
BA_ "SPN" SG_ 2633869310 VltgRgltrVAr_PwrFctrOprtingMode 3376;
BA_ "SPN" SG_ 2633869310 VltgRglatorLoadCompensationMode 3375;
BA_ "SigType" SG_ 2365433598 GnrtrOtputVoltageBiasPercentage 1;
BA_ "SPN" SG_ 2365433598 GnrtrOtputVoltageBiasPercentage 3382;
BA_ "SigType" SG_ 2365433598 GeneratorExcitationFieldCurrent 1;
BA_ "SPN" SG_ 2365433598 GeneratorExcitationFieldCurrent 3381;
BA_ "SigType" SG_ 2365433598 GeneratorExcitationFieldVoltage 1;
BA_ "SPN" SG_ 2365433598 GeneratorExcitationFieldVoltage 3380;
VAL_ 3221225472 TirePressThresholdDetection 7 "Not available" 6 "Error indicator" 5 "Not defined" 4 "Extreme under pressure  The tire pressure is at a level where the safety of the vehicle may be jeopardised" 3 "Under pressure  The tire pressure is lower than the pressure defined by the vehicle or tire manufacturer" 2 "No warning pressure  The tire pressure is within the thresholds defined by the vehicle or tire manufacturer" 1 "Over pressure  The tire pressure is higher than the pressure defined by the vehicle or tire manufacturer" 0 "Extreme over pressure  The tire pressure is at a level where the safety of the vehicle may be jeopardised" ;
VAL_ 3221225472 CTIWheelEndElectricalFault 3 "Not Supported" 2 "Error" 1 "Not Defined" 0 "Ok  No Fault" ;
VAL_ 3221225472 CTITireStatus 3 "Not Supported" 2 "Error" 1 "Tire leak detected" 0 "Ok no fault" ;
VAL_ 3221225472 CTIWheelSensorStatus 3 "Not Supported" 2 "Not Defined" 1 "On tire is polled" 0 "Off / isolated from CTI Pressure Controller" ;
VAL_ 3221225472 EngTurningGearEngaged 1 "Engaged" 0 "Not engaged" 3 "Not available" 2 "Error" ;
VAL_ 2566741758 FlashRedStopLamp 3 "Unavailable / Do Not Flash" 2 "Reserved" 1 "Fast Flash" 0 "Slow Flash" ;
VAL_ 2566741758 FlashProtectLamp 3 "Unavailable / Do Not Flash" 2 "Reserved" 1 "Fast Flash" 0 "Slow Flash" ;
VAL_ 2566741758 FlashMalfuncIndicatorLamp 3 "Unavailable / Do Not Flash" 2 "Reserved" 1 "Fast Flash" 0 "Slow Flash" ;
VAL_ 2566741758 FlashAmberWarningLamp 3 "Unavailable / Do Not Flash" 2 "Reserved" 1 "Fast Flash" 0 "Slow Flash" ;
VAL_ 2566741758 MalfunctionIndicatorLampStatus 3 "Not available" 2 "Reserved" 1 "Lamp on" 0 "Lamp off" ;
VAL_ 2566741758 AmberWarningLampStatus 3 "Not available" 2 "Reserved" 1 "Lamp on" 0 "Lamp off" ;
VAL_ 2566741758 RedStopLampState 3 "Not available" 2 "Reserved" 1 "Lamp on" 0 "Lamp off" ;
VAL_ 2566741758 ProtectLampStatus 3 "Not available" 2 "Reserved" 1 "Lamp on" 0 "Lamp off" ;
VAL_ 2566742014 FlashRedStopLamp 3 "Unavailable / Do Not Flash" 2 "Reserved" 1 "Fast Flash" 0 "Slow Flash" ;
VAL_ 2566742014 FlashProtectLamp 3 "Unavailable / Do Not Flash" 2 "Reserved" 1 "Fast Flash" 0 "Slow Flash" ;
VAL_ 2566742014 FlashMalfuncIndicatorLamp 3 "Unavailable / Do Not Flash" 2 "Reserved" 1 "Fast Flash" 0 "Slow Flash" ;
VAL_ 2566742014 FlashAmberWarningLamp 3 "Unavailable / Do Not Flash" 2 "Reserved" 1 "Fast Flash" 0 "Slow Flash" ;
VAL_ 2566742014 MalfunctionIndicatorLampStatus 3 "Not available" 2 "Reserved" 1 "Lamp on" 0 "Lamp off" ;
VAL_ 2566742014 AmberWarningLampStatus 3 "Not available" 2 "Reserved" 1 "Lamp on" 0 "Lamp off" ;
VAL_ 2566742014 RedStopLampState 3 "Not available" 2 "Reserved" 1 "Lamp on" 0 "Lamp off" ;
VAL_ 2566742014 ProtectLampStatus 3 "Not available" 2 "Reserved" 1 "Lamp on" 0 "Lamp off" ;
VAL_ 2560622334 FlashRedStopLamp 3 "Unavailable / Do Not Flash" 2 "Reserved" 1 "Fast Flash" 0 "Slow Flash" ;
VAL_ 2560622334 FlashProtectLamp 3 "Unavailable / Do Not Flash" 2 "Reserved" 1 "Fast Flash" 0 "Slow Flash" ;
VAL_ 2560622334 FlashMalfuncIndicatorLamp 3 "Unavailable / Do Not Flash" 2 "Reserved" 1 "Fast Flash" 0 "Slow Flash" ;
VAL_ 2560622334 FlashAmberWarningLamp 3 "Unavailable / Do Not Flash" 2 "Reserved" 1 "Fast Flash" 0 "Slow Flash" ;
VAL_ 2560622334 MalfunctionIndicatorLampStatus 3 "Not available" 2 "Reserved" 1 "Lamp on" 0 "Lamp off" ;
VAL_ 2560622334 AmberWarningLampStatus 3 "Not available" 2 "Reserved" 1 "Lamp on" 0 "Lamp off" ;
VAL_ 2560622334 RedStopLampState 3 "Not available" 2 "Reserved" 1 "Lamp on" 0 "Lamp off" ;
VAL_ 2560622334 ProtectLampStatus 3 "Not available" 2 "Reserved" 1 "Lamp on" 0 "Lamp off" ;
VAL_ 2566744062 ZeroNetVehicleWeightChange 3 "Not available / Not applicable" 2 "Reserved" 1 "Zero Net Vehicle Weight Change" 0 "No change to Net Vehicle Weight Change" ;
VAL_ 2566750462 FlashRedStopLamp 3 "Unavailable / Do Not Flash" 2 "Reserved" 1 "Fast Flash" 0 "Slow Flash" ;
VAL_ 2566750462 FlashProtectLamp 3 "Unavailable / Do Not Flash" 2 "Reserved" 1 "Fast Flash" 0 "Slow Flash" ;
VAL_ 2566750462 FlashMalfuncIndicatorLamp 3 "Unavailable / Do Not Flash" 2 "Reserved" 1 "Fast Flash" 0 "Slow Flash" ;
VAL_ 2566750462 FlashAmberWarningLamp 3 "Unavailable / Do Not Flash" 2 "Reserved" 1 "Fast Flash" 0 "Slow Flash" ;
VAL_ 2566750462 MalfunctionIndicatorLampStatus 3 "Not available" 2 "Reserved" 1 "Lamp on" 0 "Lamp off" ;
VAL_ 2566750462 AmberWarningLampStatus 3 "Not available" 2 "Reserved" 1 "Lamp on" 0 "Lamp off" ;
VAL_ 2566750462 RedStopLampState 3 "Not available" 2 "Reserved" 1 "Lamp on" 0 "Lamp off" ;
VAL_ 2566750462 ProtectLampStatus 3 "Not available" 2 "Reserved" 1 "Lamp on" 0 "Lamp off" ;
VAL_ 2566750974 FlashRedStopLamp 3 "Unavailable / Do Not Flash" 2 "Reserved" 1 "Fast Flash" 0 "Slow Flash" ;
VAL_ 2566750974 FlashProtectLamp 3 "Unavailable / Do Not Flash" 2 "Reserved" 1 "Fast Flash" 0 "Slow Flash" ;
VAL_ 2566750974 FlashMalfuncIndicatorLamp 3 "Unavailable / Do Not Flash" 2 "Reserved" 1 "Fast Flash" 0 "Slow Flash" ;
VAL_ 2566750974 FlashAmberWarningLamp 3 "Unavailable / Do Not Flash" 2 "Reserved" 1 "Fast Flash" 0 "Slow Flash" ;
VAL_ 2566750974 MalfunctionIndicatorLampStatus 3 "Not available" 2 "Reserved" 1 "Lamp on" 0 "Lamp off" ;
VAL_ 2566750974 AmberWarningLampStatus 3 "Not available" 2 "Reserved" 1 "Lamp on" 0 "Lamp off" ;
VAL_ 2566750974 RedStopLampState 3 "Not available" 2 "Reserved" 1 "Lamp on" 0 "Lamp off" ;
VAL_ 2566750974 ProtectLampStatus 3 "Not available" 2 "Reserved" 1 "Lamp on" 0 "Lamp off" ;
VAL_ 2566754558 AETCDataCollectionStandard 15 "Not Available" 0 "SAE J1995" ;
VAL_ 2566749950 RightHeadlampLightDistribution 15 "Not available" 7 "Different light distributions not available No AFS distributions available Head lamp has only one distribution" 6 "Light distribution failure  Module is damaged current position may affect oncoming traffic" 5 "Light distribution fail safe position  Module is damaged current light distribution does not affect oncoming traffic" 4 "Light distribution adverse weather  The adverse weather light improves the viewing situation for the driver on wet" 3 "Light distribution high beam  The high beam distribution of the module generates an illumination level that an" 2 "Light distribution motorway  The task of motorway light is an improved overall viewing distance and an optimum of" 1 "Light distribution country  Country light is mostly similar to the actual SAE low beam pattern Class C" 0 "Light distribution town  The basic light distribution for town light is generated with a symmetrical cutoff line Class" ;
VAL_ 2566749950 LeftHeadlampLightDistribution 15 "Not available" 7 "Different light distributions not available No AFS distributions available Head lamp has only one distribution" 6 "Light distribution failure  Module is damaged current position may affect oncoming traffic" 5 "Light distribution fail safe position  Module is damaged current light distribution does not affect oncoming traffic" 4 "Light distribution adverse weather  The adverse weather light improves the viewing situation for the driver on wet" 3 "Light distribution high beam  The high beam distribution of the module generates an illumination level that an" 2 "Light distribution motorway  The task of motorway light is an improved overall viewing distance and an optimum of" 1 "Light distribution country  Country light is mostly similar to the actual SAE low beam pattern Class C" 0 "Light distribution town  The basic light distribution for town light is generated with a symmetrical cutoff line Class" ;
VAL_ 2566749950 RightHeadlampDynamicBendingLight 7 "Not available" 3 "Dynamic bending light failure Bending light does not work current position may affect oncoming traffic" 2 "Dynamic bending light fail safe position Bending light is damaged current position does not affect oncoming traffic" 1 "Dynamic bending light is working properly Normal operation mode Bending light is working properly" 0 "Dynamic bending light deactivated There is no problem but for some reasons eg daylight present the bending" ;
VAL_ 2566749950 LeftHeadlampDynamicBendingLight 7 "Not available" 3 "Dynamic bending light failure Bending light does not work current position may affect oncoming traffic" 2 "Dynamic bending light fail safe position Bending light is damaged current position does not affect oncoming traffic" 1 "Dynamic bending light is working properly Normal operation mode Bending light is working properly" 0 "Dynamic bending light deactivated There is no problem but for some reasons eg daylight present the bending" ;
VAL_ 2566838782 AuxI_O13 3 "Not available" 2 "Error" 1 "Auxiliary channel on" 0 "Auxiliary channel off" ;
VAL_ 2566838782 AuxI_O14 3 "Not available" 2 "Error" 1 "Auxiliary channel on" 0 "Auxiliary channel off" ;
VAL_ 2566838782 AuxI_O15 3 "Not available" 2 "Error" 1 "Auxiliary channel on" 0 "Auxiliary channel off" ;
VAL_ 2566838782 AuxI_O16 3 "Not available" 2 "Error" 1 "Auxiliary channel on" 0 "Auxiliary channel off" ;
VAL_ 2566838782 AuxI_O09 3 "Not available" 2 "Error" 1 "Auxiliary channel on" 0 "Auxiliary channel off" ;
VAL_ 2566838782 AuxI_O10 3 "Not available" 2 "Error" 1 "Auxiliary channel on" 0 "Auxiliary channel off" ;
VAL_ 2566838782 AuxI_O11 3 "Not available" 2 "Error" 1 "Auxiliary channel on" 0 "Auxiliary channel off" ;
VAL_ 2566838782 AuxI_O12 3 "Not available" 2 "Error" 1 "Auxiliary channel on" 0 "Auxiliary channel off" ;
VAL_ 2566838782 AuxI_O05 3 "Not available" 2 "Error" 1 "Auxiliary channel on" 0 "Auxiliary channel off" ;
VAL_ 2566838782 AuxI_O06 3 "Not available" 2 "Error" 1 "Auxiliary channel on" 0 "Auxiliary channel off" ;
VAL_ 2566838782 AuxI_O07 3 "Not available" 2 "Error" 1 "Auxiliary channel on" 0 "Auxiliary channel off" ;
VAL_ 2566838782 AuxI_O08 3 "Not available" 2 "Error" 1 "Auxiliary channel on" 0 "Auxiliary channel off" ;
VAL_ 2566838782 AuxI_O01 3 "Not available" 2 "Error" 1 "Auxiliary channel on" 0 "Auxiliary channel off" ;
VAL_ 2566838782 AuxI_O02 3 "Not available" 2 "Error" 1 "Auxiliary channel on" 0 "Auxiliary channel off" ;
VAL_ 2566838782 AuxI_O03 3 "Not available" 2 "Error" 1 "Auxiliary channel on" 0 "Auxiliary channel off" ;
VAL_ 2566838782 AuxI_O04 3 "Not available" 2 "Error" 1 "Auxiliary channel on" 0 "Auxiliary channel off" ;
VAL_ 2561146622 AuxI_O45 3 "Not Available or Take No Action depending on application" 2 "Error Indicator or Not Used  depending on application" 1 "Auxiliary channel on" 0 "Auxiliary channel off" ;
VAL_ 2561146622 AuxI_O46 3 "Not Available or Take No Action depending on application" 2 "Error Indicator or Not Used  depending on application" 1 "Auxiliary channel on" 0 "Auxiliary channel off" ;
VAL_ 2561146622 AuxI_O47 3 "Not Available or Take No Action depending on application" 2 "Error Indicator or Not Used  depending on application" 1 "Auxiliary channel on" 0 "Auxiliary channel off" ;
VAL_ 2561146622 AuxI_O48 3 "Not Available or Take No Action depending on application" 2 "Error Indicator or Not Used  depending on application" 1 "Auxiliary channel on" 0 "Auxiliary channel off" ;
VAL_ 2561146622 AuxI_O41 3 "Not Available or Take No Action depending on application" 2 "Error Indicator or Not Used  depending on application" 1 "Auxiliary channel on" 0 "Auxiliary channel off" ;
VAL_ 2561146622 AuxI_O42 3 "Not Available or Take No Action depending on application" 2 "Error Indicator or Not Used  depending on application" 1 "Auxiliary channel on" 0 "Auxiliary channel off" ;
VAL_ 2561146622 AuxI_O43 3 "Not Available or Take No Action depending on application" 2 "Error Indicator or Not Used  depending on application" 1 "Auxiliary channel on" 0 "Auxiliary channel off" ;
VAL_ 2561146622 AuxI_O44 3 "Not Available or Take No Action depending on application" 2 "Error Indicator or Not Used  depending on application" 1 "Auxiliary channel on" 0 "Auxiliary channel off" ;
VAL_ 2561146622 AuxI_O37 3 "Not Available or Take No Action depending on application" 2 "Error Indicator or Not Used  depending on application" 1 "Auxiliary channel on" 0 "Auxiliary channel off" ;
VAL_ 2561146622 AuxI_O38 3 "Not Available or Take No Action depending on application" 2 "Error Indicator or Not Used  depending on application" 1 "Auxiliary channel on" 0 "Auxiliary channel off" ;
VAL_ 2561146622 AuxI_O39 3 "Not Available or Take No Action depending on application" 2 "Error Indicator or Not Used  depending on application" 1 "Auxiliary channel on" 0 "Auxiliary channel off" ;
VAL_ 2561146622 AuxI_O40 3 "Not Available or Take No Action depending on application" 2 "Error Indicator or Not Used  depending on application" 1 "Auxiliary channel on" 0 "Auxiliary channel off" ;
VAL_ 2561146622 AuxI_O33 3 "Not Available or Take No Action depending on application" 2 "Error Indicator or Not Used  depending on application" 1 "Auxiliary channel on" 0 "Auxiliary channel off" ;
VAL_ 2561146622 AuxI_O34 3 "Not Available or Take No Action depending on application" 2 "Error Indicator or Not Used  depending on application" 1 "Auxiliary channel on" 0 "Auxiliary channel off" ;
VAL_ 2561146622 AuxI_O35 3 "Not Available or Take No Action depending on application" 2 "Error Indicator or Not Used  depending on application" 1 "Auxiliary channel on" 0 "Auxiliary channel off" ;
VAL_ 2561146622 AuxI_O36 3 "Not Available or Take No Action depending on application" 2 "Error Indicator or Not Used  depending on application" 1 "Auxiliary channel on" 0 "Auxiliary channel off" ;
VAL_ 2561146622 AuxI_O29 3 "Not Available or Take No Action depending on application" 2 "Error Indicator or Not Used  depending on application" 1 "Auxiliary channel on" 0 "Auxiliary channel off" ;
VAL_ 2561146622 AuxI_O30 3 "Not Available or Take No Action depending on application" 2 "Error Indicator or Not Used  depending on application" 1 "Auxiliary channel on" 0 "Auxiliary channel off" ;
VAL_ 2561146622 AuxI_O31 3 "Not Available or Take No Action depending on application" 2 "Error Indicator or Not Used  depending on application" 1 "Auxiliary channel on" 0 "Auxiliary channel off" ;
VAL_ 2561146622 AuxI_O32 3 "Not Available or Take No Action depending on application" 2 "Error Indicator or Not Used  depending on application" 1 "Auxiliary channel on" 0 "Auxiliary channel off" ;
VAL_ 2561146622 AuxI_O25 3 "Not Available or Take No Action depending on application" 2 "Error Indicator or Not Used  depending on application" 1 "Auxiliary channel on" 0 "Auxiliary channel off" ;
VAL_ 2561146622 AuxI_O26 3 "Not Available or Take No Action depending on application" 2 "Error Indicator or Not Used  depending on application" 1 "Auxiliary channel on" 0 "Auxiliary channel off" ;
VAL_ 2561146622 AuxI_O27 3 "Not Available or Take No Action depending on application" 2 "Error Indicator or Not Used  depending on application" 1 "Auxiliary channel on" 0 "Auxiliary channel off" ;
VAL_ 2561146622 AuxI_O28 3 "Not Available or Take No Action depending on application" 2 "Error Indicator or Not Used  depending on application" 1 "Auxiliary channel on" 0 "Auxiliary channel off" ;
VAL_ 2561146622 AuxI_O21 3 "Not Available or Take No Action depending on application" 2 "Error Indicator or Not Used  depending on application" 1 "Auxiliary channel on" 0 "Auxiliary channel off" ;
VAL_ 2561146622 AuxI_O22 3 "Not Available or Take No Action depending on application" 2 "Error Indicator or Not Used  depending on application" 1 "Auxiliary channel on" 0 "Auxiliary channel off" ;
VAL_ 2561146622 AuxI_O23 3 "Not Available or Take No Action depending on application" 2 "Error Indicator or Not Used  depending on application" 1 "Auxiliary channel on" 0 "Auxiliary channel off" ;
VAL_ 2561146622 AuxI_O24 3 "Not Available or Take No Action depending on application" 2 "Error Indicator or Not Used  depending on application" 1 "Auxiliary channel on" 0 "Auxiliary channel off" ;
VAL_ 2561146622 AuxI_O17 3 "Not Available or Take No Action depending on application" 2 "Error Indicator or Not Used  depending on application" 1 "Auxiliary channel on" 0 "Auxiliary channel off" ;
VAL_ 2561146622 AuxI_O18 3 "Not Available or Take No Action depending on application" 2 "Error Indicator or Not Used  depending on application" 1 "Auxiliary channel on" 0 "Auxiliary channel off" ;
VAL_ 2561146622 AuxI_O19 3 "Not Available or Take No Action depending on application" 2 "Error Indicator or Not Used  depending on application" 1 "Auxiliary channel on" 0 "Auxiliary channel off" ;
VAL_ 2561146622 AuxI_O20 3 "Not Available or Take No Action depending on application" 2 "Error Indicator or Not Used  depending on application" 1 "Auxiliary channel on" 0 "Auxiliary channel off" ;
VAL_ 2561081086 AuxI_O77 3 "Not Available or Take No Action depending on application" 2 "Error Indicator or Not Used  depending on application" 1 "Auxiliary channel on" 0 "Auxiliary channel off" ;
VAL_ 2561081086 AuxI_O78 3 "Not Available or Take No Action depending on application" 2 "Error Indicator or Not Used  depending on application" 1 "Auxiliary channel on" 0 "Auxiliary channel off" ;
VAL_ 2561081086 AuxI_O79 3 "Not Available or Take No Action depending on application" 2 "Error Indicator or Not Used  depending on application" 1 "Auxiliary channel on" 0 "Auxiliary channel off" ;
VAL_ 2561081086 AuxI_O80 3 "Not Available or Take No Action depending on application" 2 "Error Indicator or Not Used  depending on application" 1 "Auxiliary channel on" 0 "Auxiliary channel off" ;
VAL_ 2561081086 AuxI_O73 3 "Not Available or Take No Action depending on application" 2 "Error Indicator or Not Used  depending on application" 1 "Auxiliary channel on" 0 "Auxiliary channel off" ;
VAL_ 2561081086 AuxI_O74 3 "Not Available or Take No Action depending on application" 2 "Error Indicator or Not Used  depending on application" 1 "Auxiliary channel on" 0 "Auxiliary channel off" ;
VAL_ 2561081086 AuxI_O75 3 "Not Available or Take No Action depending on application" 2 "Error Indicator or Not Used  depending on application" 1 "Auxiliary channel on" 0 "Auxiliary channel off" ;
VAL_ 2561081086 AuxI_O76 3 "Not Available or Take No Action depending on application" 2 "Error Indicator or Not Used  depending on application" 1 "Auxiliary channel on" 0 "Auxiliary channel off" ;
VAL_ 2561081086 AuxI_O69 3 "Not Available or Take No Action depending on application" 2 "Error Indicator or Not Used  depending on application" 1 "Auxiliary channel on" 0 "Auxiliary channel off" ;
VAL_ 2561081086 AuxI_O70 3 "Not Available or Take No Action depending on application" 2 "Error Indicator or Not Used  depending on application" 1 "Auxiliary channel on" 0 "Auxiliary channel off" ;
VAL_ 2561081086 AuxI_O71 3 "Not Available or Take No Action depending on application" 2 "Error Indicator or Not Used  depending on application" 1 "Auxiliary channel on" 0 "Auxiliary channel off" ;
VAL_ 2561081086 AuxI_O72 3 "Not Available or Take No Action depending on application" 2 "Error Indicator or Not Used  depending on application" 1 "Auxiliary channel on" 0 "Auxiliary channel off" ;
VAL_ 2561081086 AuxI_O65 3 "Not Available or Take No Action depending on application" 2 "Error Indicator or Not Used  depending on application" 1 "Auxiliary channel on" 0 "Auxiliary channel off" ;
VAL_ 2561081086 AuxI_O66 3 "Not Available or Take No Action depending on application" 2 "Error Indicator or Not Used  depending on application" 1 "Auxiliary channel on" 0 "Auxiliary channel off" ;
VAL_ 2561081086 AuxI_O67 3 "Not Available or Take No Action depending on application" 2 "Error Indicator or Not Used  depending on application" 1 "Auxiliary channel on" 0 "Auxiliary channel off" ;
VAL_ 2561081086 AuxI_O68 3 "Not Available or Take No Action depending on application" 2 "Error Indicator or Not Used  depending on application" 1 "Auxiliary channel on" 0 "Auxiliary channel off" ;
VAL_ 2561081086 AuxI_O61 3 "Not Available or Take No Action depending on application" 2 "Error Indicator or Not Used  depending on application" 1 "Auxiliary channel on" 0 "Auxiliary channel off" ;
VAL_ 2561081086 AuxI_O62 3 "Not Available or Take No Action depending on application" 2 "Error Indicator or Not Used  depending on application" 1 "Auxiliary channel on" 0 "Auxiliary channel off" ;
VAL_ 2561081086 AuxI_O63 3 "Not Available or Take No Action depending on application" 2 "Error Indicator or Not Used  depending on application" 1 "Auxiliary channel on" 0 "Auxiliary channel off" ;
VAL_ 2561081086 AuxI_O64 3 "Not Available or Take No Action depending on application" 2 "Error Indicator or Not Used  depending on application" 1 "Auxiliary channel on" 0 "Auxiliary channel off" ;
VAL_ 2561081086 AuxI_O57 3 "Not Available or Take No Action depending on application" 2 "Error Indicator or Not Used  depending on application" 1 "Auxiliary channel on" 0 "Auxiliary channel off" ;
VAL_ 2561081086 AuxI_O58 3 "Not Available or Take No Action depending on application" 2 "Error Indicator or Not Used  depending on application" 1 "Auxiliary channel on" 0 "Auxiliary channel off" ;
VAL_ 2561081086 AuxI_O59 3 "Not Available or Take No Action depending on application" 2 "Error Indicator or Not Used  depending on application" 1 "Auxiliary channel on" 0 "Auxiliary channel off" ;
VAL_ 2561081086 AuxI_O60 3 "Not Available or Take No Action depending on application" 2 "Error Indicator or Not Used  depending on application" 1 "Auxiliary channel on" 0 "Auxiliary channel off" ;
VAL_ 2561081086 AuxI_O53 3 "Not Available or Take No Action depending on application" 2 "Error Indicator or Not Used  depending on application" 1 "Auxiliary channel on" 0 "Auxiliary channel off" ;
VAL_ 2561081086 AuxI_O54 3 "Not Available or Take No Action depending on application" 2 "Error Indicator or Not Used  depending on application" 1 "Auxiliary channel on" 0 "Auxiliary channel off" ;
VAL_ 2561081086 AuxI_O55 3 "Not Available or Take No Action depending on application" 2 "Error Indicator or Not Used  depending on application" 1 "Auxiliary channel on" 0 "Auxiliary channel off" ;
VAL_ 2561081086 AuxI_O56 3 "Not Available or Take No Action depending on application" 2 "Error Indicator or Not Used  depending on application" 1 "Auxiliary channel on" 0 "Auxiliary channel off" ;
VAL_ 2561081086 AuxI_O49 3 "Not Available or Take No Action depending on application" 2 "Error Indicator or Not Used  depending on application" 1 "Auxiliary channel on" 0 "Auxiliary channel off" ;
VAL_ 2561081086 AuxI_O50 3 "Not Available or Take No Action depending on application" 2 "Error Indicator or Not Used  depending on application" 1 "Auxiliary channel on" 0 "Auxiliary channel off" ;
VAL_ 2561081086 AuxI_O51 3 "Not Available or Take No Action depending on application" 2 "Error Indicator or Not Used  depending on application" 1 "Auxiliary channel on" 0 "Auxiliary channel off" ;
VAL_ 2561081086 AuxI_O52 3 "Not Available or Take No Action depending on application" 2 "Error Indicator or Not Used  depending on application" 1 "Auxiliary channel on" 0 "Auxiliary channel off" ;
VAL_ 2561015550 AuxI_O109 3 "Not Available or Take No Action depending on application" 2 "Error Indicator or Not Used  depending on application" 1 "Auxiliary channel on" 0 "Auxiliary channel off" ;
VAL_ 2561015550 AuxI_O110 3 "Not Available or Take No Action depending on application" 2 "Error Indicator or Not Used  depending on application" 1 "Auxiliary channel on" 0 "Auxiliary channel off" ;
VAL_ 2561015550 AuxI_O111 3 "Not Available or Take No Action depending on application" 2 "Error Indicator or Not Used  depending on application" 1 "Auxiliary channel on" 0 "Auxiliary channel off" ;
VAL_ 2561015550 AuxI_O112 3 "Not Available or Take No Action depending on application" 2 "Error Indicator or Not Used  depending on application" 1 "Auxiliary channel on" 0 "Auxiliary channel off" ;
VAL_ 2561015550 AuxI_O105 3 "Not Available or Take No Action depending on application" 2 "Error Indicator or Not Used  depending on application" 1 "Auxiliary channel on" 0 "Auxiliary channel off" ;
VAL_ 2561015550 AuxI_O106 3 "Not Available or Take No Action depending on application" 2 "Error Indicator or Not Used  depending on application" 1 "Auxiliary channel on" 0 "Auxiliary channel off" ;
VAL_ 2561015550 AuxI_O107 3 "Not Available or Take No Action depending on application" 2 "Error Indicator or Not Used  depending on application" 1 "Auxiliary channel on" 0 "Auxiliary channel off" ;
VAL_ 2561015550 AuxI_O108 3 "Not Available or Take No Action depending on application" 2 "Error Indicator or Not Used  depending on application" 1 "Auxiliary channel on" 0 "Auxiliary channel off" ;
VAL_ 2561015550 AuxI_O101 2 "Error Indicator or Not Used  depending on application" 1 "Auxiliary channel on" 0 "Auxiliary channel off" 3 "Not Available or Take No Action depending on application" ;
VAL_ 2561015550 AuxI_O102 3 "Not Available or Take No Action depending on application" 2 "Error Indicator or Not Used  depending on application" 1 "Auxiliary channel on" 0 "Auxiliary channel off" ;
VAL_ 2561015550 AuxI_O103 3 "Not Available or Take No Action depending on application" 2 "Error Indicator or Not Used  depending on application" 1 "Auxiliary channel on" 0 "Auxiliary channel off" ;
VAL_ 2561015550 AuxI_O104 3 "Not Available or Take No Action depending on application" 2 "Error Indicator or Not Used  depending on application" 1 "Auxiliary channel on" 0 "Auxiliary channel off" ;
VAL_ 2561015550 AuxI_O97 3 "Not Available or Take No Action depending on application" 2 "Error Indicator or Not Used  depending on application" 1 "Auxiliary channel on" 0 "Auxiliary channel off" ;
VAL_ 2561015550 AuxI_O98 3 "Not Available or Take No Action depending on application" 2 "Error Indicator or Not Used  depending on application" 1 "Auxiliary channel on" 0 "Auxiliary channel off" ;
VAL_ 2561015550 AuxI_O99 3 "Not Available or Take No Action depending on application" 2 "Error Indicator or Not Used  depending on application" 1 "Auxiliary channel on" 0 "Auxiliary channel off" ;
VAL_ 2561015550 AuxI_O100 3 "Not Available or Take No Action depending on application" 2 "Error Indicator or Not Used  depending on application" 1 "Auxiliary channel on" 0 "Auxiliary channel off" ;
VAL_ 2561015550 AuxI_O93 3 "Not Available or Take No Action depending on application" 2 "Error Indicator or Not Used  depending on application" 1 "Auxiliary channel on" 0 "Auxiliary channel off" ;
VAL_ 2561015550 AuxI_O94 3 "Not Available or Take No Action depending on application" 2 "Error Indicator or Not Used  depending on application" 1 "Auxiliary channel on" 0 "Auxiliary channel off" ;
VAL_ 2561015550 AuxI_O95 3 "Not Available or Take No Action depending on application" 2 "Error Indicator or Not Used  depending on application" 1 "Auxiliary channel on" 0 "Auxiliary channel off" ;
VAL_ 2561015550 AuxI_O96 3 "Not Available or Take No Action depending on application" 2 "Error Indicator or Not Used  depending on application" 1 "Auxiliary channel on" 0 "Auxiliary channel off" ;
VAL_ 2561015550 AuxI_O89 3 "Not Available or Take No Action depending on application" 2 "Error Indicator or Not Used  depending on application" 1 "Auxiliary channel on" 0 "Auxiliary channel off" ;
VAL_ 2561015550 AuxI_O90 3 "Not Available or Take No Action depending on application" 2 "Error Indicator or Not Used  depending on application" 1 "Auxiliary channel on" 0 "Auxiliary channel off" ;
VAL_ 2561015550 AuxI_O91 3 "Not Available or Take No Action depending on application" 2 "Error Indicator or Not Used  depending on application" 1 "Auxiliary channel on" 0 "Auxiliary channel off" ;
VAL_ 2561015550 AuxI_O92 3 "Not Available or Take No Action depending on application" 2 "Error Indicator or Not Used  depending on application" 1 "Auxiliary channel on" 0 "Auxiliary channel off" ;
VAL_ 2561015550 AuxI_O85 3 "Not Available or Take No Action depending on application" 2 "Error Indicator or Not Used  depending on application" 1 "Auxiliary channel on" 0 "Auxiliary channel off" ;
VAL_ 2561015550 AuxI_O86 3 "Not Available or Take No Action depending on application" 2 "Error Indicator or Not Used  depending on application" 1 "Auxiliary channel on" 0 "Auxiliary channel off" ;
VAL_ 2561015550 AuxI_O87 3 "Not Available or Take No Action depending on application" 2 "Error Indicator or Not Used  depending on application" 1 "Auxiliary channel on" 0 "Auxiliary channel off" ;
VAL_ 2561015550 AuxI_O88 3 "Not Available or Take No Action depending on application" 2 "Error Indicator or Not Used  depending on application" 1 "Auxiliary channel on" 0 "Auxiliary channel off" ;
VAL_ 2561015550 AuxI_O81 3 "Not Available or Take No Action depending on application" 2 "Error Indicator or Not Used  depending on application" 1 "Auxiliary channel on" 0 "Auxiliary channel off" ;
VAL_ 2561015550 AuxI_O82 3 "Not Available or Take No Action depending on application" 2 "Error Indicator or Not Used  depending on application" 1 "Auxiliary channel on" 0 "Auxiliary channel off" ;
VAL_ 2561015550 AuxI_O83 3 "Not Available or Take No Action depending on application" 2 "Error Indicator or Not Used  depending on application" 1 "Auxiliary channel on" 0 "Auxiliary channel off" ;
VAL_ 2561015550 AuxI_O84 3 "Not Available or Take No Action depending on application" 2 "Error Indicator or Not Used  depending on application" 1 "Auxiliary channel on" 0 "Auxiliary channel off" ;
VAL_ 2566746622 TrailerBrakeStrokeAxle5Right 4 "Reserved" 7 "Not available" 6 "Sensor error" 5 "Reserved" 3 "Dragging brake" 2 "Overstroke" 1 "Nonfunctioning" 0 "OK Normal operation" ;
VAL_ 2566746622 TrailerBrakeStrokeAxle5Left 4 "Reserved" 7 "Not available" 6 "Sensor error" 5 "Reserved" 3 "Dragging brake" 2 "Overstroke" 1 "Nonfunctioning" 0 "OK Normal operation" ;
VAL_ 2566746622 TrailerBrakeStrokeAxle4Right 4 "Reserved" 7 "Not available" 6 "Sensor error" 5 "Reserved" 3 "Dragging brake" 2 "Overstroke" 1 "Nonfunctioning" 0 "OK Normal operation" ;
VAL_ 2566746622 TrailerBrakeStrokeAxle4Left 4 "Reserved" 7 "Not available" 6 "Sensor error" 5 "Reserved" 3 "Dragging brake" 2 "Overstroke" 1 "Nonfunctioning" 0 "OK Normal operation" ;
VAL_ 2566746622 TrailerBrakeStrokeAxle3Right 4 "Reserved" 7 "Not available" 6 "Sensor error" 5 "Reserved" 3 "Dragging brake" 2 "Overstroke" 1 "Nonfunctioning" 0 "OK Normal operation" ;
VAL_ 2566746622 TrailerBrakeStrokeAxle3Left 4 "Reserved" 7 "Not available" 6 "Sensor error" 5 "Reserved" 3 "Dragging brake" 2 "Overstroke" 1 "Nonfunctioning" 0 "OK Normal operation" ;
VAL_ 2566746622 TrailerBrakeStrokeAxle2Right 4 "Reserved" 7 "Not available" 6 "Sensor error" 5 "Reserved" 3 "Dragging brake" 2 "Overstroke" 1 "Nonfunctioning" 0 "OK Normal operation" ;
VAL_ 2566746622 TrailerBrakeStrokeAxle2Left 4 "Reserved" 7 "Not available" 6 "Sensor error" 5 "Reserved" 3 "Dragging brake" 2 "Overstroke" 1 "Nonfunctioning" 0 "OK Normal operation" ;
VAL_ 2566746622 TrailerBrakeStrokeAxle1Right 4 "Reserved" 7 "Not available" 6 "Sensor error" 5 "Reserved" 3 "Dragging brake" 2 "Overstroke" 1 "Nonfunctioning" 0 "OK Normal operation" ;
VAL_ 2566746622 TrailerBrakeStrokeAxle1Left 4 "Reserved" 7 "Not available" 6 "Sensor error" 5 "Reserved" 3 "Dragging brake" 2 "Overstroke" 1 "Nonfunctioning" 0 "OK Normal operation" ;
VAL_ 2566746622 TractorBrakeStrokeAxle5Right 4 "Reserved" 7 "Not available" 6 "Sensor error" 5 "Reserved" 3 "Dragging brake" 2 "Overstroke" 1 "Nonfunctioning" 0 "OK Normal operation" ;
VAL_ 2566746622 TractorBrakeStrokeAxle5Left 4 "Reserved" 7 "Not available" 6 "Sensor error" 5 "Reserved" 3 "Dragging brake" 2 "Overstroke" 1 "Nonfunctioning" 0 "OK Normal operation" ;
VAL_ 2566746622 TractorBrakeStrokeAxle4Right 4 "Reserved" 7 "Not available" 6 "Sensor error" 5 "Reserved" 3 "Dragging brake" 2 "Overstroke" 1 "Nonfunctioning" 0 "OK Normal operation" ;
VAL_ 2566746622 TractorBrakeStrokeAxle4Left 4 "Reserved" 7 "Not available" 6 "Sensor error" 5 "Reserved" 3 "Dragging brake" 2 "Overstroke" 1 "Nonfunctioning" 0 "OK Normal operation" ;
VAL_ 2566746622 TractorBrakeStrokeAxle3Right 4 "Reserved" 7 "Not available" 6 "Sensor error" 5 "Reserved" 3 "Dragging brake" 2 "Overstroke" 1 "Nonfunctioning" 0 "OK Normal operation" ;
VAL_ 2566746622 TractorBrakeStrokeAxle3Left 4 "Reserved" 7 "Not available" 6 "Sensor error" 5 "Reserved" 3 "Dragging brake" 2 "Overstroke" 1 "Nonfunctioning" 0 "OK Normal operation" ;
VAL_ 2566746622 TractorBrakeStrokeAxle2Right 4 "Reserved" 7 "Not available" 6 "Sensor error" 5 "Reserved" 3 "Dragging brake" 2 "Overstroke" 1 "Nonfunctioning" 0 "OK Normal operation" ;
VAL_ 2566746622 TractorBrakeStrokeAxle2Left 4 "Reserved" 7 "Not available" 6 "Sensor error" 5 "Reserved" 3 "Dragging brake" 2 "Overstroke" 1 "Nonfunctioning" 0 "OK Normal operation" ;
VAL_ 2566746622 TractorBrakeStrokeAxle1Right 4 "Reserved" 7 "Not available" 6 "Sensor error" 5 "Reserved" 3 "Dragging brake" 2 "Overstroke" 1 "Nonfunctioning" 0 "OK Normal operation" ;
VAL_ 2566746622 TractorBrakeStrokeAxle1Left 4 "Reserved" 7 "Not available" 6 "Sensor error" 5 "Reserved" 3 "Dragging brake" 2 "Overstroke" 1 "Nonfunctioning" 0 "OK Normal operation" ;
VAL_ 2566827774 AirCompressorStatus 3 "Not available" 2 "Error indicator" 1 "Compressor active" 0 "Compressor not active" ;
VAL_ 2566803966 RequestedACCDistanceMode 7 "not available" 6 "error condition" 5 "not defined" 4 "Requested ACC Distance Mode 5 shortest distance" 3 "Requested ACC Distance Mode 4" 2 "Requested ACC Distance Mode 3" 1 "Requested ACC Distance Mode 2" 0 "Requested ACC Distance Mode 1 largest distance" ;
VAL_ 2566803966 ACCUsageDemand 3 "dont care" 2 "reserved" 1 "driver demand for using ACC distance keeping control" 0 "driver demand for not using ACC distance keeping control" ;
VAL_ 2432593918 ForwardCollisionWarning 3 "not available" 2 "Error indicator" 1 "Collision is imminent" 0 "No warning" ;
VAL_ 2432593918 ACCDistanceAlertSignal 3 "Take no action" 2 "Reserved" 1 "ACC DAS Active" 0 "ACC DAS Not Active" ;
VAL_ 2432593918 ACCSystemShutoffWarning 3 "Take no action" 2 "Reserved" 1 "ACC SSOW Active" 0 "ACC SSOW Not Active" ;
VAL_ 2432593918 ACCTargetDetected 3 "Take no action" 2 "Reserved" 1 "Target detected" 0 "No targets detected" ;
VAL_ 2432593918 AdptiveCruiseCtrlSetDistanceMode 7 "Not available/not valid" 6 "Error condition" 5 "Conventional cruise control mode" 4 "ACC Distance mode 5 shortest distance" 3 "ACC Distance mode 4" 2 "ACC Distance mode 3" 1 "ACC Distance mode 2" 0 "ACC Distance mode 1 largest distance" ;
VAL_ 2432593918 AdaptiveCruiseCtrlMode 7 "Not available/not valid" 6 "Disabled or error condition" 5 "Finish mode" 4 "Hold mode" 3 "Overtake mode" 2 "Distance control active" 1 "Speed control active" 0 "Off Standby enabled ready for activation" ;
VAL_ 2364079870 ControlByte 3 "CannotRespond" 2 "AccessDenied" 1 "NACK" 0 "ACK" ;
VAL_ 2566803198 Status2OfDoors 3 "not available" 2 "error" 1 "at least 1 bus door enabled" 0 "all bus doors are disabled" ;
VAL_ 2566803198 Ramp_WheelChairLiftPos 3 "Not available" 2 "Error" 1 "Outside bus" 0 "Inside bus" ;
VAL_ 2566803198 PosOfDoors 15 "Not available" 14 "Error" 2 "All doors closed" 1 "Closing last door" 0 "At least 1 door is open" ;
VAL_ 2565870334 FifthWheelRollWarningIndicator 3 "Not Available" 2 "error" 1 "Limit exceeded" 0 "Limit not exceeded" ;
VAL_ 2566762238 FifthWheelSliderLockIndicator 3 "Not Available" 2 "Error" 1 "Locked" 0 "Not Locked" ;
VAL_ 2566762238 FfthWhlLockCoupleStatusIndicator 3 "Not Available" 2 "Error" 1 "Successful couple detected" 0 "Incomplete or bad couple truck should not be moved" ;
VAL_ 2566762238 FfthWhlLckReadyToCoupleIndicator 3 "Not Available" 2 "Error" 1 "Lock open ready to couple" 0 "Lock not open not ready to couple" ;
VAL_ 2566762238 FifthWheelErrorStatus 13 "13  Not Used" 12 "12  Not Used" 11 "11  Not Used" 10 "Not Used" 4 "4  Not Used" 3 "3  Not Used" 15 "15  Not available" 9 "9  Kingpin / Lock Open Handle Pulled" 8 "8  Kingpin Missing More Than 5 Seconds" 7 "7  Coupling Timing Error" 6 "6  Coupling Sequence Error / Kingpin" 5 "5  Coupling Sequence Error" 14 "14  Not Used" 2 "2  Kingpin / Locks Open at Startup" 1 "Locks Closed / No Kingpin at Startup" 0 "Improper Couple" ;
VAL_ 2364543998 PitchAndRollCompensated 3 "Not Available" 2 "Error" 1 "Compensation On" 0 "Compensation Off" ;
VAL_ 2364543998 PitchRateFigureOfMerit 3 "Not available" 2 "Error" 1 "Pitch rate degraded.  Data is suspect due to environmental conditions." 0 "Pitch rate fully functional.  Data is within sensor specification.   " ;
VAL_ 2364543998 RollAngleFigureOfMerit 3 "Not available" 2 "Error" 1 "Roll angle degraded.  Data is suspect due to environmental conditions." 0 "Roll angle fully functional.  Data is within sensor specification.   " ;
VAL_ 2364543998 PitchAngleFigureOfMerit 3 "Not available" 2 "Error" 1 "Pitch angle degraded.  Data is suspect due to environmental conditions." 0 "Pitch angle fully functional.  Data is within sensor specification. " ;
VAL_ 2566846718 TransOilLevel1MeasurementStatus 15 "Not available" 14 "Error" 13 "Conditions not valid  Other" 12 "Not defined" 9 "Conditions not valid  No request for reading" 8 "Conditions not valid  Engine speed too high" 7 "Conditions not valid  Engine speed too low" 6 "Conditions not valid  Vehicle not level" 5 "Conditions not valid  Vehicle moving output shaft speed too high" 4 "Conditions not valid  Transmission fluid temperature too high" 3 "Conditions not valid  Transmission fluid temperature too low" 2 "Conditions not valid  Transmission in gear" 1 "Conditions not valid  Settling timer still counting down" 0 "Conditions valid for transmission oil level measurement" 11 "Not defined" 10 "Not defined" ;
VAL_ 2566846718 TransOilLevel1CountdownTimer 15 "Not Available" 14 "Error" 13 "Thirteen minutes" 12 "Twelve minutes" 11 "Eleven minutes" 10 "Ten minutes" 9 "Nine minutes" 8 "Eight minutes" 7 "Seven minutes" 6 "Six minutes" 5 "Five minutes" 4 "Four minutes" 3 "Three minutes" 2 "Two minutes" 1 "One minute" 0 "less than 1 minute" ;
VAL_ 2566760702 WrelessCommunicationNetworkType2 255 "Not Available" 254 "Error" 4 "Satellite network" 3 "Wireless LAN #2" 2 "Wireless LAN #1" 1 "Cellular network #2" 0 "Cellular network #1" ;
VAL_ 2566760702 NetworkAntennaStatus2 255 "Not Available" 254 "Error" 1 "On" 0 "Off" ;
VAL_ 2566760702 NetworkServiceStatus2 255 "Not Available" 254 "Error" 3 "Not Authorized to Operate on Service" 2 "Service not available" 1 "Roaming Service" 0 "Local Service" ;
VAL_ 2566760702 NetworkTransceiverStatus2 255 "Not Available" 254 "Error" 2 "Not Authorized to Operate on Network" 1 "On" 0 "Off" ;
VAL_ 2566760958 WrelessCommunicationNetworkType1 255 "Not Available" 254 "Error" 4 "Satellite network" 3 "Wireless LAN #2" 2 "Wireless LAN #1" 1 "Cellular network #2" 0 "Cellular network #1" ;
VAL_ 2566760958 NetworkAntennaStatus1 255 "Not Available" 254 "Error" 1 "On" 0 "Off" ;
VAL_ 2566760958 NetworkServiceStatus1 255 "Not Available" 254 "Error" 3 "Not Authorized to Operate on Service" 2 "Service not available" 1 "Roaming Service" 0 "Local Service" ;
VAL_ 2566760958 NetworkTransceiverStatus1 255 "Not Available" 254 "Error" 2 "Not Authorized to Operate on Network" 1 "On" 0 "Off" ;
VAL_ 2633869310 VoltageRegulatorEnabled 3 "NotAvailable" 2 "Error" 1 "RegulatingVoltage" 0 "NtRegulatingVoltageUnitDisabled" ;
VAL_ 2633869310 VoltageRegulatorSoftStartState 3 "NotAvailable" 2 "Error" 1 "SoftStartIsActive" 0 "SoftStartIsInactive" ;
VAL_ 2633869310 VltgRgltrUndrfrqncyCmpnstnEnbld 3 "NotAvailable" 2 "Error" 1 "UndrfrquencyCompensationEnabled" 0 "UndrfrqencyCompensationDisabled" ;
VAL_ 2633869310 VltgRgltrVAr_PwrFctrOprtingMode 7 "Not available" 6 "Reserved" 5 "Reserved" 4 "Reserved" 3 "Reserved" 2 "VAr regulation enabled" 1 "Power factor regulation enabled" 0 "VAr/Power Factor regulation disabled" ;
VAL_ 2633869310 VltgRglatorLoadCompensationMode 7 "Not available" 6 "Reserved" 5 "Reserved" 4 "Reserved" 3 "Reserved" 2 "IR line drop compensation enabled" 1 "Voltage droop compensation enabled" 0 "load compensation disabled" ;
